VERSION ""

NS_ :

BS_:

BU_: VMCU VGGSECUSystem TECU OBDScanT2 HMIIOM EMS ECUspare2 ECUspare1 DACU CIOM BBM

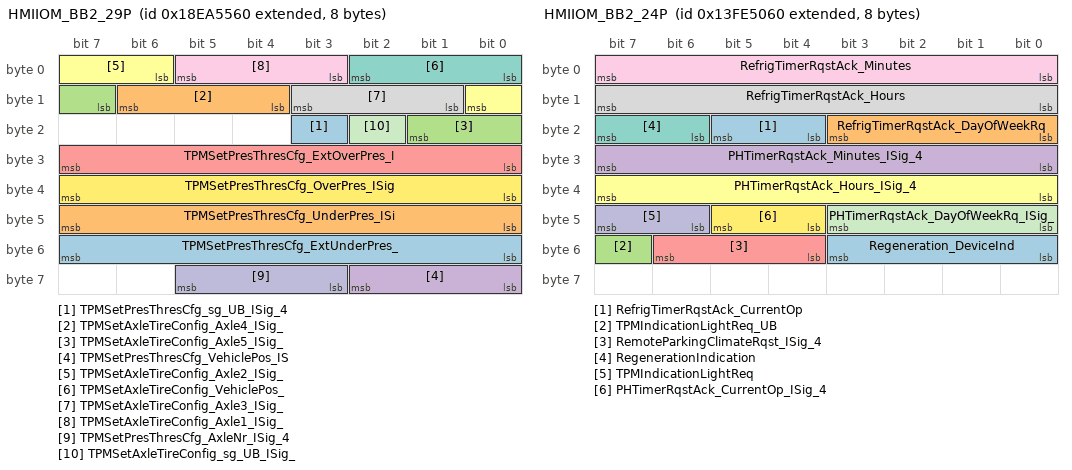
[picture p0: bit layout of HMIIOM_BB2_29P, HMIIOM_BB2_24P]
BO_ 2565494112 HMIIOM_BB2_29P: 8 HMIIOM
 SG_ TPMSetPresThresCfg_sg_UB_ISig_4 : 19|1@1+ (1,0) [0|0] ""  VMCU
 SG_ TPMSetAxleTireConfig_Axle4_ISig_ : 12|3@1+ (1,0) [0|0] ""  VMCU
 SG_ TPMSetAxleTireConfig_Axle5_ISig_ : 15|3@1+ (1,0) [0|0] ""  VMCU
 SG_ TPMSetPresThresCfg_VehiclePos_IS : 56|3@1+ (1,0) [0|0] ""  VMCU
 SG_ TPMSetPresThresCfg_ExtOverPres_I : 24|8@1+ (1,-125) [-125|130] "Percent"  VMCU
 SG_ TPMSetAxleTireConfig_Axle2_ISig_ : 6|3@1+ (1,0) [0|0] ""  VMCU
 SG_ TPMSetAxleTireConfig_VehiclePos_ : 0|3@1+ (1,0) [0|0] ""  VMCU
 SG_ TPMSetAxleTireConfig_Axle3_ISig_ : 9|3@1+ (1,0) [0|0] ""  VMCU
 SG_ TPMSetAxleTireConfig_Axle1_ISig_ : 3|3@1+ (1,0) [0|0] ""  VMCU
 SG_ TPMSetPresThresCfg_AxleNr_ISig_4 : 59|3@1+ (1,0) [0|0] ""  VMCU
 SG_ TPMSetAxleTireConfig_sg_UB_ISig_ : 18|1@1+ (1,0) [0|0] ""  VMCU
 SG_ TPMSetPresThresCfg_OverPres_ISig : 32|8@1+ (1,-125) [-125|130] "Percent"  VMCU
 SG_ TPMSetPresThresCfg_ExtUnderPres_ : 48|8@1+ (1,-125) [-125|130] "Percent"  VMCU
 SG_ TPMSetPresThresCfg_UnderPres_ISi : 40|8@1+ (1,-125) [-125|130] "Percent"  VMCU

BO_ 2582855520 HMIIOM_BB2_28S: 284 HMIIOM
 SG_ HillDataPkgTGW_ISig_4 : 0|2272@1+ (1,0) [0|0] ""  TECU

BO_ 2566356833 HMIIOM_BB2_27S_FCM: 8 CIOM
 SG_ HMIIOM_BB2_27S_FCS : 0|64@1+ (1,0) [0|0] ""  HMIIOM

BO_ 2566356832 HMIIOM_BB2_27S: 13 HMIIOM
 SG_ PHTimerTGWEvCmd_Timer3Minutes_IS : 64|8@1+ (1,0) [0|255] "min"  CIOM
 SG_ PHTimerTGWEvCmd_Timer1Temp_ISig_ : 8|5@1+ (1,0) [0|0] ""  CIOM
 SG_ PHTimerTGWEvCmd_Timer3StartDay_I : 40|4@1+ (1,0) [0|0] ""  CIOM
 SG_ PHTimerTGWEvCmd_Timer1Recur_ISig : 24|4@1+ (1,0) [0|0] ""  CIOM
 SG_ PHTimerTGWEvCmd_Timer3Recur_ISig : 28|4@1+ (1,0) [0|0] ""  CIOM
 SG_ PHTimerTGWEvCmd_Timer3Temp_ISig_ : 0|5@1+ (1,0) [0|0] ""  CIOM
 SG_ PHTimerTGWEvCmd_PhTimer3_cmd_ISi : 13|3@1+ (1,0) [0|0] ""  CIOM
 SG_ PHTimerTGWEvCmd_Timer1Hours_ISig : 56|8@1+ (1,0) [0|255] "h"  CIOM
 SG_ PHTimerTGWEvCmd_Timer1StartDay_I : 32|4@1+ (1,0) [0|0] ""  CIOM
 SG_ PHTimerTGWEvCmd_Timer2Minutes_IS : 72|8@1+ (1,0) [0|255] "min"  CIOM
 SG_ PHTimerTGWEvCmd_Timer2StartDay_I : 36|4@1+ (1,0) [0|0] ""  CIOM
 SG_ PHTimerTGWEvCmd_Timer2Temp_ISig_ : 16|5@1+ (1,0) [0|0] ""  CIOM
 SG_ PHTimerTGWEvCmd_Timer1Duration_I : 96|7@1+ (1,0) [0|127] "min"  CIOM
 SG_ PHTimerTGWEvCmd_Timer2Hours_ISig : 48|8@1+ (1,0) [0|255] "h"  CIOM
 SG_ PHTimerTGWEvCmd_Timer3Hours_ISig : 88|8@1+ (1,0) [0|255] "h"  CIOM
 SG_ PHTimerTGWEvCmd_PhTimer2_cmd_ISi : 21|3@1+ (1,0) [0|0] ""  CIOM
 SG_ PHTimerTGWEvCmd_Timer2Recur_ISig : 44|4@1+ (1,0) [0|0] ""  CIOM
 SG_ PHTimerTGWEvCmd_Timer1Minutes_IS : 80|8@1+ (1,0) [0|255] "min"  CIOM
 SG_ PHTimerTGWEvCmd_PhTimer1_cmd_ISi : 5|3@1+ (1,0) [0|0] ""  CIOM

BO_ 2515671136 HMIIOM_BB2_25P: 8 HMIIOM
 SG_ Trailer3LiftAxles_LiftAxle1Id_IS : 24|4@1+ (1,0) [0|15] "ID"  CIOM
 SG_ Trailer2LiftAxles_LiftAxle1Pos_I : 20|2@1+ (1,0) [0|0] ""  CIOM
 SG_ Trailer1LiftAxles_LiftAxle2Pos_I : 10|2@1+ (1,0) [0|0] ""  CIOM
 SG_ Trailer3LiftAxles_LiftAxle2Pos_I : 34|2@1+ (1,0) [0|0] ""  CIOM
 SG_ Trailer1LiftAxles_LiftAxle2Id_IS : 4|4@1+ (1,0) [0|15] "ID"  CIOM
 SG_ Trailer5LiftAxles_LiftAxle1Id_IS : 48|4@1+ (1,0) [0|15] "ID"  CIOM
 SG_ Trailer1LiftAxles_LiftAxle1Pos_I : 8|2@1+ (1,0) [0|0] ""  CIOM
 SG_ Trailer1LiftAxles_LiftAxle1Id_IS : 0|4@1+ (1,0) [0|15] "ID"  CIOM
 SG_ Trailer4LiftAxles_LiftAxle2Pos_I : 46|2@1+ (1,0) [0|0] ""  CIOM
 SG_ Trailer5LiftAxles_LiftAxle2Pos_I : 58|2@1+ (1,0) [0|0] ""  CIOM
 SG_ Trailer4LiftAxles_LiftAxle1Pos_I : 44|2@1+ (1,0) [0|0] ""  CIOM
 SG_ Trailer2LiftAxles_LiftAxle1Id_IS : 12|4@1+ (1,0) [0|15] "ID"  CIOM
 SG_ Trailer5LiftAxles_LiftAxle1Pos_I : 56|2@1+ (1,0) [0|0] ""  CIOM
 SG_ Trailer2LiftAxles_LiftAxle2Pos_I : 22|2@1+ (1,0) [0|0] ""  CIOM
 SG_ Trailer2LiftAxles_LiftAxle2Id_IS : 16|4@1+ (1,0) [0|15] "ID"  CIOM
 SG_ Trailer3LiftAxles_LiftAxle1Pos_I : 32|2@1+ (1,0) [0|0] ""  CIOM
 SG_ Trailer5LiftAxles_LiftAxle2Id_IS : 52|4@1+ (1,0) [0|15] "ID"  CIOM
 SG_ InhibRegeneration_DeviceInd : 62|2@1+ (1,0) [0|0] ""  CIOM
 SG_ Trailer4LiftAxles_LiftAxle1Id_IS : 36|4@1+ (1,0) [0|15] "ID"  CIOM
 SG_ Trailer3LiftAxles_LiftAxle2Id_IS : 28|4@1+ (1,0) [0|15] "ID"  CIOM
 SG_ Trailer4LiftAxles_LiftAxle2Id_IS : 40|4@1+ (1,0) [0|15] "ID"  CIOM

BO_ 2482917472 HMIIOM_BB2_24P: 8 HMIIOM
 SG_ RefrigTimerRqstAck_CurrentOp : 20|2@1+ (1,0) [0|0] ""  VMCU
 SG_ RefrigTimerRqstAck_DayOfWeekRq : 16|4@1+ (1,0) [0|0] ""  VMCU
 SG_ TPMIndicationLightReq_UB : 55|1@1+ (1,0) [0|0] ""  VMCU
 SG_ PHTimerRqstAck_Minutes_ISig_4 : 24|8@1+ (1,0) [0|255] "min"  CIOM
 SG_ RemoteParkingClimateRqst_ISig_4 : 52|3@1+ (1,0) [0|0] ""  CIOM
 SG_ PHTimerRqstAck_Hours_ISig_4 : 32|8@1+ (1,0) [0|255] "h"  CIOM
 SG_ RegenerationIndication : 22|2@1+ (1,0) [0|0] ""  CIOM
 SG_ RefrigTimerRqstAck_Hours : 8|8@1+ (1,0) [0|255] "h"  VMCU
 SG_ RefrigTimerRqstAck_Minutes : 0|8@1+ (1,0) [0|255] "min"  VMCU
 SG_ TPMIndicationLightReq : 46|2@1+ (1,0) [0|0] ""  VMCU
 SG_ PHTimerRqstAck_DayOfWeekRq_ISig_ : 40|4@1+ (1,0) [0|0] ""  CIOM
 SG_ PHTimerRqstAck_CurrentOp_ISig_4 : 44|2@1+ (1,0) [0|0] ""  CIOM
 SG_ Regeneration_DeviceInd : 48|4@1+ (1,0) [0|0] ""  CIOM

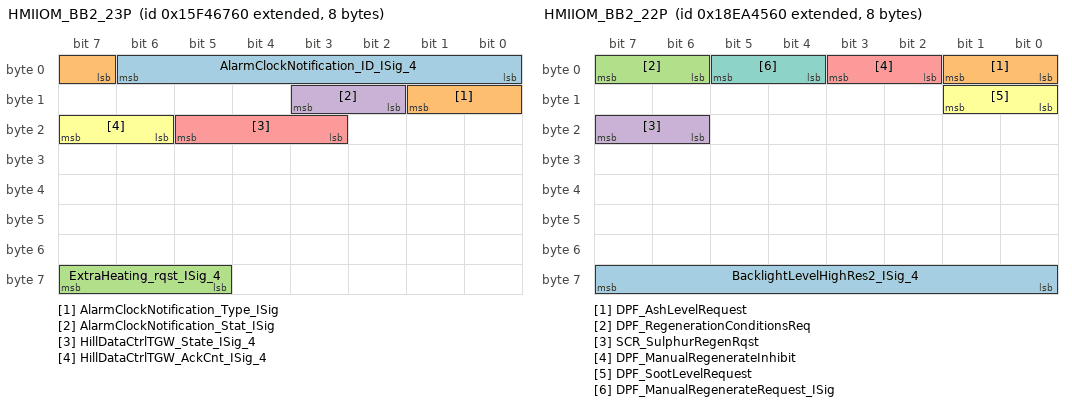
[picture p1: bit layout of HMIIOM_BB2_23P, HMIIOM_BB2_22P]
BO_ 2515822432 HMIIOM_BB2_23P: 8 HMIIOM
 SG_ AlarmClockNotification_ID_ISig_4 : 0|7@1+ (1,0) [0|0] ""  CIOM
 SG_ AlarmClockNotification_Type_ISig : 7|3@1+ (1,0) [0|0] ""  CIOM
 SG_ ExtraHeating_rqst_ISig_4 : 61|3@1+ (1,0) [0|0] ""  CIOM
 SG_ AlarmClockNotification_Stat_ISig : 10|2@1+ (1,0) [0|0] ""  CIOM
 SG_ HillDataCtrlTGW_State_ISig_4 : 19|3@1+ (1,0) [0|0] ""  TECU
 SG_ HillDataCtrlTGW_AckCnt_ISig_4 : 22|2@1+ (1,0) [0|3] ""  TECU

BO_ 2565490016 HMIIOM_BB2_22P: 8 HMIIOM
 SG_ BacklightLevelHighRes2_ISig_4 : 56|8@1+ (0.4,0) [0|102] "Percent"  CIOM,BBM,VMCU
 SG_ DPF_AshLevelRequest : 0|2@1+ (1,0) [0|0] ""  EMS
 SG_ DPF_RegenerationConditionsReq : 6|2@1+ (1,0) [0|0] ""  EMS
 SG_ SCR_SulphurRegenRqst : 22|2@1+ (1,0) [0|0] ""  EMS
 SG_ DPF_ManualRegenerateInhibit : 2|2@1+ (1,0) [0|0] ""  EMS
 SG_ DPF_SootLevelRequest : 8|2@1+ (1,0) [0|0] ""  EMS
 SG_ DPF_ManualRegenerateRequest_ISig : 4|2@1+ (1,0) [0|0] ""  EMS

BO_ 2499794017 HMIIOM_BB2_21S_FCM: 8 CIOM
 SG_ HMIIOM_BB2_21S_FCS : 0|64@1+ (1,0) [0|0] ""  HMIIOM

BO_ 2499794016 HMIIOM_BB2_21S: 36 HMIIOM
 SG_ DisplayText_stat_ISig_4 : 0|288@1+ (1,0) [0|0] ""  CIOM

BO_ 2566000481 HMIIOM_BB2_20S_FCM: 8 CIOM
 SG_ HMIIOM_BB2_20S_FCS : 0|64@1+ (1,0) [0|0] ""  HMIIOM

BO_ 2566000480 HMIIOM_BB2_20S: 11 HMIIOM
 SG_ ECU3VIN_stat : 0|88@1+ (1,0) [0|0] ""  CIOM

BO_ 2566268257 HMIIOM_BB2_19P_VMCU_FCM: 8 VMCU
 SG_ HMIIOM_BB2_19P_FCS_18f62561 : 0|64@1+ (1,0) [0|0] ""  HMIIOM

BO_ 2566268256 HMIIOM_BB2_19P_VMCU: 21 HMIIOM
 SG_ GPSData_Longitude_ISig_4_18f6256 : 0|32@1+ (1E-007,-210) [-210|219.4967295] "deg"  VMCU
 SG_ GPSData_sg_UB_ISig_4_18f62560 : 163|1@1+ (1,0) [0|1] ""  VMCU
 SG_ GPSData_Direction_ISig_4_18f6256 : 96|16@1+ (0.0078125,0) [0|511.9921875] "deg"  VMCU
 SG_ GPSData_Latitude_ISig_4_18f62560 : 32|32@1+ (1E-007,-210) [-210|219.4967295] "deg"  VMCU
 SG_ GPSData_Altitude_ISig_4_18f62560 : 144|16@1+ (0.125,-2500) [-2500|5691.875] "m"  VMCU
 SG_ GPSData_HDOP_ISig_4_18f62560 : 112|16@1+ (0.01,0) [0|655.35] ""  VMCU
 SG_ GPSData_Time_ISig_4_18f62560 : 64|32@1+ (1,0) [0|4294967295] "s"  VMCU
 SG_ GPSData_VehSpeed_ISig_4_18f62560 : 128|16@1+ (0.00390625,0) [0|255.99609375] "Km_per_h"  VMCU
 SG_ GPSData_AntennaStat_ISig_4_18f62 : 160|3@1+ (1,0) [0|0] ""  VMCU

BO_ 2566268001 HMIIOM_BB2_19P_TECU_FCM: 8 TECU
 SG_ HMIIOM_BB2_19P_FCS_18f62461 : 0|64@1+ (1,0) [0|0] ""  HMIIOM

BO_ 2566268000 HMIIOM_BB2_19P_TECU: 21 HMIIOM
 SG_ GPSData_HDOP_ISig_4_18f62460 : 112|16@1+ (0.01,0) [0|655.35] ""  TECU
 SG_ GPSData_VehSpeed_ISig_4_18f62460 : 128|16@1+ (0.00390625,0) [0|255.99609375] "Km_per_h"  TECU
 SG_ GPSData_Direction_ISig_4_18f6246 : 96|16@1+ (0.0078125,0) [0|511.9921875] "deg"  TECU
 SG_ GPSData_Longitude_ISig_4_18f6246 : 0|32@1+ (1E-007,-210) [-210|219.4967295] "deg"  TECU
 SG_ GPSData_sg_UB_ISig_4_18f62460 : 163|1@1+ (1,0) [0|1] ""  TECU
 SG_ GPSData_Time_ISig_4_18f62460 : 64|32@1+ (1,0) [0|4294967295] "s"  TECU
 SG_ GPSData_Latitude_ISig_4_18f62460 : 32|32@1+ (1E-007,-210) [-210|219.4967295] "deg"  TECU
 SG_ GPSData_AntennaStat_ISig_4__0000 : 160|3@1+ (1,0) [0|0] ""  TECU
 SG_ GPSData_Altitude_ISig_4_18f62460 : 144|16@1+ (0.125,-2500) [-2500|5691.875] "m"  TECU

BO_ 2566268513 HMIIOM_BB2_19P_DACU_FCM: 8 DACU
 SG_ HMIIOM_BB2_19P_FCS_18f62661 : 0|64@1+ (1,0) [0|0] ""  HMIIOM

BO_ 2566268512 HMIIOM_BB2_19P_DACU: 21 HMIIOM
 SG_ GPSData_HDOP_ISig_4_18f62660 : 112|16@1+ (0.01,0) [0|655.35] ""  DACU
 SG_ GPSData_VehSpeed_ISig_4_18f62660 : 128|16@1+ (0.00390625,0) [0|255.99609375] "Km_per_h"  DACU
 SG_ GPSData_sg_UB_ISig_4_18f62660 : 163|1@1+ (1,0) [0|1] ""  DACU
 SG_ GPSData_AntennaStat_ISig_4__0001 : 160|3@1+ (1,0) [0|0] ""  DACU
 SG_ GPSData_Latitude_ISig_4_18f62660 : 32|32@1+ (1E-007,-210) [-210|219.4967295] "deg"  DACU
 SG_ GPSData_Time_ISig_4_18f62660 : 64|32@1+ (1,0) [0|4294967295] "s"  DACU
 SG_ GPSData_Direction_ISig_4_18f6266 : 96|16@1+ (0.0078125,0) [0|511.9921875] "deg"  DACU
 SG_ GPSData_Longitude_ISig_4_18f6266 : 0|32@1+ (1E-007,-210) [-210|219.4967295] "deg"  DACU
 SG_ GPSData_Altitude_ISig_4_18f62660 : 144|16@1+ (0.125,-2500) [-2500|5691.875] "m"  DACU

BO_ 2566269025 HMIIOM_BB2_19P_CIOM_FCM: 8 CIOM
 SG_ HMIIOM_BB2_19P_FCS_18f62861 : 0|64@1+ (1,0) [0|0] ""  HMIIOM

BO_ 2566269024 HMIIOM_BB2_19P_CIOM: 21 HMIIOM
 SG_ GPSData_HDOP_ISig_4_18f62860 : 112|16@1+ (0.01,0) [0|655.35] ""  CIOM
 SG_ GPSData_Latitude_ISig_4_18f62860 : 32|32@1+ (1E-007,-210) [-210|219.4967295] "deg"  CIOM
 SG_ GPSData_Time_ISig_4_18f62860 : 64|32@1+ (1,0) [0|4294967295] "s"  CIOM
 SG_ GPSData_Direction_ISig_4_18f6286 : 96|16@1+ (0.0078125,0) [0|511.9921875] "deg"  CIOM
 SG_ GPSData_sg_UB_ISig_4_18f62860 : 163|1@1+ (1,0) [0|1] ""  CIOM
 SG_ GPSData_AntennaStat_ISig_4__0002 : 160|3@1+ (1,0) [0|0] ""  CIOM
 SG_ GPSData_Longitude_ISig_4_18f6286 : 0|32@1+ (1E-007,-210) [-210|219.4967295] "deg"  CIOM
 SG_ GPSData_VehSpeed_ISig_4_18f62860 : 128|16@1+ (0.00390625,0) [0|255.99609375] "Km_per_h"  CIOM
 SG_ GPSData_Altitude_ISig_4_18f62860 : 144|16@1+ (0.125,-2500) [-2500|5691.875] "m"  CIOM

BO_ 2566268769 HMIIOM_BB2_19P_BBM_FCM: 8 BBM
 SG_ HMIIOM_BB2_19P_FCS_18f62761 : 0|64@1+ (1,0) [0|0] ""  HMIIOM

BO_ 2566268768 HMIIOM_BB2_19P_BBM: 21 HMIIOM
 SG_ GPSData_Time_ISig_4_18f62760 : 64|32@1+ (1,0) [0|4294967295] "s"  BBM
 SG_ GPSData_HDOP_ISig_4_18f62760 : 112|16@1+ (0.01,0) [0|655.35] ""  BBM
 SG_ GPSData_Direction_ISig_4_18f6276 : 96|16@1+ (0.0078125,0) [0|511.9921875] "deg"  BBM
 SG_ GPSData_Longitude_ISig_4_18f6276 : 0|32@1+ (1E-007,-210) [-210|219.4967295] "deg"  BBM
 SG_ GPSData_sg_UB_ISig_4_18f62760 : 163|1@1+ (1,0) [0|1] ""  BBM
 SG_ GPSData_VehSpeed_ISig_4_18f62760 : 128|16@1+ (0.00390625,0) [0|255.99609375] "Km_per_h"  BBM
 SG_ GPSData_Altitude_ISig_4_18f62760 : 144|16@1+ (0.125,-2500) [-2500|5691.875] "m"  BBM
 SG_ GPSData_Latitude_ISig_4_18f62760 : 32|32@1+ (1E-007,-210) [-210|219.4967295] "deg"  BBM
 SG_ GPSData_AntennaStat_ISig_4__0003 : 160|3@1+ (1,0) [0|0] ""  BBM

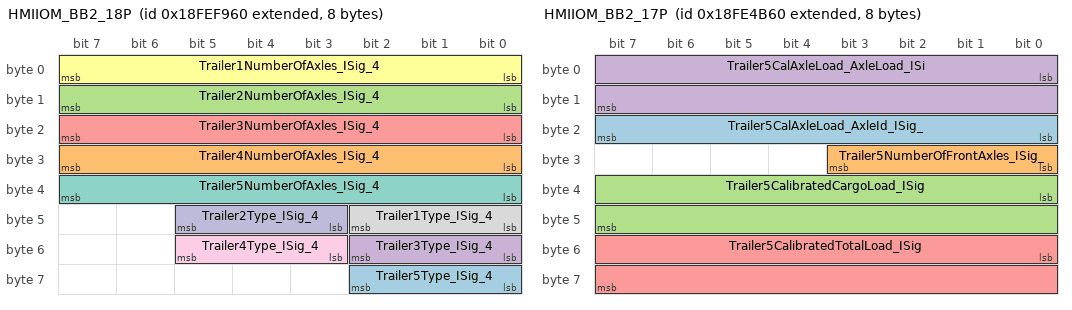
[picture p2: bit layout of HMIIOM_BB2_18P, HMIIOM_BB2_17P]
BO_ 2566846816 HMIIOM_BB2_18P: 8 HMIIOM
 SG_ Trailer5Type_ISig_4 : 56|3@1+ (1,0) [0|0] ""  CIOM
 SG_ Trailer4NumberOfAxles_ISig_4 : 24|8@1+ (1,0) [0|255] "NotApplicable"  CIOM
 SG_ Trailer2NumberOfAxles_ISig_4 : 8|8@1+ (1,0) [0|255] "NotApplicable"  CIOM
 SG_ Trailer3Type_ISig_4 : 48|3@1+ (1,0) [0|0] ""  CIOM
 SG_ Trailer3NumberOfAxles_ISig_4 : 16|8@1+ (1,0) [0|255] "NotApplicable"  CIOM
 SG_ Trailer1NumberOfAxles_ISig_4 : 0|8@1+ (1,0) [0|255] "NotApplicable"  CIOM
 SG_ Trailer5NumberOfAxles_ISig_4 : 32|8@1+ (1,0) [0|255] "NotApplicable"  CIOM
 SG_ Trailer1Type_ISig_4 : 40|3@1+ (1,0) [0|0] ""  CIOM
 SG_ Trailer4Type_ISig_4 : 51|3@1+ (1,0) [0|0] ""  CIOM
 SG_ Trailer2Type_ISig_4 : 43|3@1+ (1,0) [0|0] ""  CIOM

BO_ 2566802272 HMIIOM_BB2_17P: 8 HMIIOM
 SG_ Trailer5CalAxleLoad_AxleId_ISig_ : 16|8@1+ (1,0) [0|255] "NotApplicable"  VMCU,CIOM
 SG_ Trailer5NumberOfFrontAxles_ISig_ : 24|4@1+ (1,0) [0|15] "NotApplicable"  CIOM
 SG_ Trailer5CalibratedCargoLoad_ISig : 32|16@1+ (2,0) [0|131070] "kg"  CIOM,BBM,VMCU
 SG_ Trailer5CalAxleLoad_AxleLoad_ISi : 0|16@1+ (0.5,0) [0|32767.5] "kg"  VMCU,CIOM
 SG_ Trailer5CalibratedTotalLoad_ISig : 48|16@1+ (2,0) [0|131070] "kg"  VMCU,CIOM,BBM

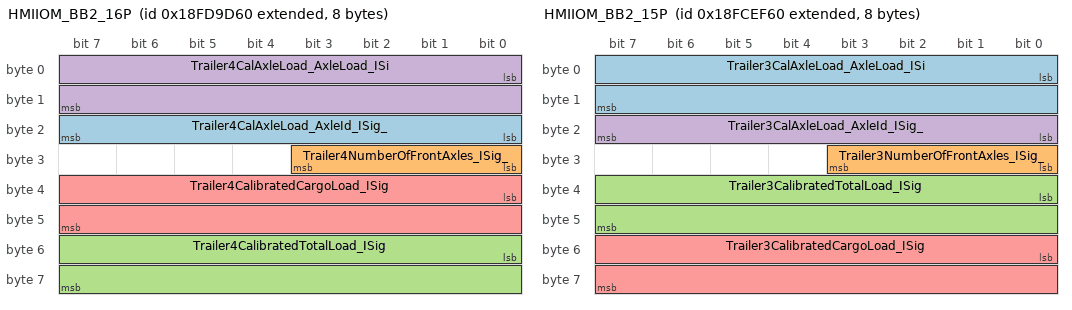
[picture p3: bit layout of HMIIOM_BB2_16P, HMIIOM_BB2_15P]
BO_ 2566757728 HMIIOM_BB2_16P: 8 HMIIOM
 SG_ Trailer4CalAxleLoad_AxleId_ISig_ : 16|8@1+ (1,0) [0|255] "NotApplicable"  VMCU,CIOM
 SG_ Trailer4NumberOfFrontAxles_ISig_ : 24|4@1+ (1,0) [0|15] "NotApplicable"  CIOM
 SG_ Trailer4CalibratedTotalLoad_ISig : 48|16@1+ (2,0) [0|131070] "kg"  CIOM,BBM,VMCU
 SG_ Trailer4CalAxleLoad_AxleLoad_ISi : 0|16@1+ (0.5,0) [0|32767.5] "kg"  VMCU,CIOM
 SG_ Trailer4CalibratedCargoLoad_ISig : 32|16@1+ (2,0) [0|131070] "kg"  CIOM,VMCU,BBM

BO_ 2566713184 HMIIOM_BB2_15P: 8 HMIIOM
 SG_ Trailer3CalAxleLoad_AxleLoad_ISi : 0|16@1+ (0.5,0) [0|32767.5] "kg"  VMCU,CIOM
 SG_ Trailer3NumberOfFrontAxles_ISig_ : 24|4@1+ (1,0) [0|15] "NotApplicable"  CIOM
 SG_ Trailer3CalibratedTotalLoad_ISig : 32|16@1+ (2,0) [0|131070] "kg"  VMCU,CIOM,BBM
 SG_ Trailer3CalAxleLoad_AxleId_ISig_ : 16|8@1+ (1,0) [0|255] "NotApplicable"  VMCU,CIOM
 SG_ Trailer3CalibratedCargoLoad_ISig : 48|16@1+ (2,0) [0|131070] "kg"  VMCU,BBM,CIOM

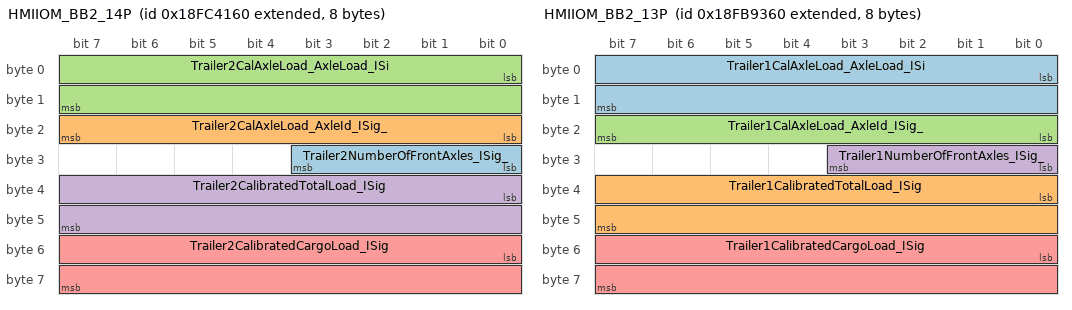
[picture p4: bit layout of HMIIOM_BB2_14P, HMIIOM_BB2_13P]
BO_ 2566668640 HMIIOM_BB2_14P: 8 HMIIOM
 SG_ Trailer2NumberOfFrontAxles_ISig_ : 24|4@1+ (1,0) [0|15] "NotApplicable"  CIOM
 SG_ Trailer2CalAxleLoad_AxleId_ISig_ : 16|8@1+ (1,0) [0|255] "NotApplicable"  CIOM,VMCU
 SG_ Trailer2CalAxleLoad_AxleLoad_ISi : 0|16@1+ (0.5,0) [0|32767.5] "kg"  VMCU,CIOM
 SG_ Trailer2CalibratedTotalLoad_ISig : 32|16@1+ (2,0) [0|131070] "kg"  CIOM,BBM,VMCU
 SG_ Trailer2CalibratedCargoLoad_ISig : 48|16@1+ (2,0) [0|131070] "kg"  CIOM,VMCU,BBM

BO_ 2566624096 HMIIOM_BB2_13P: 8 HMIIOM
 SG_ Trailer1CalAxleLoad_AxleLoad_ISi : 0|16@1+ (0.5,0) [0|32767.5] "kg"  CIOM,VMCU
 SG_ Trailer1CalibratedTotalLoad_ISig : 32|16@1+ (2,0) [0|131070] "kg"  VMCU,CIOM,BBM
 SG_ Trailer1CalAxleLoad_AxleId_ISig_ : 16|8@1+ (1,0) [0|255] "NotApplicable"  CIOM,VMCU
 SG_ Trailer1NumberOfFrontAxles_ISig_ : 24|4@1+ (1,0) [0|15] "NotApplicable"  CIOM
 SG_ Trailer1CalibratedCargoLoad_ISig : 48|16@1+ (2,0) [0|131070] "kg"  VMCU,CIOM,BBM

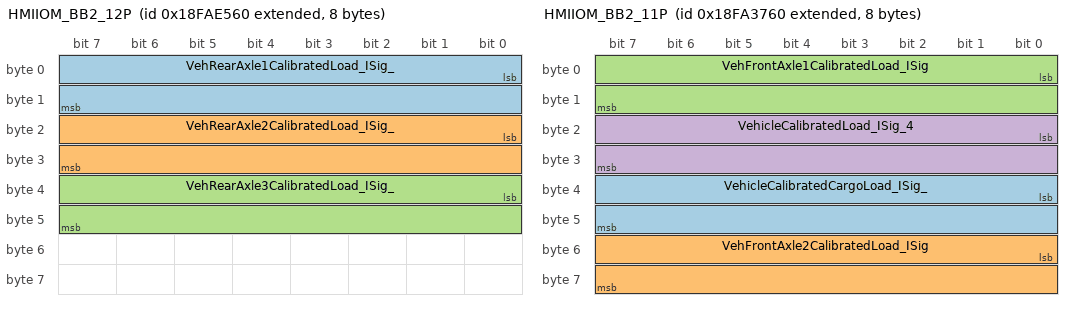
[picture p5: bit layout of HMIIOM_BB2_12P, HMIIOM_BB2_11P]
BO_ 2566579552 HMIIOM_BB2_12P: 8 HMIIOM
 SG_ VehRearAxle1CalibratedLoad_ISig_ : 0|16@1+ (0.5,0) [0|32767.5] "kg"  CIOM,BBM,VMCU
 SG_ VehRearAxle2CalibratedLoad_ISig_ : 16|16@1+ (0.5,0) [0|32767.5] "kg"  VMCU,BBM,CIOM
 SG_ VehRearAxle3CalibratedLoad_ISig_ : 32|16@1+ (0.5,0) [0|32767.5] "kg"  VMCU,CIOM,BBM

BO_ 2566535008 HMIIOM_BB2_11P: 8 HMIIOM
 SG_ VehicleCalibratedCargoLoad_ISig_ : 32|16@1+ (2,0) [0|131070] "kg"  CIOM,VMCU
 SG_ VehFrontAxle2CalibratedLoad_ISig : 48|16@1+ (0.5,0) [0|32767.5] "kg"  VMCU,CIOM,BBM
 SG_ VehFrontAxle1CalibratedLoad_ISig : 0|16@1+ (0.5,0) [0|32767.5] "kg"  BBM,VMCU,CIOM
 SG_ VehicleCalibratedLoad_ISig_4 : 16|16@1+ (2,0) [0|131070] "kg"  VMCU,BBM,CIOM,DACU

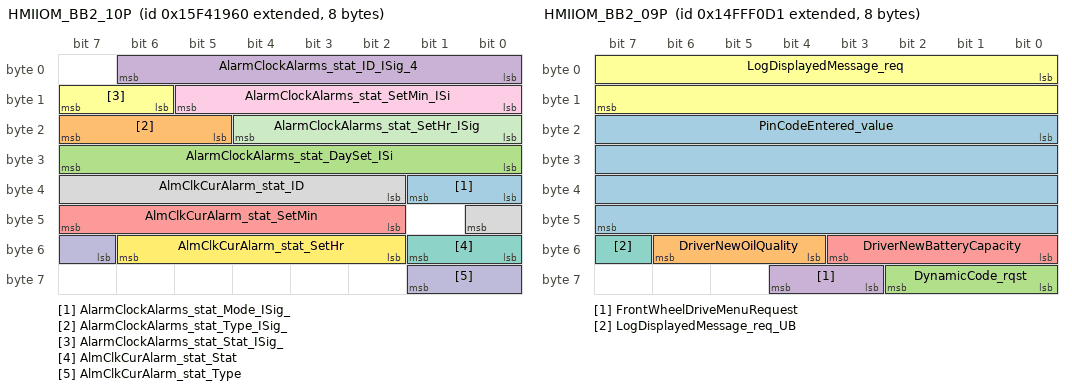
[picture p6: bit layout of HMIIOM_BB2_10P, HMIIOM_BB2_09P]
BO_ 2515802464 HMIIOM_BB2_10P: 8 HMIIOM
 SG_ AlarmClockAlarms_stat_Mode_ISig_ : 32|2@1+ (1,0) [0|0] ""  CIOM
 SG_ AlarmClockAlarms_stat_Type_ISig_ : 21|3@1+ (1,0) [0|0] ""  CIOM
 SG_ AlarmClockAlarms_stat_DaySet_ISi : 24|8@1+ (1,0) [0|255] ""  CIOM
 SG_ AlarmClockAlarms_stat_ID_ISig_4 : 0|7@1+ (1,0) [0|0] ""  CIOM
 SG_ AlmClkCurAlarm_stat_SetMin : 42|6@1+ (1,0) [0|63] "min"  CIOM
 SG_ AlarmClockAlarms_stat_Stat_ISig_ : 14|2@1+ (1,0) [0|0] ""  CIOM
 SG_ AlmClkCurAlarm_stat_Stat : 48|2@1+ (1,0) [0|0] ""  CIOM
 SG_ AlmClkCurAlarm_stat_ID : 34|7@1+ (1,0) [0|0] ""  CIOM
 SG_ AlarmClockAlarms_stat_SetMin_ISi : 8|6@1+ (1,0) [0|63] "min"  CIOM
 SG_ AlmClkCurAlarm_stat_Type : 55|3@1+ (1,0) [0|0] ""  CIOM
 SG_ AlarmClockAlarms_stat_SetHr_ISig : 16|5@1+ (1,0) [0|31] "h"  CIOM
 SG_ AlmClkCurAlarm_stat_SetHr : 50|5@1+ (1,0) [0|31] "h"  CIOM

BO_ 2499801297 HMIIOM_BB2_09P: 8 HMIIOM
 SG_ PinCodeEntered_value : 16|32@1+ (1,0) [0|4294967295] "NotApplicable"  CIOM
 SG_ DriverNewOilQuality : 52|3@1+ (1,0) [0|0] ""  VMCU
 SG_ DynamicCode_rqst : 56|3@1+ (1,0) [0|0] ""  CIOM
 SG_ FrontWheelDriveMenuRequest : 59|2@1+ (1,0) [0|0] ""  VMCU
 SG_ DriverNewBatteryCapacity : 48|4@1+ (1,0) [0|0] ""  VMCU
 SG_ LogDisplayedMessage_req : 0|16@1+ (1,0) [0|65535] "NotApplicable"  VMCU
 SG_ LogDisplayedMessage_req_UB : 55|1@1+ (1,0) [0|0] ""  VMCU

BO_ 2499794044 HMIIOM_BB2_08P: 8 HMIIOM
 SG_ FirstAxleLowerPrioRequested_ISig : 18|3@1+ (1,0) [0|0] ""  VMCU
 SG_ MaintInfo_rqst_ISig_4 : 36|2@1+ (1,0) [0|0] ""  VMCU
 SG_ Synch_Unsynch_Mode_stat : 29|3@1+ (1,0) [0|0] ""  CIOM
 SG_ FirstAxleLowerPrioRequested_UB_I : 58|1@1+ (1,0) [0|0] ""  VMCU
 SG_ MaintResetRqst_ID : 2|6@1+ (1,0) [0|0] ""  VMCU
 SG_ TrailerBrakeInputStatus_UB : 14|1@1+ (1,0) [0|0] ""  VMCU
 SG_ TrailerBrakeInputStatus : 21|3@1+ (1,0) [0|0] ""  VMCU
 SG_ MaintResetRqst_StatusRqst : 0|2@1+ (1,0) [0|0] ""  VMCU
 SG_ SelectedSpeedUnit_stat_ISig_4 : 34|2@1+ (1,0) [0|0] ""  VMCU
 SG_ SelectedLanguage_stat_ISig_4 : 40|6@1+ (1,0) [0|0] ""  BBM,CIOM
 SG_ LampCheck_rqst_ISig_4 : 59|2@1+ (1,0) [0|0] ""  VMCU
 SG_ ParkingHeaterCleaning_cmd_ISig_4 : 10|2@1+ (1,0) [0|0] ""  CIOM
 SG_ SelectedWeightUnit_stat_ISig_4 : 46|2@1+ (1,0) [0|0] ""  CIOM
 SG_ SpeedLockingInhibition_stat : 53|3@1+ (1,0) [0|0] ""  CIOM
 SG_ MaintInfoRqst : 32|2@1+ (1,0) [0|0] ""  VMCU
 SG_ ParkHeaterTimerReleased_stat_ISi : 16|2@1+ (1,0) [0|0] ""  CIOM
 SG_ DriverMemory_rqst_ISig_4 : 24|5@1+ (1,0) [0|0] ""  CIOM,VMCU
 SG_ SelectedTimeFormat_stat_ISig_4 : 8|2@1+ (1,0) [0|0] ""  CIOM
 SG_ RefrigTimerReleased_stat : 56|2@1+ (1,0) [0|0] ""  VMCU
 SG_ LCSSoundSettingRequest : 12|2@1+ (1,0) [0|0] ""  DACU

CM_ SG_ 2566356832 PHTimerTGWEvCmd_Timer3Minutes_IS "254 Error ; 255 Not available";
CM_ SG_ 2566356832 PHTimerTGWEvCmd_Timer1Hours_ISig "254 Error ; 255 Not available";
CM_ SG_ 2566356832 PHTimerTGWEvCmd_Timer2Minutes_IS "254 Error ; 255 Not available";
CM_ SG_ 2566356832 PHTimerTGWEvCmd_Timer1Duration_I "126 Error ; 127 Not available";
CM_ SG_ 2566356832 PHTimerTGWEvCmd_Timer2Hours_ISig "254 Error ; 255 Not available";
CM_ SG_ 2566356832 PHTimerTGWEvCmd_Timer3Hours_ISig "254 Error ; 255 Not available";
CM_ SG_ 2566356832 PHTimerTGWEvCmd_Timer1Minutes_IS "254 Error ; 255 Not available";
CM_ SG_ 2566268256 GPSData_Longitude_ISig_4_18f6256 "4261412864-4278190079 Error ; 4278190080-4294967295 Not available";
CM_ SG_ 2566268256 GPSData_Latitude_ISig_4_18f62560 "4261412864-4278190079 Error ; 4278190080-4294967295 Not available";
CM_ SG_ 2566268256 GPSData_Time_ISig_4_18f62560 "4261412864 - 4278190079 Error ; 4278190080 - 4294967295 Not available";
CM_ SG_ 2566268256 GPSData_VehSpeed_ISig_4_18f62560 "65024 - 65279 Error ; 65280 - 65535 Not available";
CM_ SG_ 2566268000 GPSData_VehSpeed_ISig_4_18f62460 "65024 - 65279 Error ; 65280 - 65535 Not available";
CM_ SG_ 2566268000 GPSData_Longitude_ISig_4_18f6246 "4261412864-4278190079 Error ; 4278190080-4294967295 Not available";
CM_ SG_ 2566268000 GPSData_Time_ISig_4_18f62460 "4261412864 - 4278190079 Error ; 4278190080 - 4294967295 Not available";
CM_ SG_ 2566268000 GPSData_Latitude_ISig_4_18f62460 "4261412864-4278190079 Error ; 4278190080-4294967295 Not available";
CM_ SG_ 2566268512 GPSData_VehSpeed_ISig_4_18f62660 "65024 - 65279 Error ; 65280 - 65535 Not available";
CM_ SG_ 2566268512 GPSData_Latitude_ISig_4_18f62660 "4261412864-4278190079 Error ; 4278190080-4294967295 Not available";
CM_ SG_ 2566268512 GPSData_Time_ISig_4_18f62660 "4261412864 - 4278190079 Error ; 4278190080 - 4294967295 Not available";
CM_ SG_ 2566268512 GPSData_Longitude_ISig_4_18f6266 "4261412864-4278190079 Error ; 4278190080-4294967295 Not available";
CM_ SG_ 2566269024 GPSData_Latitude_ISig_4_18f62860 "4261412864-4278190079 Error ; 4278190080-4294967295 Not available";
CM_ SG_ 2566269024 GPSData_Time_ISig_4_18f62860 "4261412864 - 4278190079 Error ; 4278190080 - 4294967295 Not available";
CM_ SG_ 2566269024 GPSData_Longitude_ISig_4_18f6286 "4261412864-4278190079 Error ; 4278190080-4294967295 Not available";
CM_ SG_ 2566269024 GPSData_VehSpeed_ISig_4_18f62860 "65024 - 65279 Error ; 65280 - 65535 Not available";
CM_ SG_ 2566268768 GPSData_Time_ISig_4_18f62760 "4261412864 - 4278190079 Error ; 4278190080 - 4294967295 Not available";
CM_ SG_ 2566268768 GPSData_Longitude_ISig_4_18f6276 "4261412864-4278190079 Error ; 4278190080-4294967295 Not available";
CM_ SG_ 2566268768 GPSData_VehSpeed_ISig_4_18f62760 "65024 - 65279 Error ; 65280 - 65535 Not available";
CM_ SG_ 2566268768 GPSData_Latitude_ISig_4_18f62760 "4261412864-4278190079 Error ; 4278190080-4294967295 Not available";
CM_ SG_ 2566846816 Trailer4NumberOfAxles_ISig_4 "254 Error ; 255 Not Available";
CM_ SG_ 2566846816 Trailer2NumberOfAxles_ISig_4 "254 Error ; 255 Not Available";
CM_ SG_ 2566846816 Trailer3NumberOfAxles_ISig_4 "254 Error ; 255 Not Available";
CM_ SG_ 2566846816 Trailer1NumberOfAxles_ISig_4 "254 Error ; 255 Not Available";
CM_ SG_ 2566846816 Trailer5NumberOfAxles_ISig_4 "254 Error ; 255 Not Available";
CM_ SG_ 2566802272 Trailer5CalibratedCargoLoad_ISig "65024 - 65279 Error ; 65280 - 65535 Not Available";
CM_ SG_ 2566802272 Trailer5CalAxleLoad_AxleLoad_ISi "65024 - 65279 Error ; 65280 - 65535 Not available";
CM_ SG_ 2566802272 Trailer5CalibratedTotalLoad_ISig "65024 - 65279 Error ; 65280 - 65535 Not Available";
CM_ SG_ 2566757728 Trailer4CalibratedTotalLoad_ISig "65024 - 65279 Error ; 65280 - 65535 Not Available";
CM_ SG_ 2566757728 Trailer4CalAxleLoad_AxleLoad_ISi "65024 - 65279 Error ; 65280 - 65535 Not available";
CM_ SG_ 2566757728 Trailer4CalibratedCargoLoad_ISig "65024 - 65279 Error ; 65280 - 65535 Not Available";
CM_ SG_ 2566713184 Trailer3CalAxleLoad_AxleLoad_ISi "65024 - 65279 Error ; 65280 - 65535 Not available";
CM_ SG_ 2566713184 Trailer3CalibratedTotalLoad_ISig "65024 - 65279 Error ; 65280 - 65535 Not Available";
CM_ SG_ 2566713184 Trailer3CalibratedCargoLoad_ISig "65024 - 65279 Error ; 65280 - 65535 Not Available";
CM_ SG_ 2566668640 Trailer2CalAxleLoad_AxleLoad_ISi "65024 - 65279 Error ; 65280 - 65535 Not available";
CM_ SG_ 2566668640 Trailer2CalibratedTotalLoad_ISig "65024 - 65279 Error ; 65280 - 65535 Not Available";
CM_ SG_ 2566668640 Trailer2CalibratedCargoLoad_ISig "65024 - 65279 Error ; 65280 - 65535 Not Available";
CM_ SG_ 2566624096 Trailer1CalAxleLoad_AxleLoad_ISi "65024 - 65279 Error ; 65280 - 65535 Not available";
CM_ SG_ 2566624096 Trailer1CalibratedTotalLoad_ISig "65024 - 65279 Error ; 65280 - 65535 Not Available";
CM_ SG_ 2566624096 Trailer1CalibratedCargoLoad_ISig "65024 - 65279 Error ; 65280 - 65535 Not Available";
CM_ SG_ 2566579552 VehRearAxle1CalibratedLoad_ISig_ "65024 - 65279 Error ; 65280 - 65535 Not available";
CM_ SG_ 2566579552 VehRearAxle2CalibratedLoad_ISig_ "65024 - 65279 Error ; 65280 - 65535 Not available";
CM_ SG_ 2566579552 VehRearAxle3CalibratedLoad_ISig_ "65024 - 65279 Error ; 65280 - 65535 Not available";
CM_ SG_ 2566535008 VehicleCalibratedCargoLoad_ISig_ "65024 - 65279 Error ; 65280 - 65535 Not Available";
CM_ SG_ 2566535008 VehFrontAxle2CalibratedLoad_ISig "65024 - 65279 Error ; 65280 - 65535 Not available";
CM_ SG_ 2566535008 VehFrontAxle1CalibratedLoad_ISig "65024 - 65279 Error ; 65280 - 65535 Not available";
CM_ SG_ 2566535008 VehicleCalibratedLoad_ISig_4 "65024 - 65279 Error ; 65280 - 65535 Not Available";
CM_ SG_ 2515802464 AlmClkCurAlarm_stat_SetMin "62 Error ; 63 Not Available";
CM_ SG_ 2515802464 AlarmClockAlarms_stat_SetMin_ISi "62 Error ; 63 Not Available";
CM_ SG_ 2515802464 AlarmClockAlarms_stat_SetHr_ISig "30 Error ; 31 Not Available";
CM_ SG_ 2515802464 AlmClkCurAlarm_stat_SetHr "30 Error ; 31 Not Available";
BA_DEF_ BO_  "GenMsgStartDelayTime" INT 0 0;
BA_DEF_ BO_  "GenMsgDelayTime" INT 0 0;
BA_DEF_ BO_  "GenMsgCycleTime" INT 0 0;
BA_DEF_ BO_  "GenMsgSendType" ENUM  "Cyclic","NotUsed","NotUsed","NotUsed","NotUsed","NotUsed","NotUsed","IfActive","NoMsgSendType","NotUsed";
BA_DEF_ SG_  "GenSigStartValue" INT 0 0;
BA_DEF_ SG_  "GenSigCycleTimeActive" INT 0 0;
BA_DEF_ SG_  "GenSigCycleTime" INT 0 0;
BA_DEF_ SG_  "GenSigSendType" ENUM  "Cyclic","OnWrite","OnWriteWithRepetition","OnChange","OnChangeWithRepetition","IfActive","IfActiveWithRepetition","NoSigSendType","NotUsed","NotUsed","NotUsed","NotUsed","NotUsed";
BA_DEF_ BO_  "VFrameFormat" ENUM  "StandardCAN","ExtendedCAN","reserved","J1939PG";
BA_DEF_ SG_  "SigType" ENUM  "Default","Range","RangeSigned","ASCII","Discrete","Control","ReferencePGN","DTC","StringDelimiter","StringLength","StringLengthControl";
BA_DEF_ SG_  "SeToolVersion_SIGNAL" STRING ;
BA_DEF_ SG_  "SeToolUniqueID_SIGNAL" STRING ;
BA_DEF_ SG_  "SeToolOwnerSigGroup_SIGNAL" STRING ;
BA_DEF_ SG_  "SeToolOwnerSigGroupID_SIGNAL" STRING ;
BA_DEF_ SG_  "SeToolName_SIGNAL" STRING ;
BA_DEF_ SG_  "SeToolItemID_SIGNAL" STRING ;
BA_DEF_ SG_  "SeToolAncestorID_SIGNAL" STRING ;
BA_DEF_ SG_  "Platform_VMCU1_Sig" ENUM  "No","Yes";
BA_DEF_ BO_  "NmAsrMessage" ENUM  "No","Yes";
BA_DEF_ SG_  "NeedsUpdateBit" ENUM  "No","Yes";
BA_DEF_ SG_  "MmAnSignal" ENUM  "No","Yes";
BA_DEF_ SG_  "GenSigMaxLatency" INT 0 65535;
BA_DEF_ SG_  "GenSigILSupport" ENUM  "Yes","No";
BA_DEF_ BO_  "GenMsgRequestable" INT 0 1;
BA_DEF_ BO_  "GenMsgILSupport" ENUM  "No","Yes";
BA_DEF_ BO_  "DiagUUDTResponse" ENUM  "No","Yes";
BA_DEF_ BO_  "DiagState" ENUM  "No","Yes";
BA_DEF_ BO_  "DiagResponse" ENUM  "No","Yes";
BA_DEF_ BO_  "DiagRequest" ENUM  "No","Yes";
BA_DEF_ BO_  "DiagConnection" HEX 0 65535;
BA_DEF_ BO_  "CanTpSTmin" INT 0 255;
BA_DEF_ BO_  "CanTpFcFrameId" HEX 0 2147483647;
BA_DEF_ BO_  "CanTpBs" INT 0 255;
BA_DEF_ SG_  "SystemSignalLongSymbol" STRING ;
BA_DEF_REL_ BU_SG_REL_  "GenSigTimeoutTime" INT 0 65535;
BA_DEF_REL_ BU_SG_REL_  "GenSigFirstTimeoutTime" INT 0 65535;
BA_DEF_DEF_  "GenMsgStartDelayTime" 0;
BA_DEF_DEF_  "GenMsgDelayTime" 0;
BA_DEF_DEF_  "GenMsgCycleTime" 0;
BA_DEF_DEF_  "GenMsgSendType" "Cyclic";
BA_DEF_DEF_  "GenSigStartValue" 0;
BA_DEF_DEF_  "GenSigCycleTimeActive" 0;
BA_DEF_DEF_  "GenSigCycleTime" 0;
BA_DEF_DEF_  "GenSigSendType" "Cyclic";
BA_DEF_DEF_  "VFrameFormat" "ExtendedCAN";
BA_DEF_DEF_  "SigType" "Default";
BA_DEF_DEF_  "SeToolVersion_SIGNAL" "";
BA_DEF_DEF_  "SeToolUniqueID_SIGNAL" "";
BA_DEF_DEF_  "SeToolOwnerSigGroup_SIGNAL" "";
BA_DEF_DEF_  "SeToolOwnerSigGroupID_SIGNAL" "";
BA_DEF_DEF_  "SeToolName_SIGNAL" "";
BA_DEF_DEF_  "SeToolItemID_SIGNAL" "";
BA_DEF_DEF_  "SeToolAncestorID_SIGNAL" "";
BA_DEF_DEF_  "Platform_VMCU1_Sig" "No";
BA_DEF_DEF_  "NmAsrMessage" "No";
BA_DEF_DEF_  "NeedsUpdateBit" "No";
BA_DEF_DEF_  "MmAnSignal" "No";
BA_DEF_DEF_  "GenSigMaxLatency" 0;
BA_DEF_DEF_  "GenSigILSupport" "Yes";
BA_DEF_DEF_  "GenMsgRequestable" 1;
BA_DEF_DEF_  "GenMsgILSupport" "Yes";
BA_DEF_DEF_  "DiagUUDTResponse" "No";
BA_DEF_DEF_  "DiagState" "No";
BA_DEF_DEF_  "DiagResponse" "No";
BA_DEF_DEF_  "DiagRequest" "No";
BA_DEF_DEF_  "DiagConnection" 0;
BA_DEF_DEF_  "CanTpSTmin" 0;
BA_DEF_DEF_  "CanTpFcFrameId" 2147483647;
BA_DEF_DEF_  "CanTpBs" 255;
BA_DEF_DEF_REL_ "GenSigTimeoutTime" 0;
BA_DEF_DEF_REL_ "GenSigFirstTimeoutTime" 0;
BA_DEF_DEF_  "SystemSignalLongSymbol" "";
BA_ "GenMsgCycleTime" BO_ 2565494112 500;
BA_ "GenMsgStartDelayTime" BO_ 2565494112 100;
BA_ "CanTpFcFrameId" BO_ 2582855520 435371873;
BA_ "CanTpSTmin" BO_ 2582855520 5;
BA_ "GenMsgSendType" BO_ 2582855520 8;
BA_ "GenMsgDelayTime" BO_ 2582855520 2400;
BA_ "GenMsgStartDelayTime" BO_ 2582855520 50;
BA_ "GenMsgILSupport" BO_ 2566356833 0;
BA_ "GenMsgSendType" BO_ 2566356833 8;
BA_ "CanTpFcFrameId" BO_ 2566356832 418873185;
BA_ "GenMsgSendType" BO_ 2566356832 8;
BA_ "GenMsgDelayTime" BO_ 2566356832 90;
BA_ "GenMsgStartDelayTime" BO_ 2566356832 50;
BA_ "GenMsgCycleTime" BO_ 2515671136 100;
BA_ "GenMsgCycleTime" BO_ 2482917472 50;
BA_ "GenMsgCycleTime" BO_ 2515822432 150;
BA_ "GenMsgStartDelayTime" BO_ 2515822432 35;
BA_ "GenMsgCycleTime" BO_ 2565490016 500;
BA_ "GenMsgDelayTime" BO_ 2565490016 100;
BA_ "GenMsgStartDelayTime" BO_ 2565490016 10;
BA_ "GenMsgILSupport" BO_ 2499794017 0;
BA_ "GenMsgSendType" BO_ 2499794017 8;
BA_ "CanTpFcFrameId" BO_ 2499794016 352310369;
BA_ "GenMsgSendType" BO_ 2499794016 8;
BA_ "GenMsgDelayTime" BO_ 2499794016 150;
BA_ "GenMsgStartDelayTime" BO_ 2499794016 50;
BA_ "GenMsgILSupport" BO_ 2566000481 0;
BA_ "GenMsgSendType" BO_ 2566000481 8;
BA_ "CanTpFcFrameId" BO_ 2566000480 418516833;
BA_ "GenMsgSendType" BO_ 2566000480 8;
BA_ "GenMsgDelayTime" BO_ 2566000480 110;
BA_ "GenMsgStartDelayTime" BO_ 2566000480 50;
BA_ "GenMsgILSupport" BO_ 2566268257 0;
BA_ "GenMsgSendType" BO_ 2566268257 8;
BA_ "CanTpFcFrameId" BO_ 2566268256 418784609;
BA_ "GenMsgCycleTime" BO_ 2566268256 500;
BA_ "GenMsgILSupport" BO_ 2566268001 0;
BA_ "GenMsgSendType" BO_ 2566268001 8;
BA_ "CanTpFcFrameId" BO_ 2566268000 418784353;
BA_ "GenMsgCycleTime" BO_ 2566268000 500;
BA_ "GenMsgStartDelayTime" BO_ 2566268000 50;
BA_ "GenMsgILSupport" BO_ 2566268513 0;
BA_ "GenMsgSendType" BO_ 2566268513 8;
BA_ "CanTpFcFrameId" BO_ 2566268512 418784865;
BA_ "GenMsgCycleTime" BO_ 2566268512 500;
BA_ "GenMsgStartDelayTime" BO_ 2566268512 105;
BA_ "GenMsgILSupport" BO_ 2566269025 0;
BA_ "GenMsgSendType" BO_ 2566269025 8;
BA_ "CanTpFcFrameId" BO_ 2566269024 418785377;
BA_ "GenMsgCycleTime" BO_ 2566269024 500;
BA_ "GenMsgStartDelayTime" BO_ 2566269024 210;
BA_ "GenMsgILSupport" BO_ 2566268769 0;
BA_ "GenMsgSendType" BO_ 2566268769 8;
BA_ "CanTpFcFrameId" BO_ 2566268768 418785121;
BA_ "GenMsgCycleTime" BO_ 2566268768 500;
BA_ "GenMsgStartDelayTime" BO_ 2566268768 150;
BA_ "GenMsgCycleTime" BO_ 2566846816 1000;
BA_ "GenMsgStartDelayTime" BO_ 2566846816 90;
BA_ "GenMsgCycleTime" BO_ 2566802272 1000;
BA_ "GenMsgStartDelayTime" BO_ 2566802272 185;
BA_ "GenMsgCycleTime" BO_ 2566757728 1000;
BA_ "GenMsgStartDelayTime" BO_ 2566757728 270;
BA_ "GenMsgCycleTime" BO_ 2566713184 1000;
BA_ "GenMsgStartDelayTime" BO_ 2566713184 365;
BA_ "GenMsgCycleTime" BO_ 2566668640 1000;
BA_ "GenMsgStartDelayTime" BO_ 2566668640 460;
BA_ "GenMsgCycleTime" BO_ 2566624096 1000;
BA_ "GenMsgStartDelayTime" BO_ 2566624096 555;
BA_ "GenMsgCycleTime" BO_ 2566579552 1000;
BA_ "GenMsgStartDelayTime" BO_ 2566579552 650;
BA_ "GenMsgCycleTime" BO_ 2566535008 1000;
BA_ "GenMsgStartDelayTime" BO_ 2566535008 745;
BA_ "GenMsgCycleTime" BO_ 2515802464 150;
BA_ "GenMsgStartDelayTime" BO_ 2515802464 55;
BA_ "GenMsgCycleTime" BO_ 2499801297 75;
BA_ "GenMsgStartDelayTime" BO_ 2499801297 5;
BA_ "GenMsgCycleTime" BO_ 2499794044 75;
BA_ "GenMsgStartDelayTime" BO_ 2499794044 30;
BA_ "GenSigSendType" SG_ 2565494112 TPMSetPresThresCfg_sg_UB_ISig_4 7;
BA_ "GenSigCycleTime" SG_ 2565494112 TPMSetPresThresCfg_sg_UB_ISig_4 100;
BA_ "GenSigCycleTimeActive" SG_ 2565494112 TPMSetPresThresCfg_sg_UB_ISig_4 100;
BA_ "Platform_VMCU1_Sig" SG_ 2565494112 TPMSetPresThresCfg_sg_UB_ISig_4 1;
BA_ "GenSigCycleTime" SG_ 2565494112 TPMSetAxleTireConfig_Axle4_ISig_ 100;
BA_ "GenSigCycleTimeActive" SG_ 2565494112 TPMSetAxleTireConfig_Axle4_ISig_ 100;
BA_ "GenSigStartValue" SG_ 2565494112 TPMSetAxleTireConfig_Axle4_ISig_ 7;
BA_ "NeedsUpdateBit" SG_ 2565494112 TPMSetAxleTireConfig_Axle4_ISig_ 1;
BA_ "Platform_VMCU1_Sig" SG_ 2565494112 TPMSetAxleTireConfig_Axle4_ISig_ 1;
BA_ "SystemSignalLongSymbol" SG_ 2565494112 TPMSetAxleTireConfig_Axle4_ISig_ "TPMSetAxleTireConfig_Axle4_ISig_4";
BA_ "GenSigCycleTime" SG_ 2565494112 TPMSetAxleTireConfig_Axle5_ISig_ 100;
BA_ "GenSigCycleTimeActive" SG_ 2565494112 TPMSetAxleTireConfig_Axle5_ISig_ 100;
BA_ "GenSigStartValue" SG_ 2565494112 TPMSetAxleTireConfig_Axle5_ISig_ 7;
BA_ "NeedsUpdateBit" SG_ 2565494112 TPMSetAxleTireConfig_Axle5_ISig_ 1;
BA_ "Platform_VMCU1_Sig" SG_ 2565494112 TPMSetAxleTireConfig_Axle5_ISig_ 1;
BA_ "SystemSignalLongSymbol" SG_ 2565494112 TPMSetAxleTireConfig_Axle5_ISig_ "TPMSetAxleTireConfig_Axle5_ISig_4";
BA_ "GenSigCycleTime" SG_ 2565494112 TPMSetPresThresCfg_VehiclePos_IS 100;
BA_ "GenSigCycleTimeActive" SG_ 2565494112 TPMSetPresThresCfg_VehiclePos_IS 100;
BA_ "GenSigStartValue" SG_ 2565494112 TPMSetPresThresCfg_VehiclePos_IS 7;
BA_ "NeedsUpdateBit" SG_ 2565494112 TPMSetPresThresCfg_VehiclePos_IS 1;
BA_ "Platform_VMCU1_Sig" SG_ 2565494112 TPMSetPresThresCfg_VehiclePos_IS 1;
BA_ "SystemSignalLongSymbol" SG_ 2565494112 TPMSetPresThresCfg_VehiclePos_IS "TPMSetPresThresCfg_VehiclePos_ISig_4";
BA_ "GenSigCycleTime" SG_ 2565494112 TPMSetPresThresCfg_ExtOverPres_I 100;
BA_ "GenSigCycleTimeActive" SG_ 2565494112 TPMSetPresThresCfg_ExtOverPres_I 100;
BA_ "GenSigStartValue" SG_ 2565494112 TPMSetPresThresCfg_ExtOverPres_I 255;
BA_ "NeedsUpdateBit" SG_ 2565494112 TPMSetPresThresCfg_ExtOverPres_I 1;
BA_ "Platform_VMCU1_Sig" SG_ 2565494112 TPMSetPresThresCfg_ExtOverPres_I 1;
BA_ "SystemSignalLongSymbol" SG_ 2565494112 TPMSetPresThresCfg_ExtOverPres_I "TPMSetPresThresCfg_ExtOverPres_ISig_4";
BA_ "GenSigCycleTime" SG_ 2565494112 TPMSetAxleTireConfig_Axle2_ISig_ 100;
BA_ "GenSigCycleTimeActive" SG_ 2565494112 TPMSetAxleTireConfig_Axle2_ISig_ 100;
BA_ "GenSigStartValue" SG_ 2565494112 TPMSetAxleTireConfig_Axle2_ISig_ 7;
BA_ "NeedsUpdateBit" SG_ 2565494112 TPMSetAxleTireConfig_Axle2_ISig_ 1;
BA_ "Platform_VMCU1_Sig" SG_ 2565494112 TPMSetAxleTireConfig_Axle2_ISig_ 1;
BA_ "SystemSignalLongSymbol" SG_ 2565494112 TPMSetAxleTireConfig_Axle2_ISig_ "TPMSetAxleTireConfig_Axle2_ISig_4";
BA_ "GenSigCycleTime" SG_ 2565494112 TPMSetAxleTireConfig_VehiclePos_ 100;
BA_ "GenSigCycleTimeActive" SG_ 2565494112 TPMSetAxleTireConfig_VehiclePos_ 100;
BA_ "GenSigStartValue" SG_ 2565494112 TPMSetAxleTireConfig_VehiclePos_ 7;
BA_ "NeedsUpdateBit" SG_ 2565494112 TPMSetAxleTireConfig_VehiclePos_ 1;
BA_ "Platform_VMCU1_Sig" SG_ 2565494112 TPMSetAxleTireConfig_VehiclePos_ 1;
BA_ "SystemSignalLongSymbol" SG_ 2565494112 TPMSetAxleTireConfig_VehiclePos_ "TPMSetAxleTireConfig_VehiclePos_ISig_4";
BA_ "GenSigCycleTime" SG_ 2565494112 TPMSetAxleTireConfig_Axle3_ISig_ 100;
BA_ "GenSigCycleTimeActive" SG_ 2565494112 TPMSetAxleTireConfig_Axle3_ISig_ 100;
BA_ "GenSigStartValue" SG_ 2565494112 TPMSetAxleTireConfig_Axle3_ISig_ 7;
BA_ "NeedsUpdateBit" SG_ 2565494112 TPMSetAxleTireConfig_Axle3_ISig_ 1;
BA_ "Platform_VMCU1_Sig" SG_ 2565494112 TPMSetAxleTireConfig_Axle3_ISig_ 1;
BA_ "SystemSignalLongSymbol" SG_ 2565494112 TPMSetAxleTireConfig_Axle3_ISig_ "TPMSetAxleTireConfig_Axle3_ISig_4";
BA_ "GenSigCycleTime" SG_ 2565494112 TPMSetAxleTireConfig_Axle1_ISig_ 100;
BA_ "GenSigCycleTimeActive" SG_ 2565494112 TPMSetAxleTireConfig_Axle1_ISig_ 100;
BA_ "GenSigStartValue" SG_ 2565494112 TPMSetAxleTireConfig_Axle1_ISig_ 7;
BA_ "NeedsUpdateBit" SG_ 2565494112 TPMSetAxleTireConfig_Axle1_ISig_ 1;
BA_ "Platform_VMCU1_Sig" SG_ 2565494112 TPMSetAxleTireConfig_Axle1_ISig_ 1;
BA_ "SystemSignalLongSymbol" SG_ 2565494112 TPMSetAxleTireConfig_Axle1_ISig_ "TPMSetAxleTireConfig_Axle1_ISig_4";
BA_ "GenSigCycleTime" SG_ 2565494112 TPMSetPresThresCfg_AxleNr_ISig_4 100;
BA_ "GenSigCycleTimeActive" SG_ 2565494112 TPMSetPresThresCfg_AxleNr_ISig_4 100;
BA_ "GenSigStartValue" SG_ 2565494112 TPMSetPresThresCfg_AxleNr_ISig_4 7;
BA_ "NeedsUpdateBit" SG_ 2565494112 TPMSetPresThresCfg_AxleNr_ISig_4 1;
BA_ "Platform_VMCU1_Sig" SG_ 2565494112 TPMSetPresThresCfg_AxleNr_ISig_4 1;
BA_ "GenSigSendType" SG_ 2565494112 TPMSetAxleTireConfig_sg_UB_ISig_ 7;
BA_ "GenSigCycleTime" SG_ 2565494112 TPMSetAxleTireConfig_sg_UB_ISig_ 100;
BA_ "GenSigCycleTimeActive" SG_ 2565494112 TPMSetAxleTireConfig_sg_UB_ISig_ 100;
BA_ "Platform_VMCU1_Sig" SG_ 2565494112 TPMSetAxleTireConfig_sg_UB_ISig_ 1;
BA_ "SystemSignalLongSymbol" SG_ 2565494112 TPMSetAxleTireConfig_sg_UB_ISig_ "TPMSetAxleTireConfig_sg_UB_ISig_4";
BA_ "GenSigCycleTime" SG_ 2565494112 TPMSetPresThresCfg_OverPres_ISig 100;
BA_ "GenSigCycleTimeActive" SG_ 2565494112 TPMSetPresThresCfg_OverPres_ISig 100;
BA_ "GenSigStartValue" SG_ 2565494112 TPMSetPresThresCfg_OverPres_ISig 255;
BA_ "NeedsUpdateBit" SG_ 2565494112 TPMSetPresThresCfg_OverPres_ISig 1;
BA_ "Platform_VMCU1_Sig" SG_ 2565494112 TPMSetPresThresCfg_OverPres_ISig 1;
BA_ "SystemSignalLongSymbol" SG_ 2565494112 TPMSetPresThresCfg_OverPres_ISig "TPMSetPresThresCfg_OverPres_ISig_4";
BA_ "GenSigCycleTime" SG_ 2565494112 TPMSetPresThresCfg_ExtUnderPres_ 100;
BA_ "GenSigCycleTimeActive" SG_ 2565494112 TPMSetPresThresCfg_ExtUnderPres_ 100;
BA_ "GenSigStartValue" SG_ 2565494112 TPMSetPresThresCfg_ExtUnderPres_ 255;
BA_ "NeedsUpdateBit" SG_ 2565494112 TPMSetPresThresCfg_ExtUnderPres_ 1;
BA_ "Platform_VMCU1_Sig" SG_ 2565494112 TPMSetPresThresCfg_ExtUnderPres_ 1;
BA_ "SystemSignalLongSymbol" SG_ 2565494112 TPMSetPresThresCfg_ExtUnderPres_ "TPMSetPresThresCfg_ExtUnderPres_ISig_4";
BA_ "GenSigCycleTime" SG_ 2565494112 TPMSetPresThresCfg_UnderPres_ISi 100;
BA_ "GenSigCycleTimeActive" SG_ 2565494112 TPMSetPresThresCfg_UnderPres_ISi 100;
BA_ "GenSigStartValue" SG_ 2565494112 TPMSetPresThresCfg_UnderPres_ISi 255;
BA_ "NeedsUpdateBit" SG_ 2565494112 TPMSetPresThresCfg_UnderPres_ISi 1;
BA_ "Platform_VMCU1_Sig" SG_ 2565494112 TPMSetPresThresCfg_UnderPres_ISi 1;
BA_ "SystemSignalLongSymbol" SG_ 2565494112 TPMSetPresThresCfg_UnderPres_ISi "TPMSetPresThresCfg_UnderPres_ISig_4";
BA_ "GenSigSendType" SG_ 2582855520 HillDataPkgTGW_ISig_4 1;
BA_ "GenSigMaxLatency" SG_ 2582855520 HillDataPkgTGW_ISig_4 2500;
BA_ "Platform_VMCU1_Sig" SG_ 2582855520 HillDataPkgTGW_ISig_4 1;
BA_ "GenSigSendType" SG_ 2566356833 HMIIOM_BB2_27S_FCS 7;
BA_ "Platform_VMCU1_Sig" SG_ 2566356833 HMIIOM_BB2_27S_FCS 1;
BA_ "GenSigSendType" SG_ 2566356832 PHTimerTGWEvCmd_Timer3Minutes_IS 1;
BA_ "GenSigStartValue" SG_ 2566356832 PHTimerTGWEvCmd_Timer3Minutes_IS 255;
BA_ "GenSigMaxLatency" SG_ 2566356832 PHTimerTGWEvCmd_Timer3Minutes_IS 150;
BA_ "Platform_VMCU1_Sig" SG_ 2566356832 PHTimerTGWEvCmd_Timer3Minutes_IS 1;
BA_ "SystemSignalLongSymbol" SG_ 2566356832 PHTimerTGWEvCmd_Timer3Minutes_IS "PHTimerTGWEvCmd_Timer3Minutes_ISig_4";
BA_ "GenSigSendType" SG_ 2566356832 PHTimerTGWEvCmd_Timer1Temp_ISig_ 1;
BA_ "GenSigStartValue" SG_ 2566356832 PHTimerTGWEvCmd_Timer1Temp_ISig_ 31;
BA_ "GenSigMaxLatency" SG_ 2566356832 PHTimerTGWEvCmd_Timer1Temp_ISig_ 150;
BA_ "Platform_VMCU1_Sig" SG_ 2566356832 PHTimerTGWEvCmd_Timer1Temp_ISig_ 1;
BA_ "SystemSignalLongSymbol" SG_ 2566356832 PHTimerTGWEvCmd_Timer1Temp_ISig_ "PHTimerTGWEvCmd_Timer1Temp_ISig_4";
BA_ "GenSigSendType" SG_ 2566356832 PHTimerTGWEvCmd_Timer3StartDay_I 1;
BA_ "GenSigStartValue" SG_ 2566356832 PHTimerTGWEvCmd_Timer3StartDay_I 15;
BA_ "GenSigMaxLatency" SG_ 2566356832 PHTimerTGWEvCmd_Timer3StartDay_I 150;
BA_ "Platform_VMCU1_Sig" SG_ 2566356832 PHTimerTGWEvCmd_Timer3StartDay_I 1;
BA_ "SystemSignalLongSymbol" SG_ 2566356832 PHTimerTGWEvCmd_Timer3StartDay_I "PHTimerTGWEvCmd_Timer3StartDay_ISig_4";
BA_ "GenSigSendType" SG_ 2566356832 PHTimerTGWEvCmd_Timer1Recur_ISig 1;
BA_ "GenSigStartValue" SG_ 2566356832 PHTimerTGWEvCmd_Timer1Recur_ISig 15;
BA_ "GenSigMaxLatency" SG_ 2566356832 PHTimerTGWEvCmd_Timer1Recur_ISig 150;
BA_ "Platform_VMCU1_Sig" SG_ 2566356832 PHTimerTGWEvCmd_Timer1Recur_ISig 1;
BA_ "SystemSignalLongSymbol" SG_ 2566356832 PHTimerTGWEvCmd_Timer1Recur_ISig "PHTimerTGWEvCmd_Timer1Recur_ISig_4";
BA_ "GenSigSendType" SG_ 2566356832 PHTimerTGWEvCmd_Timer3Recur_ISig 1;
BA_ "GenSigStartValue" SG_ 2566356832 PHTimerTGWEvCmd_Timer3Recur_ISig 15;
BA_ "GenSigMaxLatency" SG_ 2566356832 PHTimerTGWEvCmd_Timer3Recur_ISig 150;
BA_ "Platform_VMCU1_Sig" SG_ 2566356832 PHTimerTGWEvCmd_Timer3Recur_ISig 1;
BA_ "SystemSignalLongSymbol" SG_ 2566356832 PHTimerTGWEvCmd_Timer3Recur_ISig "PHTimerTGWEvCmd_Timer3Recur_ISig_4";
BA_ "GenSigSendType" SG_ 2566356832 PHTimerTGWEvCmd_Timer3Temp_ISig_ 1;
BA_ "GenSigStartValue" SG_ 2566356832 PHTimerTGWEvCmd_Timer3Temp_ISig_ 31;
BA_ "GenSigMaxLatency" SG_ 2566356832 PHTimerTGWEvCmd_Timer3Temp_ISig_ 150;
BA_ "Platform_VMCU1_Sig" SG_ 2566356832 PHTimerTGWEvCmd_Timer3Temp_ISig_ 1;
BA_ "SystemSignalLongSymbol" SG_ 2566356832 PHTimerTGWEvCmd_Timer3Temp_ISig_ "PHTimerTGWEvCmd_Timer3Temp_ISig_4";
BA_ "GenSigSendType" SG_ 2566356832 PHTimerTGWEvCmd_PhTimer3_cmd_ISi 1;
BA_ "GenSigStartValue" SG_ 2566356832 PHTimerTGWEvCmd_PhTimer3_cmd_ISi 7;
BA_ "GenSigMaxLatency" SG_ 2566356832 PHTimerTGWEvCmd_PhTimer3_cmd_ISi 150;
BA_ "Platform_VMCU1_Sig" SG_ 2566356832 PHTimerTGWEvCmd_PhTimer3_cmd_ISi 1;
BA_ "SystemSignalLongSymbol" SG_ 2566356832 PHTimerTGWEvCmd_PhTimer3_cmd_ISi "PHTimerTGWEvCmd_PhTimer3_cmd_ISig_4";
BA_ "GenSigSendType" SG_ 2566356832 PHTimerTGWEvCmd_Timer1Hours_ISig 1;
BA_ "GenSigStartValue" SG_ 2566356832 PHTimerTGWEvCmd_Timer1Hours_ISig 255;
BA_ "GenSigMaxLatency" SG_ 2566356832 PHTimerTGWEvCmd_Timer1Hours_ISig 150;
BA_ "Platform_VMCU1_Sig" SG_ 2566356832 PHTimerTGWEvCmd_Timer1Hours_ISig 1;
BA_ "SystemSignalLongSymbol" SG_ 2566356832 PHTimerTGWEvCmd_Timer1Hours_ISig "PHTimerTGWEvCmd_Timer1Hours_ISig_4";
BA_ "GenSigSendType" SG_ 2566356832 PHTimerTGWEvCmd_Timer1StartDay_I 1;
BA_ "GenSigStartValue" SG_ 2566356832 PHTimerTGWEvCmd_Timer1StartDay_I 15;
BA_ "GenSigMaxLatency" SG_ 2566356832 PHTimerTGWEvCmd_Timer1StartDay_I 150;
BA_ "Platform_VMCU1_Sig" SG_ 2566356832 PHTimerTGWEvCmd_Timer1StartDay_I 1;
BA_ "SystemSignalLongSymbol" SG_ 2566356832 PHTimerTGWEvCmd_Timer1StartDay_I "PHTimerTGWEvCmd_Timer1StartDay_ISig_4";
BA_ "GenSigSendType" SG_ 2566356832 PHTimerTGWEvCmd_Timer2Minutes_IS 1;
BA_ "GenSigStartValue" SG_ 2566356832 PHTimerTGWEvCmd_Timer2Minutes_IS 255;
BA_ "GenSigMaxLatency" SG_ 2566356832 PHTimerTGWEvCmd_Timer2Minutes_IS 150;
BA_ "Platform_VMCU1_Sig" SG_ 2566356832 PHTimerTGWEvCmd_Timer2Minutes_IS 1;
BA_ "SystemSignalLongSymbol" SG_ 2566356832 PHTimerTGWEvCmd_Timer2Minutes_IS "PHTimerTGWEvCmd_Timer2Minutes_ISig_4";
BA_ "GenSigSendType" SG_ 2566356832 PHTimerTGWEvCmd_Timer2StartDay_I 1;
BA_ "GenSigStartValue" SG_ 2566356832 PHTimerTGWEvCmd_Timer2StartDay_I 15;
BA_ "GenSigMaxLatency" SG_ 2566356832 PHTimerTGWEvCmd_Timer2StartDay_I 150;
BA_ "Platform_VMCU1_Sig" SG_ 2566356832 PHTimerTGWEvCmd_Timer2StartDay_I 1;
BA_ "SystemSignalLongSymbol" SG_ 2566356832 PHTimerTGWEvCmd_Timer2StartDay_I "PHTimerTGWEvCmd_Timer2StartDay_ISig_4";
BA_ "GenSigSendType" SG_ 2566356832 PHTimerTGWEvCmd_Timer2Temp_ISig_ 1;
BA_ "GenSigStartValue" SG_ 2566356832 PHTimerTGWEvCmd_Timer2Temp_ISig_ 31;
BA_ "GenSigMaxLatency" SG_ 2566356832 PHTimerTGWEvCmd_Timer2Temp_ISig_ 150;
BA_ "Platform_VMCU1_Sig" SG_ 2566356832 PHTimerTGWEvCmd_Timer2Temp_ISig_ 1;
BA_ "SystemSignalLongSymbol" SG_ 2566356832 PHTimerTGWEvCmd_Timer2Temp_ISig_ "PHTimerTGWEvCmd_Timer2Temp_ISig_4";
BA_ "GenSigSendType" SG_ 2566356832 PHTimerTGWEvCmd_Timer1Duration_I 1;
BA_ "GenSigStartValue" SG_ 2566356832 PHTimerTGWEvCmd_Timer1Duration_I 127;
BA_ "GenSigMaxLatency" SG_ 2566356832 PHTimerTGWEvCmd_Timer1Duration_I 150;
BA_ "Platform_VMCU1_Sig" SG_ 2566356832 PHTimerTGWEvCmd_Timer1Duration_I 1;
BA_ "SystemSignalLongSymbol" SG_ 2566356832 PHTimerTGWEvCmd_Timer1Duration_I "PHTimerTGWEvCmd_Timer1Duration_ISig_4";
BA_ "GenSigSendType" SG_ 2566356832 PHTimerTGWEvCmd_Timer2Hours_ISig 1;
BA_ "GenSigStartValue" SG_ 2566356832 PHTimerTGWEvCmd_Timer2Hours_ISig 255;
BA_ "GenSigMaxLatency" SG_ 2566356832 PHTimerTGWEvCmd_Timer2Hours_ISig 150;
BA_ "Platform_VMCU1_Sig" SG_ 2566356832 PHTimerTGWEvCmd_Timer2Hours_ISig 1;
BA_ "SystemSignalLongSymbol" SG_ 2566356832 PHTimerTGWEvCmd_Timer2Hours_ISig "PHTimerTGWEvCmd_Timer2Hours_ISig_4";
BA_ "GenSigSendType" SG_ 2566356832 PHTimerTGWEvCmd_Timer3Hours_ISig 1;
BA_ "GenSigStartValue" SG_ 2566356832 PHTimerTGWEvCmd_Timer3Hours_ISig 255;
BA_ "GenSigMaxLatency" SG_ 2566356832 PHTimerTGWEvCmd_Timer3Hours_ISig 150;
BA_ "Platform_VMCU1_Sig" SG_ 2566356832 PHTimerTGWEvCmd_Timer3Hours_ISig 1;
BA_ "SystemSignalLongSymbol" SG_ 2566356832 PHTimerTGWEvCmd_Timer3Hours_ISig "PHTimerTGWEvCmd_Timer3Hours_ISig_4";
BA_ "GenSigSendType" SG_ 2566356832 PHTimerTGWEvCmd_PhTimer2_cmd_ISi 1;
BA_ "GenSigStartValue" SG_ 2566356832 PHTimerTGWEvCmd_PhTimer2_cmd_ISi 7;
BA_ "GenSigMaxLatency" SG_ 2566356832 PHTimerTGWEvCmd_PhTimer2_cmd_ISi 150;
BA_ "Platform_VMCU1_Sig" SG_ 2566356832 PHTimerTGWEvCmd_PhTimer2_cmd_ISi 1;
BA_ "SystemSignalLongSymbol" SG_ 2566356832 PHTimerTGWEvCmd_PhTimer2_cmd_ISi "PHTimerTGWEvCmd_PhTimer2_cmd_ISig_4";
BA_ "GenSigSendType" SG_ 2566356832 PHTimerTGWEvCmd_Timer2Recur_ISig 1;
BA_ "GenSigStartValue" SG_ 2566356832 PHTimerTGWEvCmd_Timer2Recur_ISig 15;
BA_ "GenSigMaxLatency" SG_ 2566356832 PHTimerTGWEvCmd_Timer2Recur_ISig 150;
BA_ "Platform_VMCU1_Sig" SG_ 2566356832 PHTimerTGWEvCmd_Timer2Recur_ISig 1;
BA_ "SystemSignalLongSymbol" SG_ 2566356832 PHTimerTGWEvCmd_Timer2Recur_ISig "PHTimerTGWEvCmd_Timer2Recur_ISig_4";
BA_ "GenSigSendType" SG_ 2566356832 PHTimerTGWEvCmd_Timer1Minutes_IS 1;
BA_ "GenSigStartValue" SG_ 2566356832 PHTimerTGWEvCmd_Timer1Minutes_IS 255;
BA_ "GenSigMaxLatency" SG_ 2566356832 PHTimerTGWEvCmd_Timer1Minutes_IS 150;
BA_ "Platform_VMCU1_Sig" SG_ 2566356832 PHTimerTGWEvCmd_Timer1Minutes_IS 1;
BA_ "SystemSignalLongSymbol" SG_ 2566356832 PHTimerTGWEvCmd_Timer1Minutes_IS "PHTimerTGWEvCmd_Timer1Minutes_ISig_4";
BA_ "GenSigSendType" SG_ 2566356832 PHTimerTGWEvCmd_PhTimer1_cmd_ISi 1;
BA_ "GenSigStartValue" SG_ 2566356832 PHTimerTGWEvCmd_PhTimer1_cmd_ISi 7;
BA_ "GenSigMaxLatency" SG_ 2566356832 PHTimerTGWEvCmd_PhTimer1_cmd_ISi 150;
BA_ "Platform_VMCU1_Sig" SG_ 2566356832 PHTimerTGWEvCmd_PhTimer1_cmd_ISi 1;
BA_ "SystemSignalLongSymbol" SG_ 2566356832 PHTimerTGWEvCmd_PhTimer1_cmd_ISi "PHTimerTGWEvCmd_PhTimer1_cmd_ISig_4";
BA_ "GenSigCycleTime" SG_ 2515671136 Trailer3LiftAxles_LiftAxle1Id_IS 100;
BA_ "GenSigCycleTimeActive" SG_ 2515671136 Trailer3LiftAxles_LiftAxle1Id_IS 100;
BA_ "GenSigStartValue" SG_ 2515671136 Trailer3LiftAxles_LiftAxle1Id_IS 15;
BA_ "Platform_VMCU1_Sig" SG_ 2515671136 Trailer3LiftAxles_LiftAxle1Id_IS 1;
BA_ "SystemSignalLongSymbol" SG_ 2515671136 Trailer3LiftAxles_LiftAxle1Id_IS "Trailer3LiftAxles_LiftAxle1Id_ISig_4";
BA_ "GenSigCycleTime" SG_ 2515671136 Trailer2LiftAxles_LiftAxle1Pos_I 100;
BA_ "GenSigCycleTimeActive" SG_ 2515671136 Trailer2LiftAxles_LiftAxle1Pos_I 100;
BA_ "GenSigStartValue" SG_ 2515671136 Trailer2LiftAxles_LiftAxle1Pos_I 3;
BA_ "Platform_VMCU1_Sig" SG_ 2515671136 Trailer2LiftAxles_LiftAxle1Pos_I 1;
BA_ "SystemSignalLongSymbol" SG_ 2515671136 Trailer2LiftAxles_LiftAxle1Pos_I "Trailer2LiftAxles_LiftAxle1Pos_ISig_4";
BA_ "GenSigCycleTime" SG_ 2515671136 Trailer1LiftAxles_LiftAxle2Pos_I 100;
BA_ "GenSigCycleTimeActive" SG_ 2515671136 Trailer1LiftAxles_LiftAxle2Pos_I 100;
BA_ "GenSigStartValue" SG_ 2515671136 Trailer1LiftAxles_LiftAxle2Pos_I 3;
BA_ "Platform_VMCU1_Sig" SG_ 2515671136 Trailer1LiftAxles_LiftAxle2Pos_I 1;
BA_ "SystemSignalLongSymbol" SG_ 2515671136 Trailer1LiftAxles_LiftAxle2Pos_I "Trailer1LiftAxles_LiftAxle2Pos_ISig_4";
BA_ "GenSigCycleTime" SG_ 2515671136 Trailer3LiftAxles_LiftAxle2Pos_I 100;
BA_ "GenSigCycleTimeActive" SG_ 2515671136 Trailer3LiftAxles_LiftAxle2Pos_I 100;
BA_ "GenSigStartValue" SG_ 2515671136 Trailer3LiftAxles_LiftAxle2Pos_I 3;
BA_ "Platform_VMCU1_Sig" SG_ 2515671136 Trailer3LiftAxles_LiftAxle2Pos_I 1;
BA_ "SystemSignalLongSymbol" SG_ 2515671136 Trailer3LiftAxles_LiftAxle2Pos_I "Trailer3LiftAxles_LiftAxle2Pos_ISig_4";
BA_ "GenSigCycleTime" SG_ 2515671136 Trailer1LiftAxles_LiftAxle2Id_IS 100;
BA_ "GenSigCycleTimeActive" SG_ 2515671136 Trailer1LiftAxles_LiftAxle2Id_IS 100;
BA_ "GenSigStartValue" SG_ 2515671136 Trailer1LiftAxles_LiftAxle2Id_IS 15;
BA_ "Platform_VMCU1_Sig" SG_ 2515671136 Trailer1LiftAxles_LiftAxle2Id_IS 1;
BA_ "SystemSignalLongSymbol" SG_ 2515671136 Trailer1LiftAxles_LiftAxle2Id_IS "Trailer1LiftAxles_LiftAxle2Id_ISig_4";
BA_ "GenSigCycleTime" SG_ 2515671136 Trailer5LiftAxles_LiftAxle1Id_IS 100;
BA_ "GenSigCycleTimeActive" SG_ 2515671136 Trailer5LiftAxles_LiftAxle1Id_IS 100;
BA_ "GenSigStartValue" SG_ 2515671136 Trailer5LiftAxles_LiftAxle1Id_IS 15;
BA_ "Platform_VMCU1_Sig" SG_ 2515671136 Trailer5LiftAxles_LiftAxle1Id_IS 1;
BA_ "SystemSignalLongSymbol" SG_ 2515671136 Trailer5LiftAxles_LiftAxle1Id_IS "Trailer5LiftAxles_LiftAxle1Id_ISig_4";
BA_ "GenSigCycleTime" SG_ 2515671136 Trailer1LiftAxles_LiftAxle1Pos_I 100;
BA_ "GenSigCycleTimeActive" SG_ 2515671136 Trailer1LiftAxles_LiftAxle1Pos_I 100;
BA_ "GenSigStartValue" SG_ 2515671136 Trailer1LiftAxles_LiftAxle1Pos_I 3;
BA_ "Platform_VMCU1_Sig" SG_ 2515671136 Trailer1LiftAxles_LiftAxle1Pos_I 1;
BA_ "SystemSignalLongSymbol" SG_ 2515671136 Trailer1LiftAxles_LiftAxle1Pos_I "Trailer1LiftAxles_LiftAxle1Pos_ISig_4";
BA_ "GenSigCycleTime" SG_ 2515671136 Trailer1LiftAxles_LiftAxle1Id_IS 100;
BA_ "GenSigCycleTimeActive" SG_ 2515671136 Trailer1LiftAxles_LiftAxle1Id_IS 100;
BA_ "GenSigStartValue" SG_ 2515671136 Trailer1LiftAxles_LiftAxle1Id_IS 15;
BA_ "Platform_VMCU1_Sig" SG_ 2515671136 Trailer1LiftAxles_LiftAxle1Id_IS 1;
BA_ "SystemSignalLongSymbol" SG_ 2515671136 Trailer1LiftAxles_LiftAxle1Id_IS "Trailer1LiftAxles_LiftAxle1Id_ISig_4";
BA_ "GenSigCycleTime" SG_ 2515671136 Trailer4LiftAxles_LiftAxle2Pos_I 100;
BA_ "GenSigCycleTimeActive" SG_ 2515671136 Trailer4LiftAxles_LiftAxle2Pos_I 100;
BA_ "GenSigStartValue" SG_ 2515671136 Trailer4LiftAxles_LiftAxle2Pos_I 3;
BA_ "Platform_VMCU1_Sig" SG_ 2515671136 Trailer4LiftAxles_LiftAxle2Pos_I 1;
BA_ "SystemSignalLongSymbol" SG_ 2515671136 Trailer4LiftAxles_LiftAxle2Pos_I "Trailer4LiftAxles_LiftAxle2Pos_ISig_4";
BA_ "GenSigCycleTime" SG_ 2515671136 Trailer5LiftAxles_LiftAxle2Pos_I 100;
BA_ "GenSigCycleTimeActive" SG_ 2515671136 Trailer5LiftAxles_LiftAxle2Pos_I 100;
BA_ "GenSigStartValue" SG_ 2515671136 Trailer5LiftAxles_LiftAxle2Pos_I 3;
BA_ "Platform_VMCU1_Sig" SG_ 2515671136 Trailer5LiftAxles_LiftAxle2Pos_I 1;
BA_ "SystemSignalLongSymbol" SG_ 2515671136 Trailer5LiftAxles_LiftAxle2Pos_I "Trailer5LiftAxles_LiftAxle2Pos_ISig_4";
BA_ "GenSigCycleTime" SG_ 2515671136 Trailer4LiftAxles_LiftAxle1Pos_I 100;
BA_ "GenSigCycleTimeActive" SG_ 2515671136 Trailer4LiftAxles_LiftAxle1Pos_I 100;
BA_ "GenSigStartValue" SG_ 2515671136 Trailer4LiftAxles_LiftAxle1Pos_I 3;
BA_ "Platform_VMCU1_Sig" SG_ 2515671136 Trailer4LiftAxles_LiftAxle1Pos_I 1;
BA_ "SystemSignalLongSymbol" SG_ 2515671136 Trailer4LiftAxles_LiftAxle1Pos_I "Trailer4LiftAxles_LiftAxle1Pos_ISig_4";
BA_ "GenSigCycleTime" SG_ 2515671136 Trailer2LiftAxles_LiftAxle1Id_IS 100;
BA_ "GenSigCycleTimeActive" SG_ 2515671136 Trailer2LiftAxles_LiftAxle1Id_IS 100;
BA_ "GenSigStartValue" SG_ 2515671136 Trailer2LiftAxles_LiftAxle1Id_IS 15;
BA_ "Platform_VMCU1_Sig" SG_ 2515671136 Trailer2LiftAxles_LiftAxle1Id_IS 1;
BA_ "SystemSignalLongSymbol" SG_ 2515671136 Trailer2LiftAxles_LiftAxle1Id_IS "Trailer2LiftAxles_LiftAxle1Id_ISig_4";
BA_ "GenSigCycleTime" SG_ 2515671136 Trailer5LiftAxles_LiftAxle1Pos_I 100;
BA_ "GenSigCycleTimeActive" SG_ 2515671136 Trailer5LiftAxles_LiftAxle1Pos_I 100;
BA_ "GenSigStartValue" SG_ 2515671136 Trailer5LiftAxles_LiftAxle1Pos_I 3;
BA_ "Platform_VMCU1_Sig" SG_ 2515671136 Trailer5LiftAxles_LiftAxle1Pos_I 1;
BA_ "SystemSignalLongSymbol" SG_ 2515671136 Trailer5LiftAxles_LiftAxle1Pos_I "Trailer5LiftAxles_LiftAxle1Pos_ISig_4";
BA_ "GenSigCycleTime" SG_ 2515671136 Trailer2LiftAxles_LiftAxle2Pos_I 100;
BA_ "GenSigCycleTimeActive" SG_ 2515671136 Trailer2LiftAxles_LiftAxle2Pos_I 100;
BA_ "GenSigStartValue" SG_ 2515671136 Trailer2LiftAxles_LiftAxle2Pos_I 3;
BA_ "Platform_VMCU1_Sig" SG_ 2515671136 Trailer2LiftAxles_LiftAxle2Pos_I 1;
BA_ "SystemSignalLongSymbol" SG_ 2515671136 Trailer2LiftAxles_LiftAxle2Pos_I "Trailer2LiftAxles_LiftAxle2Pos_ISig_4";
BA_ "GenSigCycleTime" SG_ 2515671136 Trailer2LiftAxles_LiftAxle2Id_IS 100;
BA_ "GenSigCycleTimeActive" SG_ 2515671136 Trailer2LiftAxles_LiftAxle2Id_IS 100;
BA_ "GenSigStartValue" SG_ 2515671136 Trailer2LiftAxles_LiftAxle2Id_IS 15;
BA_ "Platform_VMCU1_Sig" SG_ 2515671136 Trailer2LiftAxles_LiftAxle2Id_IS 1;
BA_ "SystemSignalLongSymbol" SG_ 2515671136 Trailer2LiftAxles_LiftAxle2Id_IS "Trailer2LiftAxles_LiftAxle2Id_ISig_4";
BA_ "GenSigCycleTime" SG_ 2515671136 Trailer3LiftAxles_LiftAxle1Pos_I 100;
BA_ "GenSigCycleTimeActive" SG_ 2515671136 Trailer3LiftAxles_LiftAxle1Pos_I 100;
BA_ "GenSigStartValue" SG_ 2515671136 Trailer3LiftAxles_LiftAxle1Pos_I 3;
BA_ "Platform_VMCU1_Sig" SG_ 2515671136 Trailer3LiftAxles_LiftAxle1Pos_I 1;
BA_ "SystemSignalLongSymbol" SG_ 2515671136 Trailer3LiftAxles_LiftAxle1Pos_I "Trailer3LiftAxles_LiftAxle1Pos_ISig_4";
BA_ "GenSigCycleTime" SG_ 2515671136 Trailer5LiftAxles_LiftAxle2Id_IS 100;
BA_ "GenSigCycleTimeActive" SG_ 2515671136 Trailer5LiftAxles_LiftAxle2Id_IS 100;
BA_ "GenSigStartValue" SG_ 2515671136 Trailer5LiftAxles_LiftAxle2Id_IS 15;
BA_ "Platform_VMCU1_Sig" SG_ 2515671136 Trailer5LiftAxles_LiftAxle2Id_IS 1;
BA_ "SystemSignalLongSymbol" SG_ 2515671136 Trailer5LiftAxles_LiftAxle2Id_IS "Trailer5LiftAxles_LiftAxle2Id_ISig_4";
BA_ "GenSigCycleTime" SG_ 2515671136 InhibRegeneration_DeviceInd 100;
BA_ "GenSigCycleTimeActive" SG_ 2515671136 InhibRegeneration_DeviceInd 100;
BA_ "GenSigStartValue" SG_ 2515671136 InhibRegeneration_DeviceInd 3;
BA_ "Platform_VMCU1_Sig" SG_ 2515671136 InhibRegeneration_DeviceInd 1;
BA_ "GenSigCycleTime" SG_ 2515671136 Trailer4LiftAxles_LiftAxle1Id_IS 100;
BA_ "GenSigCycleTimeActive" SG_ 2515671136 Trailer4LiftAxles_LiftAxle1Id_IS 100;
BA_ "GenSigStartValue" SG_ 2515671136 Trailer4LiftAxles_LiftAxle1Id_IS 15;
BA_ "Platform_VMCU1_Sig" SG_ 2515671136 Trailer4LiftAxles_LiftAxle1Id_IS 1;
BA_ "SystemSignalLongSymbol" SG_ 2515671136 Trailer4LiftAxles_LiftAxle1Id_IS "Trailer4LiftAxles_LiftAxle1Id_ISig_4";
BA_ "GenSigCycleTime" SG_ 2515671136 Trailer3LiftAxles_LiftAxle2Id_IS 100;
BA_ "GenSigCycleTimeActive" SG_ 2515671136 Trailer3LiftAxles_LiftAxle2Id_IS 100;
BA_ "GenSigStartValue" SG_ 2515671136 Trailer3LiftAxles_LiftAxle2Id_IS 15;
BA_ "Platform_VMCU1_Sig" SG_ 2515671136 Trailer3LiftAxles_LiftAxle2Id_IS 1;
BA_ "SystemSignalLongSymbol" SG_ 2515671136 Trailer3LiftAxles_LiftAxle2Id_IS "Trailer3LiftAxles_LiftAxle2Id_ISig_4";
BA_ "GenSigCycleTime" SG_ 2515671136 Trailer4LiftAxles_LiftAxle2Id_IS 100;
BA_ "GenSigCycleTimeActive" SG_ 2515671136 Trailer4LiftAxles_LiftAxle2Id_IS 100;
BA_ "GenSigStartValue" SG_ 2515671136 Trailer4LiftAxles_LiftAxle2Id_IS 15;
BA_ "Platform_VMCU1_Sig" SG_ 2515671136 Trailer4LiftAxles_LiftAxle2Id_IS 1;
BA_ "SystemSignalLongSymbol" SG_ 2515671136 Trailer4LiftAxles_LiftAxle2Id_IS "Trailer4LiftAxles_LiftAxle2Id_ISig_4";
BA_ "GenSigCycleTime" SG_ 2482917472 RefrigTimerRqstAck_CurrentOp 100;
BA_ "GenSigCycleTimeActive" SG_ 2482917472 RefrigTimerRqstAck_CurrentOp 100;
BA_ "GenSigStartValue" SG_ 2482917472 RefrigTimerRqstAck_CurrentOp 3;
BA_ "Platform_VMCU1_Sig" SG_ 2482917472 RefrigTimerRqstAck_CurrentOp 1;
BA_ "GenSigCycleTime" SG_ 2482917472 RefrigTimerRqstAck_DayOfWeekRq 100;
BA_ "GenSigCycleTimeActive" SG_ 2482917472 RefrigTimerRqstAck_DayOfWeekRq 100;
BA_ "GenSigStartValue" SG_ 2482917472 RefrigTimerRqstAck_DayOfWeekRq 15;
BA_ "Platform_VMCU1_Sig" SG_ 2482917472 RefrigTimerRqstAck_DayOfWeekRq 1;
BA_ "GenSigSendType" SG_ 2482917472 TPMIndicationLightReq_UB 7;
BA_ "GenSigCycleTime" SG_ 2482917472 TPMIndicationLightReq_UB 100;
BA_ "GenSigCycleTimeActive" SG_ 2482917472 TPMIndicationLightReq_UB 100;
BA_ "Platform_VMCU1_Sig" SG_ 2482917472 TPMIndicationLightReq_UB 1;
BA_ "GenSigCycleTime" SG_ 2482917472 PHTimerRqstAck_Minutes_ISig_4 100;
BA_ "GenSigCycleTimeActive" SG_ 2482917472 PHTimerRqstAck_Minutes_ISig_4 100;
BA_ "GenSigStartValue" SG_ 2482917472 PHTimerRqstAck_Minutes_ISig_4 255;
BA_ "Platform_VMCU1_Sig" SG_ 2482917472 PHTimerRqstAck_Minutes_ISig_4 1;
BA_ "GenSigCycleTime" SG_ 2482917472 RemoteParkingClimateRqst_ISig_4 100;
BA_ "GenSigCycleTimeActive" SG_ 2482917472 RemoteParkingClimateRqst_ISig_4 100;
BA_ "GenSigStartValue" SG_ 2482917472 RemoteParkingClimateRqst_ISig_4 7;
BA_ "Platform_VMCU1_Sig" SG_ 2482917472 RemoteParkingClimateRqst_ISig_4 1;
BA_ "GenSigCycleTime" SG_ 2482917472 PHTimerRqstAck_Hours_ISig_4 100;
BA_ "GenSigCycleTimeActive" SG_ 2482917472 PHTimerRqstAck_Hours_ISig_4 100;
BA_ "GenSigStartValue" SG_ 2482917472 PHTimerRqstAck_Hours_ISig_4 255;
BA_ "Platform_VMCU1_Sig" SG_ 2482917472 PHTimerRqstAck_Hours_ISig_4 1;
BA_ "GenSigCycleTime" SG_ 2482917472 RegenerationIndication 100;
BA_ "GenSigCycleTimeActive" SG_ 2482917472 RegenerationIndication 100;
BA_ "Platform_VMCU1_Sig" SG_ 2482917472 RegenerationIndication 1;
BA_ "GenSigCycleTime" SG_ 2482917472 RefrigTimerRqstAck_Hours 100;
BA_ "GenSigCycleTimeActive" SG_ 2482917472 RefrigTimerRqstAck_Hours 100;
BA_ "GenSigStartValue" SG_ 2482917472 RefrigTimerRqstAck_Hours 255;
BA_ "Platform_VMCU1_Sig" SG_ 2482917472 RefrigTimerRqstAck_Hours 1;
BA_ "GenSigCycleTime" SG_ 2482917472 RefrigTimerRqstAck_Minutes 100;
BA_ "GenSigCycleTimeActive" SG_ 2482917472 RefrigTimerRqstAck_Minutes 100;
BA_ "GenSigStartValue" SG_ 2482917472 RefrigTimerRqstAck_Minutes 255;
BA_ "Platform_VMCU1_Sig" SG_ 2482917472 RefrigTimerRqstAck_Minutes 1;
BA_ "GenSigCycleTime" SG_ 2482917472 TPMIndicationLightReq 100;
BA_ "GenSigCycleTimeActive" SG_ 2482917472 TPMIndicationLightReq 100;
BA_ "GenSigStartValue" SG_ 2482917472 TPMIndicationLightReq 3;
BA_ "NeedsUpdateBit" SG_ 2482917472 TPMIndicationLightReq 1;
BA_ "Platform_VMCU1_Sig" SG_ 2482917472 TPMIndicationLightReq 1;
BA_ "GenSigCycleTime" SG_ 2482917472 PHTimerRqstAck_DayOfWeekRq_ISig_ 100;
BA_ "GenSigCycleTimeActive" SG_ 2482917472 PHTimerRqstAck_DayOfWeekRq_ISig_ 100;
BA_ "GenSigStartValue" SG_ 2482917472 PHTimerRqstAck_DayOfWeekRq_ISig_ 15;
BA_ "Platform_VMCU1_Sig" SG_ 2482917472 PHTimerRqstAck_DayOfWeekRq_ISig_ 1;
BA_ "SystemSignalLongSymbol" SG_ 2482917472 PHTimerRqstAck_DayOfWeekRq_ISig_ "PHTimerRqstAck_DayOfWeekRq_ISig_4";
BA_ "GenSigCycleTime" SG_ 2482917472 PHTimerRqstAck_CurrentOp_ISig_4 100;
BA_ "GenSigCycleTimeActive" SG_ 2482917472 PHTimerRqstAck_CurrentOp_ISig_4 100;
BA_ "GenSigStartValue" SG_ 2482917472 PHTimerRqstAck_CurrentOp_ISig_4 3;
BA_ "Platform_VMCU1_Sig" SG_ 2482917472 PHTimerRqstAck_CurrentOp_ISig_4 1;
BA_ "GenSigCycleTime" SG_ 2482917472 Regeneration_DeviceInd 100;
BA_ "GenSigCycleTimeActive" SG_ 2482917472 Regeneration_DeviceInd 100;
BA_ "GenSigStartValue" SG_ 2482917472 Regeneration_DeviceInd 15;
BA_ "Platform_VMCU1_Sig" SG_ 2482917472 Regeneration_DeviceInd 1;
BA_ "GenSigCycleTime" SG_ 2515822432 AlarmClockNotification_ID_ISig_4 100;
BA_ "GenSigCycleTimeActive" SG_ 2515822432 AlarmClockNotification_ID_ISig_4 100;
BA_ "GenSigStartValue" SG_ 2515822432 AlarmClockNotification_ID_ISig_4 127;
BA_ "Platform_VMCU1_Sig" SG_ 2515822432 AlarmClockNotification_ID_ISig_4 1;
BA_ "GenSigCycleTime" SG_ 2515822432 AlarmClockNotification_Type_ISig 100;
BA_ "GenSigCycleTimeActive" SG_ 2515822432 AlarmClockNotification_Type_ISig 100;
BA_ "GenSigStartValue" SG_ 2515822432 AlarmClockNotification_Type_ISig 7;
BA_ "GenSigMaxLatency" SG_ 2515822432 AlarmClockNotification_Type_ISig 169;
BA_ "Platform_VMCU1_Sig" SG_ 2515822432 AlarmClockNotification_Type_ISig 1;
BA_ "SystemSignalLongSymbol" SG_ 2515822432 AlarmClockNotification_Type_ISig "AlarmClockNotification_Type_ISig_4";
BA_ "GenSigCycleTime" SG_ 2515822432 ExtraHeating_rqst_ISig_4 100;
BA_ "GenSigCycleTimeActive" SG_ 2515822432 ExtraHeating_rqst_ISig_4 100;
BA_ "GenSigStartValue" SG_ 2515822432 ExtraHeating_rqst_ISig_4 7;
BA_ "Platform_VMCU1_Sig" SG_ 2515822432 ExtraHeating_rqst_ISig_4 1;
BA_ "GenSigCycleTime" SG_ 2515822432 AlarmClockNotification_Stat_ISig 100;
BA_ "GenSigCycleTimeActive" SG_ 2515822432 AlarmClockNotification_Stat_ISig 100;
BA_ "GenSigMaxLatency" SG_ 2515822432 AlarmClockNotification_Stat_ISig 169;
BA_ "Platform_VMCU1_Sig" SG_ 2515822432 AlarmClockNotification_Stat_ISig 1;
BA_ "SystemSignalLongSymbol" SG_ 2515822432 AlarmClockNotification_Stat_ISig "AlarmClockNotification_Stat_ISig_4";
BA_ "GenSigCycleTime" SG_ 2515822432 HillDataCtrlTGW_State_ISig_4 100;
BA_ "GenSigCycleTimeActive" SG_ 2515822432 HillDataCtrlTGW_State_ISig_4 100;
BA_ "GenSigStartValue" SG_ 2515822432 HillDataCtrlTGW_State_ISig_4 7;
BA_ "Platform_VMCU1_Sig" SG_ 2515822432 HillDataCtrlTGW_State_ISig_4 1;
BA_ "GenSigCycleTime" SG_ 2515822432 HillDataCtrlTGW_AckCnt_ISig_4 100;
BA_ "GenSigCycleTimeActive" SG_ 2515822432 HillDataCtrlTGW_AckCnt_ISig_4 100;
BA_ "Platform_VMCU1_Sig" SG_ 2515822432 HillDataCtrlTGW_AckCnt_ISig_4 1;
BA_ "GenSigCycleTime" SG_ 2565490016 BacklightLevelHighRes2_ISig_4 100;
BA_ "GenSigCycleTimeActive" SG_ 2565490016 BacklightLevelHighRes2_ISig_4 100;
BA_ "GenSigStartValue" SG_ 2565490016 BacklightLevelHighRes2_ISig_4 255;
BA_ "Platform_VMCU1_Sig" SG_ 2565490016 BacklightLevelHighRes2_ISig_4 1;
BA_ "GenSigCycleTime" SG_ 2565490016 DPF_AshLevelRequest 100;
BA_ "GenSigCycleTimeActive" SG_ 2565490016 DPF_AshLevelRequest 100;
BA_ "GenSigStartValue" SG_ 2565490016 DPF_AshLevelRequest 3;
BA_ "Platform_VMCU1_Sig" SG_ 2565490016 DPF_AshLevelRequest 1;
BA_ "GenSigCycleTime" SG_ 2565490016 DPF_RegenerationConditionsReq 100;
BA_ "GenSigCycleTimeActive" SG_ 2565490016 DPF_RegenerationConditionsReq 100;
BA_ "GenSigStartValue" SG_ 2565490016 DPF_RegenerationConditionsReq 3;
BA_ "Platform_VMCU1_Sig" SG_ 2565490016 DPF_RegenerationConditionsReq 1;
BA_ "GenSigSendType" SG_ 2565490016 SCR_SulphurRegenRqst 3;
BA_ "GenSigCycleTime" SG_ 2565490016 SCR_SulphurRegenRqst 100;
BA_ "GenSigCycleTimeActive" SG_ 2565490016 SCR_SulphurRegenRqst 100;
BA_ "GenSigStartValue" SG_ 2565490016 SCR_SulphurRegenRqst 3;
BA_ "Platform_VMCU1_Sig" SG_ 2565490016 SCR_SulphurRegenRqst 1;
BA_ "GenSigSendType" SG_ 2565490016 DPF_ManualRegenerateInhibit 3;
BA_ "GenSigCycleTime" SG_ 2565490016 DPF_ManualRegenerateInhibit 100;
BA_ "GenSigCycleTimeActive" SG_ 2565490016 DPF_ManualRegenerateInhibit 100;
BA_ "GenSigStartValue" SG_ 2565490016 DPF_ManualRegenerateInhibit 3;
BA_ "Platform_VMCU1_Sig" SG_ 2565490016 DPF_ManualRegenerateInhibit 1;
BA_ "GenSigCycleTime" SG_ 2565490016 DPF_SootLevelRequest 100;
BA_ "GenSigCycleTimeActive" SG_ 2565490016 DPF_SootLevelRequest 100;
BA_ "GenSigStartValue" SG_ 2565490016 DPF_SootLevelRequest 3;
BA_ "Platform_VMCU1_Sig" SG_ 2565490016 DPF_SootLevelRequest 1;
BA_ "GenSigSendType" SG_ 2565490016 DPF_ManualRegenerateRequest_ISig 3;
BA_ "GenSigCycleTime" SG_ 2565490016 DPF_ManualRegenerateRequest_ISig 100;
BA_ "GenSigCycleTimeActive" SG_ 2565490016 DPF_ManualRegenerateRequest_ISig 100;
BA_ "GenSigStartValue" SG_ 2565490016 DPF_ManualRegenerateRequest_ISig 3;
BA_ "Platform_VMCU1_Sig" SG_ 2565490016 DPF_ManualRegenerateRequest_ISig 1;
BA_ "SystemSignalLongSymbol" SG_ 2565490016 DPF_ManualRegenerateRequest_ISig "DPF_ManualRegenerateRequest_ISig_4";
BA_ "GenSigSendType" SG_ 2499794017 HMIIOM_BB2_21S_FCS 7;
BA_ "Platform_VMCU1_Sig" SG_ 2499794017 HMIIOM_BB2_21S_FCS 1;
BA_ "GenSigSendType" SG_ 2499794016 DisplayText_stat_ISig_4 1;
BA_ "GenSigMaxLatency" SG_ 2499794016 DisplayText_stat_ISig_4 77;
BA_ "Platform_VMCU1_Sig" SG_ 2499794016 DisplayText_stat_ISig_4 1;
BA_ "GenSigSendType" SG_ 2566000481 HMIIOM_BB2_20S_FCS 7;
BA_ "Platform_VMCU1_Sig" SG_ 2566000481 HMIIOM_BB2_20S_FCS 1;
BA_ "GenSigSendType" SG_ 2566000480 ECU3VIN_stat 1;
BA_ "GenSigMaxLatency" SG_ 2566000480 ECU3VIN_stat 137;
BA_ "Platform_VMCU1_Sig" SG_ 2566000480 ECU3VIN_stat 1;
BA_ "GenSigSendType" SG_ 2566268257 HMIIOM_BB2_19P_FCS_18f62561 7;
BA_ "Platform_VMCU1_Sig" SG_ 2566268257 HMIIOM_BB2_19P_FCS_18f62561 1;
BA_ "GenSigCycleTime" SG_ 2566268256 GPSData_Longitude_ISig_4_18f6256 100;
BA_ "GenSigCycleTimeActive" SG_ 2566268256 GPSData_Longitude_ISig_4_18f6256 100;
BA_ "GenSigStartValue" SG_ 2566268256 GPSData_Longitude_ISig_4_18f6256 4294967295;
BA_ "GenSigMaxLatency" SG_ 2566268256 GPSData_Longitude_ISig_4_18f6256 523;
BA_ "NeedsUpdateBit" SG_ 2566268256 GPSData_Longitude_ISig_4_18f6256 1;
BA_ "Platform_VMCU1_Sig" SG_ 2566268256 GPSData_Longitude_ISig_4_18f6256 1;
BA_ "SystemSignalLongSymbol" SG_ 2566268256 GPSData_Longitude_ISig_4_18f6256 "GPSData_Longitude_ISig_4_18f62560";
BA_ "GenSigSendType" SG_ 2566268256 GPSData_sg_UB_ISig_4_18f62560 7;
BA_ "Platform_VMCU1_Sig" SG_ 2566268256 GPSData_sg_UB_ISig_4_18f62560 1;
BA_ "GenSigCycleTime" SG_ 2566268256 GPSData_Direction_ISig_4_18f6256 100;
BA_ "GenSigCycleTimeActive" SG_ 2566268256 GPSData_Direction_ISig_4_18f6256 100;
BA_ "GenSigMaxLatency" SG_ 2566268256 GPSData_Direction_ISig_4_18f6256 523;
BA_ "NeedsUpdateBit" SG_ 2566268256 GPSData_Direction_ISig_4_18f6256 1;
BA_ "Platform_VMCU1_Sig" SG_ 2566268256 GPSData_Direction_ISig_4_18f6256 1;
BA_ "SystemSignalLongSymbol" SG_ 2566268256 GPSData_Direction_ISig_4_18f6256 "GPSData_Direction_ISig_4_18f62560";
BA_ "GenSigCycleTime" SG_ 2566268256 GPSData_Latitude_ISig_4_18f62560 100;
BA_ "GenSigCycleTimeActive" SG_ 2566268256 GPSData_Latitude_ISig_4_18f62560 100;
BA_ "GenSigStartValue" SG_ 2566268256 GPSData_Latitude_ISig_4_18f62560 4294967295;
BA_ "GenSigMaxLatency" SG_ 2566268256 GPSData_Latitude_ISig_4_18f62560 523;
BA_ "NeedsUpdateBit" SG_ 2566268256 GPSData_Latitude_ISig_4_18f62560 1;
BA_ "Platform_VMCU1_Sig" SG_ 2566268256 GPSData_Latitude_ISig_4_18f62560 1;
BA_ "GenSigCycleTime" SG_ 2566268256 GPSData_Altitude_ISig_4_18f62560 100;
BA_ "GenSigCycleTimeActive" SG_ 2566268256 GPSData_Altitude_ISig_4_18f62560 100;
BA_ "GenSigStartValue" SG_ 2566268256 GPSData_Altitude_ISig_4_18f62560 65535;
BA_ "GenSigMaxLatency" SG_ 2566268256 GPSData_Altitude_ISig_4_18f62560 523;
BA_ "NeedsUpdateBit" SG_ 2566268256 GPSData_Altitude_ISig_4_18f62560 1;
BA_ "Platform_VMCU1_Sig" SG_ 2566268256 GPSData_Altitude_ISig_4_18f62560 1;
BA_ "GenSigCycleTime" SG_ 2566268256 GPSData_HDOP_ISig_4_18f62560 100;
BA_ "GenSigCycleTimeActive" SG_ 2566268256 GPSData_HDOP_ISig_4_18f62560 100;
BA_ "GenSigMaxLatency" SG_ 2566268256 GPSData_HDOP_ISig_4_18f62560 523;
BA_ "NeedsUpdateBit" SG_ 2566268256 GPSData_HDOP_ISig_4_18f62560 1;
BA_ "Platform_VMCU1_Sig" SG_ 2566268256 GPSData_HDOP_ISig_4_18f62560 1;
BA_ "GenSigCycleTime" SG_ 2566268256 GPSData_Time_ISig_4_18f62560 100;
BA_ "GenSigCycleTimeActive" SG_ 2566268256 GPSData_Time_ISig_4_18f62560 100;
BA_ "GenSigStartValue" SG_ 2566268256 GPSData_Time_ISig_4_18f62560 4294967295;
BA_ "GenSigMaxLatency" SG_ 2566268256 GPSData_Time_ISig_4_18f62560 523;
BA_ "NeedsUpdateBit" SG_ 2566268256 GPSData_Time_ISig_4_18f62560 1;
BA_ "Platform_VMCU1_Sig" SG_ 2566268256 GPSData_Time_ISig_4_18f62560 1;
BA_ "GenSigCycleTime" SG_ 2566268256 GPSData_VehSpeed_ISig_4_18f62560 100;
BA_ "GenSigCycleTimeActive" SG_ 2566268256 GPSData_VehSpeed_ISig_4_18f62560 100;
BA_ "GenSigStartValue" SG_ 2566268256 GPSData_VehSpeed_ISig_4_18f62560 65535;
BA_ "GenSigMaxLatency" SG_ 2566268256 GPSData_VehSpeed_ISig_4_18f62560 523;
BA_ "NeedsUpdateBit" SG_ 2566268256 GPSData_VehSpeed_ISig_4_18f62560 1;
BA_ "Platform_VMCU1_Sig" SG_ 2566268256 GPSData_VehSpeed_ISig_4_18f62560 1;
BA_ "GenSigCycleTime" SG_ 2566268256 GPSData_AntennaStat_ISig_4_18f62 100;
BA_ "GenSigCycleTimeActive" SG_ 2566268256 GPSData_AntennaStat_ISig_4_18f62 100;
BA_ "GenSigStartValue" SG_ 2566268256 GPSData_AntennaStat_ISig_4_18f62 7;
BA_ "GenSigMaxLatency" SG_ 2566268256 GPSData_AntennaStat_ISig_4_18f62 523;
BA_ "NeedsUpdateBit" SG_ 2566268256 GPSData_AntennaStat_ISig_4_18f62 1;
BA_ "Platform_VMCU1_Sig" SG_ 2566268256 GPSData_AntennaStat_ISig_4_18f62 1;
BA_ "SystemSignalLongSymbol" SG_ 2566268256 GPSData_AntennaStat_ISig_4_18f62 "GPSData_AntennaStat_ISig_4_18f62560";
BA_ "GenSigSendType" SG_ 2566268001 HMIIOM_BB2_19P_FCS_18f62461 7;
BA_ "Platform_VMCU1_Sig" SG_ 2566268001 HMIIOM_BB2_19P_FCS_18f62461 1;
BA_ "GenSigCycleTime" SG_ 2566268000 GPSData_HDOP_ISig_4_18f62460 100;
BA_ "GenSigCycleTimeActive" SG_ 2566268000 GPSData_HDOP_ISig_4_18f62460 100;
BA_ "GenSigMaxLatency" SG_ 2566268000 GPSData_HDOP_ISig_4_18f62460 523;
BA_ "NeedsUpdateBit" SG_ 2566268000 GPSData_HDOP_ISig_4_18f62460 1;
BA_ "Platform_VMCU1_Sig" SG_ 2566268000 GPSData_HDOP_ISig_4_18f62460 1;
BA_ "GenSigCycleTime" SG_ 2566268000 GPSData_VehSpeed_ISig_4_18f62460 100;
BA_ "GenSigCycleTimeActive" SG_ 2566268000 GPSData_VehSpeed_ISig_4_18f62460 100;
BA_ "GenSigStartValue" SG_ 2566268000 GPSData_VehSpeed_ISig_4_18f62460 65535;
BA_ "GenSigMaxLatency" SG_ 2566268000 GPSData_VehSpeed_ISig_4_18f62460 523;
BA_ "NeedsUpdateBit" SG_ 2566268000 GPSData_VehSpeed_ISig_4_18f62460 1;
BA_ "Platform_VMCU1_Sig" SG_ 2566268000 GPSData_VehSpeed_ISig_4_18f62460 1;
BA_ "GenSigCycleTime" SG_ 2566268000 GPSData_Direction_ISig_4_18f6246 100;
BA_ "GenSigCycleTimeActive" SG_ 2566268000 GPSData_Direction_ISig_4_18f6246 100;
BA_ "GenSigMaxLatency" SG_ 2566268000 GPSData_Direction_ISig_4_18f6246 523;
BA_ "NeedsUpdateBit" SG_ 2566268000 GPSData_Direction_ISig_4_18f6246 1;
BA_ "Platform_VMCU1_Sig" SG_ 2566268000 GPSData_Direction_ISig_4_18f6246 1;
BA_ "SystemSignalLongSymbol" SG_ 2566268000 GPSData_Direction_ISig_4_18f6246 "GPSData_Direction_ISig_4_18f62460";
BA_ "GenSigCycleTime" SG_ 2566268000 GPSData_Longitude_ISig_4_18f6246 100;
BA_ "GenSigCycleTimeActive" SG_ 2566268000 GPSData_Longitude_ISig_4_18f6246 100;
BA_ "GenSigStartValue" SG_ 2566268000 GPSData_Longitude_ISig_4_18f6246 4294967295;
BA_ "GenSigMaxLatency" SG_ 2566268000 GPSData_Longitude_ISig_4_18f6246 523;
BA_ "NeedsUpdateBit" SG_ 2566268000 GPSData_Longitude_ISig_4_18f6246 1;
BA_ "Platform_VMCU1_Sig" SG_ 2566268000 GPSData_Longitude_ISig_4_18f6246 1;
BA_ "SystemSignalLongSymbol" SG_ 2566268000 GPSData_Longitude_ISig_4_18f6246 "GPSData_Longitude_ISig_4_18f62460";
BA_ "GenSigSendType" SG_ 2566268000 GPSData_sg_UB_ISig_4_18f62460 7;
BA_ "Platform_VMCU1_Sig" SG_ 2566268000 GPSData_sg_UB_ISig_4_18f62460 1;
BA_ "GenSigCycleTime" SG_ 2566268000 GPSData_Time_ISig_4_18f62460 100;
BA_ "GenSigCycleTimeActive" SG_ 2566268000 GPSData_Time_ISig_4_18f62460 100;
BA_ "GenSigStartValue" SG_ 2566268000 GPSData_Time_ISig_4_18f62460 4294967295;
BA_ "GenSigMaxLatency" SG_ 2566268000 GPSData_Time_ISig_4_18f62460 523;
BA_ "NeedsUpdateBit" SG_ 2566268000 GPSData_Time_ISig_4_18f62460 1;
BA_ "Platform_VMCU1_Sig" SG_ 2566268000 GPSData_Time_ISig_4_18f62460 1;
BA_ "GenSigCycleTime" SG_ 2566268000 GPSData_Latitude_ISig_4_18f62460 100;
BA_ "GenSigCycleTimeActive" SG_ 2566268000 GPSData_Latitude_ISig_4_18f62460 100;
BA_ "GenSigStartValue" SG_ 2566268000 GPSData_Latitude_ISig_4_18f62460 4294967295;
BA_ "GenSigMaxLatency" SG_ 2566268000 GPSData_Latitude_ISig_4_18f62460 523;
BA_ "NeedsUpdateBit" SG_ 2566268000 GPSData_Latitude_ISig_4_18f62460 1;
BA_ "Platform_VMCU1_Sig" SG_ 2566268000 GPSData_Latitude_ISig_4_18f62460 1;
BA_ "GenSigCycleTime" SG_ 2566268000 GPSData_AntennaStat_ISig_4__0000 100;
BA_ "GenSigCycleTimeActive" SG_ 2566268000 GPSData_AntennaStat_ISig_4__0000 100;
BA_ "GenSigStartValue" SG_ 2566268000 GPSData_AntennaStat_ISig_4__0000 7;
BA_ "GenSigMaxLatency" SG_ 2566268000 GPSData_AntennaStat_ISig_4__0000 523;
BA_ "NeedsUpdateBit" SG_ 2566268000 GPSData_AntennaStat_ISig_4__0000 1;
BA_ "Platform_VMCU1_Sig" SG_ 2566268000 GPSData_AntennaStat_ISig_4__0000 1;
BA_ "SystemSignalLongSymbol" SG_ 2566268000 GPSData_AntennaStat_ISig_4__0000 "GPSData_AntennaStat_ISig_4_18f62460";
BA_ "GenSigCycleTime" SG_ 2566268000 GPSData_Altitude_ISig_4_18f62460 100;
BA_ "GenSigCycleTimeActive" SG_ 2566268000 GPSData_Altitude_ISig_4_18f62460 100;
BA_ "GenSigStartValue" SG_ 2566268000 GPSData_Altitude_ISig_4_18f62460 65535;
BA_ "GenSigMaxLatency" SG_ 2566268000 GPSData_Altitude_ISig_4_18f62460 523;
BA_ "NeedsUpdateBit" SG_ 2566268000 GPSData_Altitude_ISig_4_18f62460 1;
BA_ "Platform_VMCU1_Sig" SG_ 2566268000 GPSData_Altitude_ISig_4_18f62460 1;
BA_ "GenSigSendType" SG_ 2566268513 HMIIOM_BB2_19P_FCS_18f62661 7;
BA_ "Platform_VMCU1_Sig" SG_ 2566268513 HMIIOM_BB2_19P_FCS_18f62661 1;
BA_ "GenSigCycleTime" SG_ 2566268512 GPSData_HDOP_ISig_4_18f62660 100;
BA_ "GenSigCycleTimeActive" SG_ 2566268512 GPSData_HDOP_ISig_4_18f62660 100;
BA_ "GenSigMaxLatency" SG_ 2566268512 GPSData_HDOP_ISig_4_18f62660 523;
BA_ "NeedsUpdateBit" SG_ 2566268512 GPSData_HDOP_ISig_4_18f62660 1;
BA_ "Platform_VMCU1_Sig" SG_ 2566268512 GPSData_HDOP_ISig_4_18f62660 1;
BA_ "GenSigCycleTime" SG_ 2566268512 GPSData_VehSpeed_ISig_4_18f62660 100;
BA_ "GenSigCycleTimeActive" SG_ 2566268512 GPSData_VehSpeed_ISig_4_18f62660 100;
BA_ "GenSigStartValue" SG_ 2566268512 GPSData_VehSpeed_ISig_4_18f62660 65535;
BA_ "GenSigMaxLatency" SG_ 2566268512 GPSData_VehSpeed_ISig_4_18f62660 523;
BA_ "NeedsUpdateBit" SG_ 2566268512 GPSData_VehSpeed_ISig_4_18f62660 1;
BA_ "Platform_VMCU1_Sig" SG_ 2566268512 GPSData_VehSpeed_ISig_4_18f62660 1;
BA_ "GenSigSendType" SG_ 2566268512 GPSData_sg_UB_ISig_4_18f62660 7;
BA_ "Platform_VMCU1_Sig" SG_ 2566268512 GPSData_sg_UB_ISig_4_18f62660 1;
BA_ "GenSigCycleTime" SG_ 2566268512 GPSData_AntennaStat_ISig_4__0001 100;
BA_ "GenSigCycleTimeActive" SG_ 2566268512 GPSData_AntennaStat_ISig_4__0001 100;
BA_ "GenSigStartValue" SG_ 2566268512 GPSData_AntennaStat_ISig_4__0001 7;
BA_ "GenSigMaxLatency" SG_ 2566268512 GPSData_AntennaStat_ISig_4__0001 523;
BA_ "NeedsUpdateBit" SG_ 2566268512 GPSData_AntennaStat_ISig_4__0001 1;
BA_ "Platform_VMCU1_Sig" SG_ 2566268512 GPSData_AntennaStat_ISig_4__0001 1;
BA_ "SystemSignalLongSymbol" SG_ 2566268512 GPSData_AntennaStat_ISig_4__0001 "GPSData_AntennaStat_ISig_4_18f62660";
BA_ "GenSigCycleTime" SG_ 2566268512 GPSData_Latitude_ISig_4_18f62660 100;
BA_ "GenSigCycleTimeActive" SG_ 2566268512 GPSData_Latitude_ISig_4_18f62660 100;
BA_ "GenSigStartValue" SG_ 2566268512 GPSData_Latitude_ISig_4_18f62660 4294967295;
BA_ "GenSigMaxLatency" SG_ 2566268512 GPSData_Latitude_ISig_4_18f62660 523;
BA_ "NeedsUpdateBit" SG_ 2566268512 GPSData_Latitude_ISig_4_18f62660 1;
BA_ "Platform_VMCU1_Sig" SG_ 2566268512 GPSData_Latitude_ISig_4_18f62660 1;
BA_ "GenSigCycleTime" SG_ 2566268512 GPSData_Time_ISig_4_18f62660 100;
BA_ "GenSigCycleTimeActive" SG_ 2566268512 GPSData_Time_ISig_4_18f62660 100;
BA_ "GenSigStartValue" SG_ 2566268512 GPSData_Time_ISig_4_18f62660 4294967295;
BA_ "GenSigMaxLatency" SG_ 2566268512 GPSData_Time_ISig_4_18f62660 523;
BA_ "NeedsUpdateBit" SG_ 2566268512 GPSData_Time_ISig_4_18f62660 1;
BA_ "Platform_VMCU1_Sig" SG_ 2566268512 GPSData_Time_ISig_4_18f62660 1;
BA_ "GenSigCycleTime" SG_ 2566268512 GPSData_Direction_ISig_4_18f6266 100;
BA_ "GenSigCycleTimeActive" SG_ 2566268512 GPSData_Direction_ISig_4_18f6266 100;
BA_ "GenSigMaxLatency" SG_ 2566268512 GPSData_Direction_ISig_4_18f6266 523;
BA_ "NeedsUpdateBit" SG_ 2566268512 GPSData_Direction_ISig_4_18f6266 1;
BA_ "Platform_VMCU1_Sig" SG_ 2566268512 GPSData_Direction_ISig_4_18f6266 1;
BA_ "SystemSignalLongSymbol" SG_ 2566268512 GPSData_Direction_ISig_4_18f6266 "GPSData_Direction_ISig_4_18f62660";
BA_ "GenSigCycleTime" SG_ 2566268512 GPSData_Longitude_ISig_4_18f6266 100;
BA_ "GenSigCycleTimeActive" SG_ 2566268512 GPSData_Longitude_ISig_4_18f6266 100;
BA_ "GenSigStartValue" SG_ 2566268512 GPSData_Longitude_ISig_4_18f6266 4294967295;
BA_ "GenSigMaxLatency" SG_ 2566268512 GPSData_Longitude_ISig_4_18f6266 523;
BA_ "NeedsUpdateBit" SG_ 2566268512 GPSData_Longitude_ISig_4_18f6266 1;
BA_ "Platform_VMCU1_Sig" SG_ 2566268512 GPSData_Longitude_ISig_4_18f6266 1;
BA_ "SystemSignalLongSymbol" SG_ 2566268512 GPSData_Longitude_ISig_4_18f6266 "GPSData_Longitude_ISig_4_18f62660";
BA_ "GenSigCycleTime" SG_ 2566268512 GPSData_Altitude_ISig_4_18f62660 100;
BA_ "GenSigCycleTimeActive" SG_ 2566268512 GPSData_Altitude_ISig_4_18f62660 100;
BA_ "GenSigStartValue" SG_ 2566268512 GPSData_Altitude_ISig_4_18f62660 65535;
BA_ "GenSigMaxLatency" SG_ 2566268512 GPSData_Altitude_ISig_4_18f62660 523;
BA_ "NeedsUpdateBit" SG_ 2566268512 GPSData_Altitude_ISig_4_18f62660 1;
BA_ "Platform_VMCU1_Sig" SG_ 2566268512 GPSData_Altitude_ISig_4_18f62660 1;
BA_ "GenSigSendType" SG_ 2566269025 HMIIOM_BB2_19P_FCS_18f62861 7;
BA_ "Platform_VMCU1_Sig" SG_ 2566269025 HMIIOM_BB2_19P_FCS_18f62861 1;
BA_ "GenSigCycleTime" SG_ 2566269024 GPSData_HDOP_ISig_4_18f62860 100;
BA_ "GenSigCycleTimeActive" SG_ 2566269024 GPSData_HDOP_ISig_4_18f62860 100;
BA_ "GenSigMaxLatency" SG_ 2566269024 GPSData_HDOP_ISig_4_18f62860 523;
BA_ "NeedsUpdateBit" SG_ 2566269024 GPSData_HDOP_ISig_4_18f62860 1;
BA_ "Platform_VMCU1_Sig" SG_ 2566269024 GPSData_HDOP_ISig_4_18f62860 1;
BA_ "GenSigCycleTime" SG_ 2566269024 GPSData_Latitude_ISig_4_18f62860 100;
BA_ "GenSigCycleTimeActive" SG_ 2566269024 GPSData_Latitude_ISig_4_18f62860 100;
BA_ "GenSigStartValue" SG_ 2566269024 GPSData_Latitude_ISig_4_18f62860 4294967295;
BA_ "GenSigMaxLatency" SG_ 2566269024 GPSData_Latitude_ISig_4_18f62860 523;
BA_ "NeedsUpdateBit" SG_ 2566269024 GPSData_Latitude_ISig_4_18f62860 1;
BA_ "Platform_VMCU1_Sig" SG_ 2566269024 GPSData_Latitude_ISig_4_18f62860 1;
BA_ "GenSigCycleTime" SG_ 2566269024 GPSData_Time_ISig_4_18f62860 100;
BA_ "GenSigCycleTimeActive" SG_ 2566269024 GPSData_Time_ISig_4_18f62860 100;
BA_ "GenSigStartValue" SG_ 2566269024 GPSData_Time_ISig_4_18f62860 4294967295;
BA_ "GenSigMaxLatency" SG_ 2566269024 GPSData_Time_ISig_4_18f62860 523;
BA_ "NeedsUpdateBit" SG_ 2566269024 GPSData_Time_ISig_4_18f62860 1;
BA_ "Platform_VMCU1_Sig" SG_ 2566269024 GPSData_Time_ISig_4_18f62860 1;
BA_ "GenSigCycleTime" SG_ 2566269024 GPSData_Direction_ISig_4_18f6286 100;
BA_ "GenSigCycleTimeActive" SG_ 2566269024 GPSData_Direction_ISig_4_18f6286 100;
BA_ "GenSigMaxLatency" SG_ 2566269024 GPSData_Direction_ISig_4_18f6286 523;
BA_ "NeedsUpdateBit" SG_ 2566269024 GPSData_Direction_ISig_4_18f6286 1;
BA_ "Platform_VMCU1_Sig" SG_ 2566269024 GPSData_Direction_ISig_4_18f6286 1;
BA_ "SystemSignalLongSymbol" SG_ 2566269024 GPSData_Direction_ISig_4_18f6286 "GPSData_Direction_ISig_4_18f62860";
BA_ "GenSigSendType" SG_ 2566269024 GPSData_sg_UB_ISig_4_18f62860 7;
BA_ "Platform_VMCU1_Sig" SG_ 2566269024 GPSData_sg_UB_ISig_4_18f62860 1;
BA_ "GenSigCycleTime" SG_ 2566269024 GPSData_AntennaStat_ISig_4__0002 100;
BA_ "GenSigCycleTimeActive" SG_ 2566269024 GPSData_AntennaStat_ISig_4__0002 100;
BA_ "GenSigStartValue" SG_ 2566269024 GPSData_AntennaStat_ISig_4__0002 7;
BA_ "GenSigMaxLatency" SG_ 2566269024 GPSData_AntennaStat_ISig_4__0002 523;
BA_ "NeedsUpdateBit" SG_ 2566269024 GPSData_AntennaStat_ISig_4__0002 1;
BA_ "Platform_VMCU1_Sig" SG_ 2566269024 GPSData_AntennaStat_ISig_4__0002 1;
BA_ "SystemSignalLongSymbol" SG_ 2566269024 GPSData_AntennaStat_ISig_4__0002 "GPSData_AntennaStat_ISig_4_18f62860";
BA_ "GenSigCycleTime" SG_ 2566269024 GPSData_Longitude_ISig_4_18f6286 100;
BA_ "GenSigCycleTimeActive" SG_ 2566269024 GPSData_Longitude_ISig_4_18f6286 100;
BA_ "GenSigStartValue" SG_ 2566269024 GPSData_Longitude_ISig_4_18f6286 4294967295;
BA_ "GenSigMaxLatency" SG_ 2566269024 GPSData_Longitude_ISig_4_18f6286 523;
BA_ "NeedsUpdateBit" SG_ 2566269024 GPSData_Longitude_ISig_4_18f6286 1;
BA_ "Platform_VMCU1_Sig" SG_ 2566269024 GPSData_Longitude_ISig_4_18f6286 1;
BA_ "SystemSignalLongSymbol" SG_ 2566269024 GPSData_Longitude_ISig_4_18f6286 "GPSData_Longitude_ISig_4_18f62860";
BA_ "GenSigCycleTime" SG_ 2566269024 GPSData_VehSpeed_ISig_4_18f62860 100;
BA_ "GenSigCycleTimeActive" SG_ 2566269024 GPSData_VehSpeed_ISig_4_18f62860 100;
BA_ "GenSigStartValue" SG_ 2566269024 GPSData_VehSpeed_ISig_4_18f62860 65535;
BA_ "GenSigMaxLatency" SG_ 2566269024 GPSData_VehSpeed_ISig_4_18f62860 523;
BA_ "NeedsUpdateBit" SG_ 2566269024 GPSData_VehSpeed_ISig_4_18f62860 1;
BA_ "Platform_VMCU1_Sig" SG_ 2566269024 GPSData_VehSpeed_ISig_4_18f62860 1;
BA_ "GenSigCycleTime" SG_ 2566269024 GPSData_Altitude_ISig_4_18f62860 100;
BA_ "GenSigCycleTimeActive" SG_ 2566269024 GPSData_Altitude_ISig_4_18f62860 100;
BA_ "GenSigStartValue" SG_ 2566269024 GPSData_Altitude_ISig_4_18f62860 65535;
BA_ "GenSigMaxLatency" SG_ 2566269024 GPSData_Altitude_ISig_4_18f62860 523;
BA_ "NeedsUpdateBit" SG_ 2566269024 GPSData_Altitude_ISig_4_18f62860 1;
BA_ "Platform_VMCU1_Sig" SG_ 2566269024 GPSData_Altitude_ISig_4_18f62860 1;
BA_ "GenSigSendType" SG_ 2566268769 HMIIOM_BB2_19P_FCS_18f62761 7;
BA_ "Platform_VMCU1_Sig" SG_ 2566268769 HMIIOM_BB2_19P_FCS_18f62761 1;
BA_ "GenSigCycleTime" SG_ 2566268768 GPSData_Time_ISig_4_18f62760 100;
BA_ "GenSigCycleTimeActive" SG_ 2566268768 GPSData_Time_ISig_4_18f62760 100;
BA_ "GenSigStartValue" SG_ 2566268768 GPSData_Time_ISig_4_18f62760 4294967295;
BA_ "GenSigMaxLatency" SG_ 2566268768 GPSData_Time_ISig_4_18f62760 523;
BA_ "NeedsUpdateBit" SG_ 2566268768 GPSData_Time_ISig_4_18f62760 1;
BA_ "Platform_VMCU1_Sig" SG_ 2566268768 GPSData_Time_ISig_4_18f62760 1;
BA_ "GenSigCycleTime" SG_ 2566268768 GPSData_HDOP_ISig_4_18f62760 100;
BA_ "GenSigCycleTimeActive" SG_ 2566268768 GPSData_HDOP_ISig_4_18f62760 100;
BA_ "GenSigMaxLatency" SG_ 2566268768 GPSData_HDOP_ISig_4_18f62760 523;
BA_ "NeedsUpdateBit" SG_ 2566268768 GPSData_HDOP_ISig_4_18f62760 1;
BA_ "Platform_VMCU1_Sig" SG_ 2566268768 GPSData_HDOP_ISig_4_18f62760 1;
BA_ "GenSigCycleTime" SG_ 2566268768 GPSData_Direction_ISig_4_18f6276 100;
BA_ "GenSigCycleTimeActive" SG_ 2566268768 GPSData_Direction_ISig_4_18f6276 100;
BA_ "GenSigMaxLatency" SG_ 2566268768 GPSData_Direction_ISig_4_18f6276 523;
BA_ "NeedsUpdateBit" SG_ 2566268768 GPSData_Direction_ISig_4_18f6276 1;
BA_ "Platform_VMCU1_Sig" SG_ 2566268768 GPSData_Direction_ISig_4_18f6276 1;
BA_ "SystemSignalLongSymbol" SG_ 2566268768 GPSData_Direction_ISig_4_18f6276 "GPSData_Direction_ISig_4_18f62760";
BA_ "GenSigCycleTime" SG_ 2566268768 GPSData_Longitude_ISig_4_18f6276 100;
BA_ "GenSigCycleTimeActive" SG_ 2566268768 GPSData_Longitude_ISig_4_18f6276 100;
BA_ "GenSigStartValue" SG_ 2566268768 GPSData_Longitude_ISig_4_18f6276 4294967295;
BA_ "GenSigMaxLatency" SG_ 2566268768 GPSData_Longitude_ISig_4_18f6276 523;
BA_ "NeedsUpdateBit" SG_ 2566268768 GPSData_Longitude_ISig_4_18f6276 1;
BA_ "Platform_VMCU1_Sig" SG_ 2566268768 GPSData_Longitude_ISig_4_18f6276 1;
BA_ "SystemSignalLongSymbol" SG_ 2566268768 GPSData_Longitude_ISig_4_18f6276 "GPSData_Longitude_ISig_4_18f62760";
BA_ "GenSigSendType" SG_ 2566268768 GPSData_sg_UB_ISig_4_18f62760 7;
BA_ "Platform_VMCU1_Sig" SG_ 2566268768 GPSData_sg_UB_ISig_4_18f62760 1;
BA_ "GenSigCycleTime" SG_ 2566268768 GPSData_VehSpeed_ISig_4_18f62760 100;
BA_ "GenSigCycleTimeActive" SG_ 2566268768 GPSData_VehSpeed_ISig_4_18f62760 100;
BA_ "GenSigStartValue" SG_ 2566268768 GPSData_VehSpeed_ISig_4_18f62760 65535;
BA_ "GenSigMaxLatency" SG_ 2566268768 GPSData_VehSpeed_ISig_4_18f62760 523;
BA_ "NeedsUpdateBit" SG_ 2566268768 GPSData_VehSpeed_ISig_4_18f62760 1;
BA_ "Platform_VMCU1_Sig" SG_ 2566268768 GPSData_VehSpeed_ISig_4_18f62760 1;
BA_ "GenSigCycleTime" SG_ 2566268768 GPSData_Altitude_ISig_4_18f62760 100;
BA_ "GenSigCycleTimeActive" SG_ 2566268768 GPSData_Altitude_ISig_4_18f62760 100;
BA_ "GenSigStartValue" SG_ 2566268768 GPSData_Altitude_ISig_4_18f62760 65535;
BA_ "GenSigMaxLatency" SG_ 2566268768 GPSData_Altitude_ISig_4_18f62760 523;
BA_ "NeedsUpdateBit" SG_ 2566268768 GPSData_Altitude_ISig_4_18f62760 1;
BA_ "Platform_VMCU1_Sig" SG_ 2566268768 GPSData_Altitude_ISig_4_18f62760 1;
BA_ "GenSigCycleTime" SG_ 2566268768 GPSData_Latitude_ISig_4_18f62760 100;
BA_ "GenSigCycleTimeActive" SG_ 2566268768 GPSData_Latitude_ISig_4_18f62760 100;
BA_ "GenSigStartValue" SG_ 2566268768 GPSData_Latitude_ISig_4_18f62760 4294967295;
BA_ "GenSigMaxLatency" SG_ 2566268768 GPSData_Latitude_ISig_4_18f62760 523;
BA_ "NeedsUpdateBit" SG_ 2566268768 GPSData_Latitude_ISig_4_18f62760 1;
BA_ "Platform_VMCU1_Sig" SG_ 2566268768 GPSData_Latitude_ISig_4_18f62760 1;
BA_ "GenSigCycleTime" SG_ 2566268768 GPSData_AntennaStat_ISig_4__0003 100;
BA_ "GenSigCycleTimeActive" SG_ 2566268768 GPSData_AntennaStat_ISig_4__0003 100;
BA_ "GenSigStartValue" SG_ 2566268768 GPSData_AntennaStat_ISig_4__0003 7;
BA_ "GenSigMaxLatency" SG_ 2566268768 GPSData_AntennaStat_ISig_4__0003 523;
BA_ "NeedsUpdateBit" SG_ 2566268768 GPSData_AntennaStat_ISig_4__0003 1;
BA_ "Platform_VMCU1_Sig" SG_ 2566268768 GPSData_AntennaStat_ISig_4__0003 1;
BA_ "SystemSignalLongSymbol" SG_ 2566268768 GPSData_AntennaStat_ISig_4__0003 "GPSData_AntennaStat_ISig_4_18f62760";
BA_ "GenSigCycleTime" SG_ 2566846816 Trailer5Type_ISig_4 100;
BA_ "GenSigCycleTimeActive" SG_ 2566846816 Trailer5Type_ISig_4 100;
BA_ "GenSigStartValue" SG_ 2566846816 Trailer5Type_ISig_4 7;
BA_ "GenSigMaxLatency" SG_ 2566846816 Trailer5Type_ISig_4 1036;
BA_ "Platform_VMCU1_Sig" SG_ 2566846816 Trailer5Type_ISig_4 1;
BA_ "GenSigCycleTime" SG_ 2566846816 Trailer4NumberOfAxles_ISig_4 100;
BA_ "GenSigCycleTimeActive" SG_ 2566846816 Trailer4NumberOfAxles_ISig_4 100;
BA_ "GenSigStartValue" SG_ 2566846816 Trailer4NumberOfAxles_ISig_4 255;
BA_ "GenSigMaxLatency" SG_ 2566846816 Trailer4NumberOfAxles_ISig_4 1036;
BA_ "Platform_VMCU1_Sig" SG_ 2566846816 Trailer4NumberOfAxles_ISig_4 1;
BA_ "GenSigCycleTime" SG_ 2566846816 Trailer2NumberOfAxles_ISig_4 100;
BA_ "GenSigCycleTimeActive" SG_ 2566846816 Trailer2NumberOfAxles_ISig_4 100;
BA_ "GenSigStartValue" SG_ 2566846816 Trailer2NumberOfAxles_ISig_4 255;
BA_ "GenSigMaxLatency" SG_ 2566846816 Trailer2NumberOfAxles_ISig_4 1036;
BA_ "Platform_VMCU1_Sig" SG_ 2566846816 Trailer2NumberOfAxles_ISig_4 1;
BA_ "GenSigCycleTime" SG_ 2566846816 Trailer3Type_ISig_4 100;
BA_ "GenSigCycleTimeActive" SG_ 2566846816 Trailer3Type_ISig_4 100;
BA_ "GenSigStartValue" SG_ 2566846816 Trailer3Type_ISig_4 7;
BA_ "GenSigMaxLatency" SG_ 2566846816 Trailer3Type_ISig_4 1036;
BA_ "Platform_VMCU1_Sig" SG_ 2566846816 Trailer3Type_ISig_4 1;
BA_ "GenSigCycleTime" SG_ 2566846816 Trailer3NumberOfAxles_ISig_4 100;
BA_ "GenSigCycleTimeActive" SG_ 2566846816 Trailer3NumberOfAxles_ISig_4 100;
BA_ "GenSigStartValue" SG_ 2566846816 Trailer3NumberOfAxles_ISig_4 255;
BA_ "GenSigMaxLatency" SG_ 2566846816 Trailer3NumberOfAxles_ISig_4 1036;
BA_ "Platform_VMCU1_Sig" SG_ 2566846816 Trailer3NumberOfAxles_ISig_4 1;
BA_ "GenSigCycleTime" SG_ 2566846816 Trailer1NumberOfAxles_ISig_4 100;
BA_ "GenSigCycleTimeActive" SG_ 2566846816 Trailer1NumberOfAxles_ISig_4 100;
BA_ "GenSigStartValue" SG_ 2566846816 Trailer1NumberOfAxles_ISig_4 255;
BA_ "GenSigMaxLatency" SG_ 2566846816 Trailer1NumberOfAxles_ISig_4 1036;
BA_ "Platform_VMCU1_Sig" SG_ 2566846816 Trailer1NumberOfAxles_ISig_4 1;
BA_ "GenSigCycleTime" SG_ 2566846816 Trailer5NumberOfAxles_ISig_4 100;
BA_ "GenSigCycleTimeActive" SG_ 2566846816 Trailer5NumberOfAxles_ISig_4 100;
BA_ "GenSigStartValue" SG_ 2566846816 Trailer5NumberOfAxles_ISig_4 255;
BA_ "GenSigMaxLatency" SG_ 2566846816 Trailer5NumberOfAxles_ISig_4 1036;
BA_ "Platform_VMCU1_Sig" SG_ 2566846816 Trailer5NumberOfAxles_ISig_4 1;
BA_ "GenSigCycleTime" SG_ 2566846816 Trailer1Type_ISig_4 100;
BA_ "GenSigCycleTimeActive" SG_ 2566846816 Trailer1Type_ISig_4 100;
BA_ "GenSigStartValue" SG_ 2566846816 Trailer1Type_ISig_4 7;
BA_ "GenSigMaxLatency" SG_ 2566846816 Trailer1Type_ISig_4 1036;
BA_ "Platform_VMCU1_Sig" SG_ 2566846816 Trailer1Type_ISig_4 1;
BA_ "GenSigCycleTime" SG_ 2566846816 Trailer4Type_ISig_4 100;
BA_ "GenSigCycleTimeActive" SG_ 2566846816 Trailer4Type_ISig_4 100;
BA_ "GenSigStartValue" SG_ 2566846816 Trailer4Type_ISig_4 7;
BA_ "GenSigMaxLatency" SG_ 2566846816 Trailer4Type_ISig_4 1036;
BA_ "Platform_VMCU1_Sig" SG_ 2566846816 Trailer4Type_ISig_4 1;
BA_ "GenSigCycleTime" SG_ 2566846816 Trailer2Type_ISig_4 100;
BA_ "GenSigCycleTimeActive" SG_ 2566846816 Trailer2Type_ISig_4 100;
BA_ "GenSigStartValue" SG_ 2566846816 Trailer2Type_ISig_4 7;
BA_ "GenSigMaxLatency" SG_ 2566846816 Trailer2Type_ISig_4 1036;
BA_ "Platform_VMCU1_Sig" SG_ 2566846816 Trailer2Type_ISig_4 1;
BA_ "GenSigCycleTime" SG_ 2566802272 Trailer5CalAxleLoad_AxleId_ISig_ 100;
BA_ "GenSigCycleTimeActive" SG_ 2566802272 Trailer5CalAxleLoad_AxleId_ISig_ 100;
BA_ "GenSigMaxLatency" SG_ 2566802272 Trailer5CalAxleLoad_AxleId_ISig_ 1035;
BA_ "Platform_VMCU1_Sig" SG_ 2566802272 Trailer5CalAxleLoad_AxleId_ISig_ 1;
BA_ "SystemSignalLongSymbol" SG_ 2566802272 Trailer5CalAxleLoad_AxleId_ISig_ "Trailer5CalAxleLoad_AxleId_ISig_4";
BA_ "GenSigCycleTime" SG_ 2566802272 Trailer5NumberOfFrontAxles_ISig_ 100;
BA_ "GenSigCycleTimeActive" SG_ 2566802272 Trailer5NumberOfFrontAxles_ISig_ 100;
BA_ "GenSigStartValue" SG_ 2566802272 Trailer5NumberOfFrontAxles_ISig_ 15;
BA_ "Platform_VMCU1_Sig" SG_ 2566802272 Trailer5NumberOfFrontAxles_ISig_ 1;
BA_ "SystemSignalLongSymbol" SG_ 2566802272 Trailer5NumberOfFrontAxles_ISig_ "Trailer5NumberOfFrontAxles_ISig_4";
BA_ "GenSigCycleTime" SG_ 2566802272 Trailer5CalibratedCargoLoad_ISig 100;
BA_ "GenSigCycleTimeActive" SG_ 2566802272 Trailer5CalibratedCargoLoad_ISig 100;
BA_ "GenSigStartValue" SG_ 2566802272 Trailer5CalibratedCargoLoad_ISig 65535;
BA_ "GenSigMaxLatency" SG_ 2566802272 Trailer5CalibratedCargoLoad_ISig 1035;
BA_ "Platform_VMCU1_Sig" SG_ 2566802272 Trailer5CalibratedCargoLoad_ISig 1;
BA_ "SystemSignalLongSymbol" SG_ 2566802272 Trailer5CalibratedCargoLoad_ISig "Trailer5CalibratedCargoLoad_ISig_4";
BA_ "GenSigCycleTime" SG_ 2566802272 Trailer5CalAxleLoad_AxleLoad_ISi 100;
BA_ "GenSigCycleTimeActive" SG_ 2566802272 Trailer5CalAxleLoad_AxleLoad_ISi 100;
BA_ "GenSigStartValue" SG_ 2566802272 Trailer5CalAxleLoad_AxleLoad_ISi 65535;
BA_ "GenSigMaxLatency" SG_ 2566802272 Trailer5CalAxleLoad_AxleLoad_ISi 1035;
BA_ "Platform_VMCU1_Sig" SG_ 2566802272 Trailer5CalAxleLoad_AxleLoad_ISi 1;
BA_ "SystemSignalLongSymbol" SG_ 2566802272 Trailer5CalAxleLoad_AxleLoad_ISi "Trailer5CalAxleLoad_AxleLoad_ISig_4";
BA_ "GenSigCycleTime" SG_ 2566802272 Trailer5CalibratedTotalLoad_ISig 100;
BA_ "GenSigCycleTimeActive" SG_ 2566802272 Trailer5CalibratedTotalLoad_ISig 100;
BA_ "GenSigStartValue" SG_ 2566802272 Trailer5CalibratedTotalLoad_ISig 65535;
BA_ "GenSigMaxLatency" SG_ 2566802272 Trailer5CalibratedTotalLoad_ISig 1035;
BA_ "Platform_VMCU1_Sig" SG_ 2566802272 Trailer5CalibratedTotalLoad_ISig 1;
BA_ "SystemSignalLongSymbol" SG_ 2566802272 Trailer5CalibratedTotalLoad_ISig "Trailer5CalibratedTotalLoad_ISig_4";
BA_ "GenSigCycleTime" SG_ 2566757728 Trailer4CalAxleLoad_AxleId_ISig_ 100;
BA_ "GenSigCycleTimeActive" SG_ 2566757728 Trailer4CalAxleLoad_AxleId_ISig_ 100;
BA_ "GenSigMaxLatency" SG_ 2566757728 Trailer4CalAxleLoad_AxleId_ISig_ 1034;
BA_ "Platform_VMCU1_Sig" SG_ 2566757728 Trailer4CalAxleLoad_AxleId_ISig_ 1;
BA_ "SystemSignalLongSymbol" SG_ 2566757728 Trailer4CalAxleLoad_AxleId_ISig_ "Trailer4CalAxleLoad_AxleId_ISig_4";
BA_ "GenSigCycleTime" SG_ 2566757728 Trailer4NumberOfFrontAxles_ISig_ 100;
BA_ "GenSigCycleTimeActive" SG_ 2566757728 Trailer4NumberOfFrontAxles_ISig_ 100;
BA_ "GenSigStartValue" SG_ 2566757728 Trailer4NumberOfFrontAxles_ISig_ 15;
BA_ "Platform_VMCU1_Sig" SG_ 2566757728 Trailer4NumberOfFrontAxles_ISig_ 1;
BA_ "SystemSignalLongSymbol" SG_ 2566757728 Trailer4NumberOfFrontAxles_ISig_ "Trailer4NumberOfFrontAxles_ISig_4";
BA_ "GenSigCycleTime" SG_ 2566757728 Trailer4CalibratedTotalLoad_ISig 100;
BA_ "GenSigCycleTimeActive" SG_ 2566757728 Trailer4CalibratedTotalLoad_ISig 100;
BA_ "GenSigStartValue" SG_ 2566757728 Trailer4CalibratedTotalLoad_ISig 65535;
BA_ "GenSigMaxLatency" SG_ 2566757728 Trailer4CalibratedTotalLoad_ISig 1034;
BA_ "Platform_VMCU1_Sig" SG_ 2566757728 Trailer4CalibratedTotalLoad_ISig 1;
BA_ "SystemSignalLongSymbol" SG_ 2566757728 Trailer4CalibratedTotalLoad_ISig "Trailer4CalibratedTotalLoad_ISig_4";
BA_ "GenSigCycleTime" SG_ 2566757728 Trailer4CalAxleLoad_AxleLoad_ISi 100;
BA_ "GenSigCycleTimeActive" SG_ 2566757728 Trailer4CalAxleLoad_AxleLoad_ISi 100;
BA_ "GenSigStartValue" SG_ 2566757728 Trailer4CalAxleLoad_AxleLoad_ISi 65535;
BA_ "GenSigMaxLatency" SG_ 2566757728 Trailer4CalAxleLoad_AxleLoad_ISi 1034;
BA_ "Platform_VMCU1_Sig" SG_ 2566757728 Trailer4CalAxleLoad_AxleLoad_ISi 1;
BA_ "SystemSignalLongSymbol" SG_ 2566757728 Trailer4CalAxleLoad_AxleLoad_ISi "Trailer4CalAxleLoad_AxleLoad_ISig_4";
BA_ "GenSigCycleTime" SG_ 2566757728 Trailer4CalibratedCargoLoad_ISig 100;
BA_ "GenSigCycleTimeActive" SG_ 2566757728 Trailer4CalibratedCargoLoad_ISig 100;
BA_ "GenSigStartValue" SG_ 2566757728 Trailer4CalibratedCargoLoad_ISig 65535;
BA_ "GenSigMaxLatency" SG_ 2566757728 Trailer4CalibratedCargoLoad_ISig 1034;
BA_ "Platform_VMCU1_Sig" SG_ 2566757728 Trailer4CalibratedCargoLoad_ISig 1;
BA_ "SystemSignalLongSymbol" SG_ 2566757728 Trailer4CalibratedCargoLoad_ISig "Trailer4CalibratedCargoLoad_ISig_4";
BA_ "GenSigCycleTime" SG_ 2566713184 Trailer3CalAxleLoad_AxleLoad_ISi 100;
BA_ "GenSigCycleTimeActive" SG_ 2566713184 Trailer3CalAxleLoad_AxleLoad_ISi 100;
BA_ "GenSigStartValue" SG_ 2566713184 Trailer3CalAxleLoad_AxleLoad_ISi 65535;
BA_ "GenSigMaxLatency" SG_ 2566713184 Trailer3CalAxleLoad_AxleLoad_ISi 1033;
BA_ "Platform_VMCU1_Sig" SG_ 2566713184 Trailer3CalAxleLoad_AxleLoad_ISi 1;
BA_ "SystemSignalLongSymbol" SG_ 2566713184 Trailer3CalAxleLoad_AxleLoad_ISi "Trailer3CalAxleLoad_AxleLoad_ISig_4";
BA_ "GenSigCycleTime" SG_ 2566713184 Trailer3NumberOfFrontAxles_ISig_ 100;
BA_ "GenSigCycleTimeActive" SG_ 2566713184 Trailer3NumberOfFrontAxles_ISig_ 100;
BA_ "GenSigStartValue" SG_ 2566713184 Trailer3NumberOfFrontAxles_ISig_ 15;
BA_ "Platform_VMCU1_Sig" SG_ 2566713184 Trailer3NumberOfFrontAxles_ISig_ 1;
BA_ "SystemSignalLongSymbol" SG_ 2566713184 Trailer3NumberOfFrontAxles_ISig_ "Trailer3NumberOfFrontAxles_ISig_4";
BA_ "GenSigCycleTime" SG_ 2566713184 Trailer3CalibratedTotalLoad_ISig 100;
BA_ "GenSigCycleTimeActive" SG_ 2566713184 Trailer3CalibratedTotalLoad_ISig 100;
BA_ "GenSigStartValue" SG_ 2566713184 Trailer3CalibratedTotalLoad_ISig 65535;
BA_ "GenSigMaxLatency" SG_ 2566713184 Trailer3CalibratedTotalLoad_ISig 1033;
BA_ "Platform_VMCU1_Sig" SG_ 2566713184 Trailer3CalibratedTotalLoad_ISig 1;
BA_ "SystemSignalLongSymbol" SG_ 2566713184 Trailer3CalibratedTotalLoad_ISig "Trailer3CalibratedTotalLoad_ISig_4";
BA_ "GenSigCycleTime" SG_ 2566713184 Trailer3CalAxleLoad_AxleId_ISig_ 100;
BA_ "GenSigCycleTimeActive" SG_ 2566713184 Trailer3CalAxleLoad_AxleId_ISig_ 100;
BA_ "GenSigMaxLatency" SG_ 2566713184 Trailer3CalAxleLoad_AxleId_ISig_ 1033;
BA_ "Platform_VMCU1_Sig" SG_ 2566713184 Trailer3CalAxleLoad_AxleId_ISig_ 1;
BA_ "SystemSignalLongSymbol" SG_ 2566713184 Trailer3CalAxleLoad_AxleId_ISig_ "Trailer3CalAxleLoad_AxleId_ISig_4";
BA_ "GenSigCycleTime" SG_ 2566713184 Trailer3CalibratedCargoLoad_ISig 100;
BA_ "GenSigCycleTimeActive" SG_ 2566713184 Trailer3CalibratedCargoLoad_ISig 100;
BA_ "GenSigStartValue" SG_ 2566713184 Trailer3CalibratedCargoLoad_ISig 65535;
BA_ "GenSigMaxLatency" SG_ 2566713184 Trailer3CalibratedCargoLoad_ISig 1033;
BA_ "Platform_VMCU1_Sig" SG_ 2566713184 Trailer3CalibratedCargoLoad_ISig 1;
BA_ "SystemSignalLongSymbol" SG_ 2566713184 Trailer3CalibratedCargoLoad_ISig "Trailer3CalibratedCargoLoad_ISig_4";
BA_ "GenSigCycleTime" SG_ 2566668640 Trailer2NumberOfFrontAxles_ISig_ 100;
BA_ "GenSigCycleTimeActive" SG_ 2566668640 Trailer2NumberOfFrontAxles_ISig_ 100;
BA_ "GenSigStartValue" SG_ 2566668640 Trailer2NumberOfFrontAxles_ISig_ 15;
BA_ "Platform_VMCU1_Sig" SG_ 2566668640 Trailer2NumberOfFrontAxles_ISig_ 1;
BA_ "SystemSignalLongSymbol" SG_ 2566668640 Trailer2NumberOfFrontAxles_ISig_ "Trailer2NumberOfFrontAxles_ISig_4";
BA_ "GenSigCycleTime" SG_ 2566668640 Trailer2CalAxleLoad_AxleId_ISig_ 100;
BA_ "GenSigCycleTimeActive" SG_ 2566668640 Trailer2CalAxleLoad_AxleId_ISig_ 100;
BA_ "GenSigMaxLatency" SG_ 2566668640 Trailer2CalAxleLoad_AxleId_ISig_ 1032;
BA_ "Platform_VMCU1_Sig" SG_ 2566668640 Trailer2CalAxleLoad_AxleId_ISig_ 1;
BA_ "SystemSignalLongSymbol" SG_ 2566668640 Trailer2CalAxleLoad_AxleId_ISig_ "Trailer2CalAxleLoad_AxleId_ISig_4";
BA_ "GenSigCycleTime" SG_ 2566668640 Trailer2CalAxleLoad_AxleLoad_ISi 100;
BA_ "GenSigCycleTimeActive" SG_ 2566668640 Trailer2CalAxleLoad_AxleLoad_ISi 100;
BA_ "GenSigStartValue" SG_ 2566668640 Trailer2CalAxleLoad_AxleLoad_ISi 65535;
BA_ "GenSigMaxLatency" SG_ 2566668640 Trailer2CalAxleLoad_AxleLoad_ISi 1032;
BA_ "Platform_VMCU1_Sig" SG_ 2566668640 Trailer2CalAxleLoad_AxleLoad_ISi 1;
BA_ "SystemSignalLongSymbol" SG_ 2566668640 Trailer2CalAxleLoad_AxleLoad_ISi "Trailer2CalAxleLoad_AxleLoad_ISig_4";
BA_ "GenSigCycleTime" SG_ 2566668640 Trailer2CalibratedTotalLoad_ISig 100;
BA_ "GenSigCycleTimeActive" SG_ 2566668640 Trailer2CalibratedTotalLoad_ISig 100;
BA_ "GenSigStartValue" SG_ 2566668640 Trailer2CalibratedTotalLoad_ISig 65535;
BA_ "GenSigMaxLatency" SG_ 2566668640 Trailer2CalibratedTotalLoad_ISig 1032;
BA_ "Platform_VMCU1_Sig" SG_ 2566668640 Trailer2CalibratedTotalLoad_ISig 1;
BA_ "SystemSignalLongSymbol" SG_ 2566668640 Trailer2CalibratedTotalLoad_ISig "Trailer2CalibratedTotalLoad_ISig_4";
BA_ "GenSigCycleTime" SG_ 2566668640 Trailer2CalibratedCargoLoad_ISig 100;
BA_ "GenSigCycleTimeActive" SG_ 2566668640 Trailer2CalibratedCargoLoad_ISig 100;
BA_ "GenSigStartValue" SG_ 2566668640 Trailer2CalibratedCargoLoad_ISig 65535;
BA_ "GenSigMaxLatency" SG_ 2566668640 Trailer2CalibratedCargoLoad_ISig 1032;
BA_ "Platform_VMCU1_Sig" SG_ 2566668640 Trailer2CalibratedCargoLoad_ISig 1;
BA_ "SystemSignalLongSymbol" SG_ 2566668640 Trailer2CalibratedCargoLoad_ISig "Trailer2CalibratedCargoLoad_ISig_4";
BA_ "GenSigCycleTime" SG_ 2566624096 Trailer1CalAxleLoad_AxleLoad_ISi 100;
BA_ "GenSigCycleTimeActive" SG_ 2566624096 Trailer1CalAxleLoad_AxleLoad_ISi 100;
BA_ "GenSigStartValue" SG_ 2566624096 Trailer1CalAxleLoad_AxleLoad_ISi 65535;
BA_ "GenSigMaxLatency" SG_ 2566624096 Trailer1CalAxleLoad_AxleLoad_ISi 1031;
BA_ "Platform_VMCU1_Sig" SG_ 2566624096 Trailer1CalAxleLoad_AxleLoad_ISi 1;
BA_ "SystemSignalLongSymbol" SG_ 2566624096 Trailer1CalAxleLoad_AxleLoad_ISi "Trailer1CalAxleLoad_AxleLoad_ISig_4";
BA_ "GenSigCycleTime" SG_ 2566624096 Trailer1CalibratedTotalLoad_ISig 100;
BA_ "GenSigCycleTimeActive" SG_ 2566624096 Trailer1CalibratedTotalLoad_ISig 100;
BA_ "GenSigStartValue" SG_ 2566624096 Trailer1CalibratedTotalLoad_ISig 65535;
BA_ "GenSigMaxLatency" SG_ 2566624096 Trailer1CalibratedTotalLoad_ISig 1031;
BA_ "Platform_VMCU1_Sig" SG_ 2566624096 Trailer1CalibratedTotalLoad_ISig 1;
BA_ "SystemSignalLongSymbol" SG_ 2566624096 Trailer1CalibratedTotalLoad_ISig "Trailer1CalibratedTotalLoad_ISig_4";
BA_ "GenSigCycleTime" SG_ 2566624096 Trailer1CalAxleLoad_AxleId_ISig_ 100;
BA_ "GenSigCycleTimeActive" SG_ 2566624096 Trailer1CalAxleLoad_AxleId_ISig_ 100;
BA_ "GenSigMaxLatency" SG_ 2566624096 Trailer1CalAxleLoad_AxleId_ISig_ 1031;
BA_ "Platform_VMCU1_Sig" SG_ 2566624096 Trailer1CalAxleLoad_AxleId_ISig_ 1;
BA_ "SystemSignalLongSymbol" SG_ 2566624096 Trailer1CalAxleLoad_AxleId_ISig_ "Trailer1CalAxleLoad_AxleId_ISig_4";
BA_ "GenSigCycleTime" SG_ 2566624096 Trailer1NumberOfFrontAxles_ISig_ 100;
BA_ "GenSigCycleTimeActive" SG_ 2566624096 Trailer1NumberOfFrontAxles_ISig_ 100;
BA_ "GenSigStartValue" SG_ 2566624096 Trailer1NumberOfFrontAxles_ISig_ 15;
BA_ "Platform_VMCU1_Sig" SG_ 2566624096 Trailer1NumberOfFrontAxles_ISig_ 1;
BA_ "SystemSignalLongSymbol" SG_ 2566624096 Trailer1NumberOfFrontAxles_ISig_ "Trailer1NumberOfFrontAxles_ISig_4";
BA_ "GenSigCycleTime" SG_ 2566624096 Trailer1CalibratedCargoLoad_ISig 100;
BA_ "GenSigCycleTimeActive" SG_ 2566624096 Trailer1CalibratedCargoLoad_ISig 100;
BA_ "GenSigStartValue" SG_ 2566624096 Trailer1CalibratedCargoLoad_ISig 65535;
BA_ "GenSigMaxLatency" SG_ 2566624096 Trailer1CalibratedCargoLoad_ISig 1031;
BA_ "Platform_VMCU1_Sig" SG_ 2566624096 Trailer1CalibratedCargoLoad_ISig 1;
BA_ "SystemSignalLongSymbol" SG_ 2566624096 Trailer1CalibratedCargoLoad_ISig "Trailer1CalibratedCargoLoad_ISig_4";
BA_ "GenSigCycleTime" SG_ 2566579552 VehRearAxle1CalibratedLoad_ISig_ 100;
BA_ "GenSigCycleTimeActive" SG_ 2566579552 VehRearAxle1CalibratedLoad_ISig_ 100;
BA_ "GenSigStartValue" SG_ 2566579552 VehRearAxle1CalibratedLoad_ISig_ 65535;
BA_ "GenSigMaxLatency" SG_ 2566579552 VehRearAxle1CalibratedLoad_ISig_ 1024;
BA_ "Platform_VMCU1_Sig" SG_ 2566579552 VehRearAxle1CalibratedLoad_ISig_ 1;
BA_ "SystemSignalLongSymbol" SG_ 2566579552 VehRearAxle1CalibratedLoad_ISig_ "VehRearAxle1CalibratedLoad_ISig_4";
BA_ "GenSigCycleTime" SG_ 2566579552 VehRearAxle2CalibratedLoad_ISig_ 100;
BA_ "GenSigCycleTimeActive" SG_ 2566579552 VehRearAxle2CalibratedLoad_ISig_ 100;
BA_ "GenSigStartValue" SG_ 2566579552 VehRearAxle2CalibratedLoad_ISig_ 65535;
BA_ "GenSigMaxLatency" SG_ 2566579552 VehRearAxle2CalibratedLoad_ISig_ 1024;
BA_ "Platform_VMCU1_Sig" SG_ 2566579552 VehRearAxle2CalibratedLoad_ISig_ 1;
BA_ "SystemSignalLongSymbol" SG_ 2566579552 VehRearAxle2CalibratedLoad_ISig_ "VehRearAxle2CalibratedLoad_ISig_4";
BA_ "GenSigCycleTime" SG_ 2566579552 VehRearAxle3CalibratedLoad_ISig_ 100;
BA_ "GenSigCycleTimeActive" SG_ 2566579552 VehRearAxle3CalibratedLoad_ISig_ 100;
BA_ "GenSigStartValue" SG_ 2566579552 VehRearAxle3CalibratedLoad_ISig_ 65535;
BA_ "GenSigMaxLatency" SG_ 2566579552 VehRearAxle3CalibratedLoad_ISig_ 1024;
BA_ "Platform_VMCU1_Sig" SG_ 2566579552 VehRearAxle3CalibratedLoad_ISig_ 1;
BA_ "SystemSignalLongSymbol" SG_ 2566579552 VehRearAxle3CalibratedLoad_ISig_ "VehRearAxle3CalibratedLoad_ISig_4";
BA_ "GenSigCycleTime" SG_ 2566535008 VehicleCalibratedCargoLoad_ISig_ 100;
BA_ "GenSigCycleTimeActive" SG_ 2566535008 VehicleCalibratedCargoLoad_ISig_ 100;
BA_ "GenSigStartValue" SG_ 2566535008 VehicleCalibratedCargoLoad_ISig_ 65535;
BA_ "GenSigMaxLatency" SG_ 2566535008 VehicleCalibratedCargoLoad_ISig_ 1023;
BA_ "Platform_VMCU1_Sig" SG_ 2566535008 VehicleCalibratedCargoLoad_ISig_ 1;
BA_ "SystemSignalLongSymbol" SG_ 2566535008 VehicleCalibratedCargoLoad_ISig_ "VehicleCalibratedCargoLoad_ISig_4";
BA_ "GenSigCycleTime" SG_ 2566535008 VehFrontAxle2CalibratedLoad_ISig 100;
BA_ "GenSigCycleTimeActive" SG_ 2566535008 VehFrontAxle2CalibratedLoad_ISig 100;
BA_ "GenSigStartValue" SG_ 2566535008 VehFrontAxle2CalibratedLoad_ISig 65535;
BA_ "GenSigMaxLatency" SG_ 2566535008 VehFrontAxle2CalibratedLoad_ISig 1023;
BA_ "Platform_VMCU1_Sig" SG_ 2566535008 VehFrontAxle2CalibratedLoad_ISig 1;
BA_ "SystemSignalLongSymbol" SG_ 2566535008 VehFrontAxle2CalibratedLoad_ISig "VehFrontAxle2CalibratedLoad_ISig_4";
BA_ "GenSigCycleTime" SG_ 2566535008 VehFrontAxle1CalibratedLoad_ISig 100;
BA_ "GenSigCycleTimeActive" SG_ 2566535008 VehFrontAxle1CalibratedLoad_ISig 100;
BA_ "GenSigStartValue" SG_ 2566535008 VehFrontAxle1CalibratedLoad_ISig 65535;
BA_ "GenSigMaxLatency" SG_ 2566535008 VehFrontAxle1CalibratedLoad_ISig 1023;
BA_ "Platform_VMCU1_Sig" SG_ 2566535008 VehFrontAxle1CalibratedLoad_ISig 1;
BA_ "SystemSignalLongSymbol" SG_ 2566535008 VehFrontAxle1CalibratedLoad_ISig "VehFrontAxle1CalibratedLoad_ISig_4";
BA_ "GenSigCycleTime" SG_ 2566535008 VehicleCalibratedLoad_ISig_4 100;
BA_ "GenSigCycleTimeActive" SG_ 2566535008 VehicleCalibratedLoad_ISig_4 100;
BA_ "GenSigStartValue" SG_ 2566535008 VehicleCalibratedLoad_ISig_4 65535;
BA_ "GenSigMaxLatency" SG_ 2566535008 VehicleCalibratedLoad_ISig_4 1023;
BA_ "Platform_VMCU1_Sig" SG_ 2566535008 VehicleCalibratedLoad_ISig_4 1;
BA_ "GenSigCycleTime" SG_ 2515802464 AlarmClockAlarms_stat_Mode_ISig_ 100;
BA_ "GenSigCycleTimeActive" SG_ 2515802464 AlarmClockAlarms_stat_Mode_ISig_ 100;
BA_ "GenSigMaxLatency" SG_ 2515802464 AlarmClockAlarms_stat_Mode_ISig_ 169;
BA_ "Platform_VMCU1_Sig" SG_ 2515802464 AlarmClockAlarms_stat_Mode_ISig_ 1;
BA_ "SystemSignalLongSymbol" SG_ 2515802464 AlarmClockAlarms_stat_Mode_ISig_ "AlarmClockAlarms_stat_Mode_ISig_4";
BA_ "GenSigCycleTime" SG_ 2515802464 AlarmClockAlarms_stat_Type_ISig_ 100;
BA_ "GenSigCycleTimeActive" SG_ 2515802464 AlarmClockAlarms_stat_Type_ISig_ 100;
BA_ "GenSigStartValue" SG_ 2515802464 AlarmClockAlarms_stat_Type_ISig_ 7;
BA_ "GenSigMaxLatency" SG_ 2515802464 AlarmClockAlarms_stat_Type_ISig_ 169;
BA_ "Platform_VMCU1_Sig" SG_ 2515802464 AlarmClockAlarms_stat_Type_ISig_ 1;
BA_ "SystemSignalLongSymbol" SG_ 2515802464 AlarmClockAlarms_stat_Type_ISig_ "AlarmClockAlarms_stat_Type_ISig_4";
BA_ "GenSigCycleTime" SG_ 2515802464 AlarmClockAlarms_stat_DaySet_ISi 100;
BA_ "GenSigCycleTimeActive" SG_ 2515802464 AlarmClockAlarms_stat_DaySet_ISi 100;
BA_ "GenSigMaxLatency" SG_ 2515802464 AlarmClockAlarms_stat_DaySet_ISi 169;
BA_ "Platform_VMCU1_Sig" SG_ 2515802464 AlarmClockAlarms_stat_DaySet_ISi 1;
BA_ "SystemSignalLongSymbol" SG_ 2515802464 AlarmClockAlarms_stat_DaySet_ISi "AlarmClockAlarms_stat_DaySet_ISig_4";
BA_ "GenSigCycleTime" SG_ 2515802464 AlarmClockAlarms_stat_ID_ISig_4 100;
BA_ "GenSigCycleTimeActive" SG_ 2515802464 AlarmClockAlarms_stat_ID_ISig_4 100;
BA_ "GenSigStartValue" SG_ 2515802464 AlarmClockAlarms_stat_ID_ISig_4 127;
BA_ "GenSigMaxLatency" SG_ 2515802464 AlarmClockAlarms_stat_ID_ISig_4 169;
BA_ "Platform_VMCU1_Sig" SG_ 2515802464 AlarmClockAlarms_stat_ID_ISig_4 1;
BA_ "GenSigCycleTime" SG_ 2515802464 AlmClkCurAlarm_stat_SetMin 100;
BA_ "GenSigCycleTimeActive" SG_ 2515802464 AlmClkCurAlarm_stat_SetMin 100;
BA_ "GenSigStartValue" SG_ 2515802464 AlmClkCurAlarm_stat_SetMin 63;
BA_ "GenSigMaxLatency" SG_ 2515802464 AlmClkCurAlarm_stat_SetMin 169;
BA_ "Platform_VMCU1_Sig" SG_ 2515802464 AlmClkCurAlarm_stat_SetMin 1;
BA_ "GenSigCycleTime" SG_ 2515802464 AlarmClockAlarms_stat_Stat_ISig_ 100;
BA_ "GenSigCycleTimeActive" SG_ 2515802464 AlarmClockAlarms_stat_Stat_ISig_ 100;
BA_ "GenSigMaxLatency" SG_ 2515802464 AlarmClockAlarms_stat_Stat_ISig_ 169;
BA_ "Platform_VMCU1_Sig" SG_ 2515802464 AlarmClockAlarms_stat_Stat_ISig_ 1;
BA_ "SystemSignalLongSymbol" SG_ 2515802464 AlarmClockAlarms_stat_Stat_ISig_ "AlarmClockAlarms_stat_Stat_ISig_4";
BA_ "GenSigCycleTime" SG_ 2515802464 AlmClkCurAlarm_stat_Stat 100;
BA_ "GenSigCycleTimeActive" SG_ 2515802464 AlmClkCurAlarm_stat_Stat 100;
BA_ "GenSigMaxLatency" SG_ 2515802464 AlmClkCurAlarm_stat_Stat 169;
BA_ "Platform_VMCU1_Sig" SG_ 2515802464 AlmClkCurAlarm_stat_Stat 1;
BA_ "GenSigCycleTime" SG_ 2515802464 AlmClkCurAlarm_stat_ID 100;
BA_ "GenSigCycleTimeActive" SG_ 2515802464 AlmClkCurAlarm_stat_ID 100;
BA_ "GenSigStartValue" SG_ 2515802464 AlmClkCurAlarm_stat_ID 127;
BA_ "GenSigMaxLatency" SG_ 2515802464 AlmClkCurAlarm_stat_ID 169;
BA_ "Platform_VMCU1_Sig" SG_ 2515802464 AlmClkCurAlarm_stat_ID 1;
BA_ "GenSigCycleTime" SG_ 2515802464 AlarmClockAlarms_stat_SetMin_ISi 100;
BA_ "GenSigCycleTimeActive" SG_ 2515802464 AlarmClockAlarms_stat_SetMin_ISi 100;
BA_ "GenSigStartValue" SG_ 2515802464 AlarmClockAlarms_stat_SetMin_ISi 63;
BA_ "GenSigMaxLatency" SG_ 2515802464 AlarmClockAlarms_stat_SetMin_ISi 169;
BA_ "Platform_VMCU1_Sig" SG_ 2515802464 AlarmClockAlarms_stat_SetMin_ISi 1;
BA_ "SystemSignalLongSymbol" SG_ 2515802464 AlarmClockAlarms_stat_SetMin_ISi "AlarmClockAlarms_stat_SetMin_ISig_4";
BA_ "GenSigCycleTime" SG_ 2515802464 AlmClkCurAlarm_stat_Type 100;
BA_ "GenSigCycleTimeActive" SG_ 2515802464 AlmClkCurAlarm_stat_Type 100;
BA_ "GenSigStartValue" SG_ 2515802464 AlmClkCurAlarm_stat_Type 7;
BA_ "GenSigMaxLatency" SG_ 2515802464 AlmClkCurAlarm_stat_Type 169;
BA_ "Platform_VMCU1_Sig" SG_ 2515802464 AlmClkCurAlarm_stat_Type 1;
BA_ "GenSigCycleTime" SG_ 2515802464 AlarmClockAlarms_stat_SetHr_ISig 100;
BA_ "GenSigCycleTimeActive" SG_ 2515802464 AlarmClockAlarms_stat_SetHr_ISig 100;
BA_ "GenSigStartValue" SG_ 2515802464 AlarmClockAlarms_stat_SetHr_ISig 31;
BA_ "GenSigMaxLatency" SG_ 2515802464 AlarmClockAlarms_stat_SetHr_ISig 169;
BA_ "Platform_VMCU1_Sig" SG_ 2515802464 AlarmClockAlarms_stat_SetHr_ISig 1;
BA_ "SystemSignalLongSymbol" SG_ 2515802464 AlarmClockAlarms_stat_SetHr_ISig "AlarmClockAlarms_stat_SetHr_ISig_4";
BA_ "GenSigCycleTime" SG_ 2515802464 AlmClkCurAlarm_stat_SetHr 100;
BA_ "GenSigCycleTimeActive" SG_ 2515802464 AlmClkCurAlarm_stat_SetHr 100;
BA_ "GenSigStartValue" SG_ 2515802464 AlmClkCurAlarm_stat_SetHr 31;
BA_ "GenSigMaxLatency" SG_ 2515802464 AlmClkCurAlarm_stat_SetHr 169;
BA_ "Platform_VMCU1_Sig" SG_ 2515802464 AlmClkCurAlarm_stat_SetHr 1;
BA_ "GenSigCycleTime" SG_ 2499801297 PinCodeEntered_value 100;
BA_ "GenSigCycleTimeActive" SG_ 2499801297 PinCodeEntered_value 100;
BA_ "GenSigMaxLatency" SG_ 2499801297 PinCodeEntered_value 89;
BA_ "Platform_VMCU1_Sig" SG_ 2499801297 PinCodeEntered_value 1;
BA_ "GenSigCycleTime" SG_ 2499801297 DriverNewOilQuality 100;
BA_ "GenSigCycleTimeActive" SG_ 2499801297 DriverNewOilQuality 100;
BA_ "GenSigStartValue" SG_ 2499801297 DriverNewOilQuality 7;
BA_ "Platform_VMCU1_Sig" SG_ 2499801297 DriverNewOilQuality 1;
BA_ "GenSigCycleTime" SG_ 2499801297 DynamicCode_rqst 100;
BA_ "GenSigCycleTimeActive" SG_ 2499801297 DynamicCode_rqst 100;
BA_ "GenSigStartValue" SG_ 2499801297 DynamicCode_rqst 7;
BA_ "GenSigMaxLatency" SG_ 2499801297 DynamicCode_rqst 26;
BA_ "Platform_VMCU1_Sig" SG_ 2499801297 DynamicCode_rqst 1;
BA_ "GenSigCycleTime" SG_ 2499801297 FrontWheelDriveMenuRequest 100;
BA_ "GenSigCycleTimeActive" SG_ 2499801297 FrontWheelDriveMenuRequest 100;
BA_ "GenSigStartValue" SG_ 2499801297 FrontWheelDriveMenuRequest 3;
BA_ "Platform_VMCU1_Sig" SG_ 2499801297 FrontWheelDriveMenuRequest 1;
BA_ "GenSigCycleTime" SG_ 2499801297 DriverNewBatteryCapacity 100;
BA_ "GenSigCycleTimeActive" SG_ 2499801297 DriverNewBatteryCapacity 100;
BA_ "GenSigStartValue" SG_ 2499801297 DriverNewBatteryCapacity 15;
BA_ "Platform_VMCU1_Sig" SG_ 2499801297 DriverNewBatteryCapacity 1;
BA_ "GenSigCycleTime" SG_ 2499801297 LogDisplayedMessage_req 100;
BA_ "GenSigCycleTimeActive" SG_ 2499801297 LogDisplayedMessage_req 100;
BA_ "GenSigMaxLatency" SG_ 2499801297 LogDisplayedMessage_req 89;
BA_ "NeedsUpdateBit" SG_ 2499801297 LogDisplayedMessage_req 1;
BA_ "Platform_VMCU1_Sig" SG_ 2499801297 LogDisplayedMessage_req 1;
BA_ "GenSigSendType" SG_ 2499801297 LogDisplayedMessage_req_UB 7;
BA_ "Platform_VMCU1_Sig" SG_ 2499801297 LogDisplayedMessage_req_UB 1;
BA_ "GenSigCycleTime" SG_ 2499794044 FirstAxleLowerPrioRequested_ISig 100;
BA_ "GenSigCycleTimeActive" SG_ 2499794044 FirstAxleLowerPrioRequested_ISig 100;
BA_ "GenSigStartValue" SG_ 2499794044 FirstAxleLowerPrioRequested_ISig 7;
BA_ "GenSigMaxLatency" SG_ 2499794044 FirstAxleLowerPrioRequested_ISig 89;
BA_ "NeedsUpdateBit" SG_ 2499794044 FirstAxleLowerPrioRequested_ISig 1;
BA_ "Platform_VMCU1_Sig" SG_ 2499794044 FirstAxleLowerPrioRequested_ISig 1;
BA_ "SystemSignalLongSymbol" SG_ 2499794044 FirstAxleLowerPrioRequested_ISig "FirstAxleLowerPrioRequested_ISig_4";
BA_ "GenSigCycleTime" SG_ 2499794044 MaintInfo_rqst_ISig_4 100;
BA_ "GenSigCycleTimeActive" SG_ 2499794044 MaintInfo_rqst_ISig_4 100;
BA_ "GenSigStartValue" SG_ 2499794044 MaintInfo_rqst_ISig_4 3;
BA_ "Platform_VMCU1_Sig" SG_ 2499794044 MaintInfo_rqst_ISig_4 1;
BA_ "GenSigCycleTime" SG_ 2499794044 Synch_Unsynch_Mode_stat 100;
BA_ "GenSigCycleTimeActive" SG_ 2499794044 Synch_Unsynch_Mode_stat 100;
BA_ "GenSigStartValue" SG_ 2499794044 Synch_Unsynch_Mode_stat 7;
BA_ "GenSigMaxLatency" SG_ 2499794044 Synch_Unsynch_Mode_stat 89;
BA_ "Platform_VMCU1_Sig" SG_ 2499794044 Synch_Unsynch_Mode_stat 1;
BA_ "GenSigSendType" SG_ 2499794044 FirstAxleLowerPrioRequested_UB_I 7;
BA_ "Platform_VMCU1_Sig" SG_ 2499794044 FirstAxleLowerPrioRequested_UB_I 1;
BA_ "SystemSignalLongSymbol" SG_ 2499794044 FirstAxleLowerPrioRequested_UB_I "FirstAxleLowerPrioRequested_UB_ISig_4";
BA_ "GenSigCycleTime" SG_ 2499794044 MaintResetRqst_ID 100;
BA_ "GenSigCycleTimeActive" SG_ 2499794044 MaintResetRqst_ID 100;
BA_ "GenSigStartValue" SG_ 2499794044 MaintResetRqst_ID 63;
BA_ "GenSigMaxLatency" SG_ 2499794044 MaintResetRqst_ID 89;
BA_ "Platform_VMCU1_Sig" SG_ 2499794044 MaintResetRqst_ID 1;
BA_ "GenSigSendType" SG_ 2499794044 TrailerBrakeInputStatus_UB 7;
BA_ "Platform_VMCU1_Sig" SG_ 2499794044 TrailerBrakeInputStatus_UB 1;
BA_ "GenSigCycleTime" SG_ 2499794044 TrailerBrakeInputStatus 100;
BA_ "GenSigCycleTimeActive" SG_ 2499794044 TrailerBrakeInputStatus 100;
BA_ "GenSigStartValue" SG_ 2499794044 TrailerBrakeInputStatus 7;
BA_ "GenSigMaxLatency" SG_ 2499794044 TrailerBrakeInputStatus 89;
BA_ "NeedsUpdateBit" SG_ 2499794044 TrailerBrakeInputStatus 1;
BA_ "Platform_VMCU1_Sig" SG_ 2499794044 TrailerBrakeInputStatus 1;
BA_ "GenSigCycleTime" SG_ 2499794044 MaintResetRqst_StatusRqst 100;
BA_ "GenSigCycleTimeActive" SG_ 2499794044 MaintResetRqst_StatusRqst 100;
BA_ "GenSigStartValue" SG_ 2499794044 MaintResetRqst_StatusRqst 3;
BA_ "GenSigMaxLatency" SG_ 2499794044 MaintResetRqst_StatusRqst 89;
BA_ "Platform_VMCU1_Sig" SG_ 2499794044 MaintResetRqst_StatusRqst 1;
BA_ "GenSigCycleTime" SG_ 2499794044 SelectedSpeedUnit_stat_ISig_4 100;
BA_ "GenSigCycleTimeActive" SG_ 2499794044 SelectedSpeedUnit_stat_ISig_4 100;
BA_ "GenSigStartValue" SG_ 2499794044 SelectedSpeedUnit_stat_ISig_4 3;
BA_ "GenSigMaxLatency" SG_ 2499794044 SelectedSpeedUnit_stat_ISig_4 89;
BA_ "Platform_VMCU1_Sig" SG_ 2499794044 SelectedSpeedUnit_stat_ISig_4 1;
BA_ "GenSigCycleTime" SG_ 2499794044 SelectedLanguage_stat_ISig_4 100;
BA_ "GenSigCycleTimeActive" SG_ 2499794044 SelectedLanguage_stat_ISig_4 100;
BA_ "GenSigStartValue" SG_ 2499794044 SelectedLanguage_stat_ISig_4 63;
BA_ "GenSigMaxLatency" SG_ 2499794044 SelectedLanguage_stat_ISig_4 89;
BA_ "Platform_VMCU1_Sig" SG_ 2499794044 SelectedLanguage_stat_ISig_4 1;
BA_ "GenSigCycleTime" SG_ 2499794044 LampCheck_rqst_ISig_4 100;
BA_ "GenSigCycleTimeActive" SG_ 2499794044 LampCheck_rqst_ISig_4 100;
BA_ "GenSigStartValue" SG_ 2499794044 LampCheck_rqst_ISig_4 3;
BA_ "Platform_VMCU1_Sig" SG_ 2499794044 LampCheck_rqst_ISig_4 1;
BA_ "GenSigCycleTime" SG_ 2499794044 ParkingHeaterCleaning_cmd_ISig_4 100;
BA_ "GenSigCycleTimeActive" SG_ 2499794044 ParkingHeaterCleaning_cmd_ISig_4 100;
BA_ "GenSigStartValue" SG_ 2499794044 ParkingHeaterCleaning_cmd_ISig_4 3;
BA_ "GenSigMaxLatency" SG_ 2499794044 ParkingHeaterCleaning_cmd_ISig_4 89;
BA_ "Platform_VMCU1_Sig" SG_ 2499794044 ParkingHeaterCleaning_cmd_ISig_4 1;
BA_ "GenSigCycleTime" SG_ 2499794044 SelectedWeightUnit_stat_ISig_4 100;
BA_ "GenSigCycleTimeActive" SG_ 2499794044 SelectedWeightUnit_stat_ISig_4 100;
BA_ "GenSigStartValue" SG_ 2499794044 SelectedWeightUnit_stat_ISig_4 3;
BA_ "Platform_VMCU1_Sig" SG_ 2499794044 SelectedWeightUnit_stat_ISig_4 1;
BA_ "GenSigCycleTime" SG_ 2499794044 SpeedLockingInhibition_stat 100;
BA_ "GenSigCycleTimeActive" SG_ 2499794044 SpeedLockingInhibition_stat 100;
BA_ "GenSigStartValue" SG_ 2499794044 SpeedLockingInhibition_stat 7;
BA_ "GenSigMaxLatency" SG_ 2499794044 SpeedLockingInhibition_stat 89;
BA_ "Platform_VMCU1_Sig" SG_ 2499794044 SpeedLockingInhibition_stat 1;
BA_ "GenSigCycleTime" SG_ 2499794044 MaintInfoRqst 100;
BA_ "GenSigCycleTimeActive" SG_ 2499794044 MaintInfoRqst 100;
BA_ "GenSigStartValue" SG_ 2499794044 MaintInfoRqst 3;
BA_ "Platform_VMCU1_Sig" SG_ 2499794044 MaintInfoRqst 1;
BA_ "GenSigCycleTime" SG_ 2499794044 ParkHeaterTimerReleased_stat_ISi 100;
BA_ "GenSigCycleTimeActive" SG_ 2499794044 ParkHeaterTimerReleased_stat_ISi 100;
BA_ "GenSigStartValue" SG_ 2499794044 ParkHeaterTimerReleased_stat_ISi 3;
BA_ "GenSigMaxLatency" SG_ 2499794044 ParkHeaterTimerReleased_stat_ISi 89;
BA_ "Platform_VMCU1_Sig" SG_ 2499794044 ParkHeaterTimerReleased_stat_ISi 1;
BA_ "SystemSignalLongSymbol" SG_ 2499794044 ParkHeaterTimerReleased_stat_ISi "ParkHeaterTimerReleased_stat_ISig_4";
BA_ "GenSigCycleTime" SG_ 2499794044 DriverMemory_rqst_ISig_4 100;
BA_ "GenSigCycleTimeActive" SG_ 2499794044 DriverMemory_rqst_ISig_4 100;
BA_ "GenSigStartValue" SG_ 2499794044 DriverMemory_rqst_ISig_4 31;
BA_ "Platform_VMCU1_Sig" SG_ 2499794044 DriverMemory_rqst_ISig_4 1;
BA_ "GenSigCycleTime" SG_ 2499794044 SelectedTimeFormat_stat_ISig_4 100;
BA_ "GenSigCycleTimeActive" SG_ 2499794044 SelectedTimeFormat_stat_ISig_4 100;
BA_ "GenSigStartValue" SG_ 2499794044 SelectedTimeFormat_stat_ISig_4 3;
BA_ "Platform_VMCU1_Sig" SG_ 2499794044 SelectedTimeFormat_stat_ISig_4 1;
BA_ "GenSigCycleTime" SG_ 2499794044 RefrigTimerReleased_stat 100;
BA_ "GenSigCycleTimeActive" SG_ 2499794044 RefrigTimerReleased_stat 100;
BA_ "GenSigStartValue" SG_ 2499794044 RefrigTimerReleased_stat 3;
BA_ "Platform_VMCU1_Sig" SG_ 2499794044 RefrigTimerReleased_stat 1;
BA_ "GenSigCycleTime" SG_ 2499794044 LCSSoundSettingRequest 100;
BA_ "GenSigCycleTimeActive" SG_ 2499794044 LCSSoundSettingRequest 100;
BA_ "GenSigStartValue" SG_ 2499794044 LCSSoundSettingRequest 3;
BA_ "Platform_VMCU1_Sig" SG_ 2499794044 LCSSoundSettingRequest 1;
BA_REL_ "GenSigFirstTimeoutTime" BU_SG_REL_ VMCU SG_ 2565494112 TPMSetAxleTireConfig_Axle4_ISig_ 12000;
BA_REL_ "GenSigTimeoutTime" BU_SG_REL_ VMCU SG_ 2565494112 TPMSetAxleTireConfig_Axle4_ISig_ 3000;
BA_REL_ "GenSigFirstTimeoutTime" BU_SG_REL_ VMCU SG_ 2565494112 TPMSetAxleTireConfig_Axle5_ISig_ 12000;
BA_REL_ "GenSigTimeoutTime" BU_SG_REL_ VMCU SG_ 2565494112 TPMSetAxleTireConfig_Axle5_ISig_ 3000;
BA_REL_ "GenSigFirstTimeoutTime" BU_SG_REL_ VMCU SG_ 2565494112 TPMSetPresThresCfg_VehiclePos_IS 12000;
BA_REL_ "GenSigTimeoutTime" BU_SG_REL_ VMCU SG_ 2565494112 TPMSetPresThresCfg_VehiclePos_IS 3000;
BA_REL_ "GenSigFirstTimeoutTime" BU_SG_REL_ VMCU SG_ 2565494112 TPMSetPresThresCfg_ExtOverPres_I 12000;
BA_REL_ "GenSigTimeoutTime" BU_SG_REL_ VMCU SG_ 2565494112 TPMSetPresThresCfg_ExtOverPres_I 3000;
BA_REL_ "GenSigFirstTimeoutTime" BU_SG_REL_ VMCU SG_ 2565494112 TPMSetAxleTireConfig_Axle2_ISig_ 12000;
BA_REL_ "GenSigTimeoutTime" BU_SG_REL_ VMCU SG_ 2565494112 TPMSetAxleTireConfig_Axle2_ISig_ 3000;
BA_REL_ "GenSigFirstTimeoutTime" BU_SG_REL_ VMCU SG_ 2565494112 TPMSetAxleTireConfig_VehiclePos_ 12000;
BA_REL_ "GenSigTimeoutTime" BU_SG_REL_ VMCU SG_ 2565494112 TPMSetAxleTireConfig_VehiclePos_ 3000;
BA_REL_ "GenSigFirstTimeoutTime" BU_SG_REL_ VMCU SG_ 2565494112 TPMSetAxleTireConfig_Axle3_ISig_ 12000;
BA_REL_ "GenSigTimeoutTime" BU_SG_REL_ VMCU SG_ 2565494112 TPMSetAxleTireConfig_Axle3_ISig_ 3000;
BA_REL_ "GenSigFirstTimeoutTime" BU_SG_REL_ VMCU SG_ 2565494112 TPMSetAxleTireConfig_Axle1_ISig_ 12000;
BA_REL_ "GenSigTimeoutTime" BU_SG_REL_ VMCU SG_ 2565494112 TPMSetAxleTireConfig_Axle1_ISig_ 3000;
BA_REL_ "GenSigFirstTimeoutTime" BU_SG_REL_ VMCU SG_ 2565494112 TPMSetPresThresCfg_AxleNr_ISig_4 12000;
BA_REL_ "GenSigTimeoutTime" BU_SG_REL_ VMCU SG_ 2565494112 TPMSetPresThresCfg_AxleNr_ISig_4 3000;
BA_REL_ "GenSigFirstTimeoutTime" BU_SG_REL_ VMCU SG_ 2565494112 TPMSetPresThresCfg_OverPres_ISig 12000;
BA_REL_ "GenSigTimeoutTime" BU_SG_REL_ VMCU SG_ 2565494112 TPMSetPresThresCfg_OverPres_ISig 3000;
BA_REL_ "GenSigFirstTimeoutTime" BU_SG_REL_ VMCU SG_ 2565494112 TPMSetPresThresCfg_ExtUnderPres_ 12000;
BA_REL_ "GenSigTimeoutTime" BU_SG_REL_ VMCU SG_ 2565494112 TPMSetPresThresCfg_ExtUnderPres_ 3000;
BA_REL_ "GenSigFirstTimeoutTime" BU_SG_REL_ VMCU SG_ 2565494112 TPMSetPresThresCfg_UnderPres_ISi 12000;
BA_REL_ "GenSigTimeoutTime" BU_SG_REL_ VMCU SG_ 2565494112 TPMSetPresThresCfg_UnderPres_ISi 3000;
BA_REL_ "GenSigFirstTimeoutTime" BU_SG_REL_ CIOM SG_ 2515671136 Trailer3LiftAxles_LiftAxle1Id_IS 2400;
BA_REL_ "GenSigTimeoutTime" BU_SG_REL_ CIOM SG_ 2515671136 Trailer3LiftAxles_LiftAxle1Id_IS 600;
BA_REL_ "GenSigFirstTimeoutTime" BU_SG_REL_ CIOM SG_ 2515671136 Trailer2LiftAxles_LiftAxle1Pos_I 2400;
BA_REL_ "GenSigTimeoutTime" BU_SG_REL_ CIOM SG_ 2515671136 Trailer2LiftAxles_LiftAxle1Pos_I 600;
BA_REL_ "GenSigFirstTimeoutTime" BU_SG_REL_ CIOM SG_ 2515671136 Trailer1LiftAxles_LiftAxle2Pos_I 2400;
BA_REL_ "GenSigTimeoutTime" BU_SG_REL_ CIOM SG_ 2515671136 Trailer1LiftAxles_LiftAxle2Pos_I 600;
BA_REL_ "GenSigFirstTimeoutTime" BU_SG_REL_ CIOM SG_ 2515671136 Trailer3LiftAxles_LiftAxle2Pos_I 2400;
BA_REL_ "GenSigTimeoutTime" BU_SG_REL_ CIOM SG_ 2515671136 Trailer3LiftAxles_LiftAxle2Pos_I 600;
BA_REL_ "GenSigFirstTimeoutTime" BU_SG_REL_ CIOM SG_ 2515671136 Trailer1LiftAxles_LiftAxle2Id_IS 2400;
BA_REL_ "GenSigTimeoutTime" BU_SG_REL_ CIOM SG_ 2515671136 Trailer1LiftAxles_LiftAxle2Id_IS 600;
BA_REL_ "GenSigFirstTimeoutTime" BU_SG_REL_ CIOM SG_ 2515671136 Trailer5LiftAxles_LiftAxle1Id_IS 2400;
BA_REL_ "GenSigTimeoutTime" BU_SG_REL_ CIOM SG_ 2515671136 Trailer5LiftAxles_LiftAxle1Id_IS 600;
BA_REL_ "GenSigFirstTimeoutTime" BU_SG_REL_ CIOM SG_ 2515671136 Trailer1LiftAxles_LiftAxle1Pos_I 2400;
BA_REL_ "GenSigTimeoutTime" BU_SG_REL_ CIOM SG_ 2515671136 Trailer1LiftAxles_LiftAxle1Pos_I 600;
BA_REL_ "GenSigFirstTimeoutTime" BU_SG_REL_ CIOM SG_ 2515671136 Trailer1LiftAxles_LiftAxle1Id_IS 2400;
BA_REL_ "GenSigTimeoutTime" BU_SG_REL_ CIOM SG_ 2515671136 Trailer1LiftAxles_LiftAxle1Id_IS 600;
BA_REL_ "GenSigFirstTimeoutTime" BU_SG_REL_ CIOM SG_ 2515671136 Trailer4LiftAxles_LiftAxle2Pos_I 2400;
BA_REL_ "GenSigTimeoutTime" BU_SG_REL_ CIOM SG_ 2515671136 Trailer4LiftAxles_LiftAxle2Pos_I 600;
BA_REL_ "GenSigFirstTimeoutTime" BU_SG_REL_ CIOM SG_ 2515671136 Trailer5LiftAxles_LiftAxle2Pos_I 2400;
BA_REL_ "GenSigTimeoutTime" BU_SG_REL_ CIOM SG_ 2515671136 Trailer5LiftAxles_LiftAxle2Pos_I 600;
BA_REL_ "GenSigFirstTimeoutTime" BU_SG_REL_ CIOM SG_ 2515671136 Trailer4LiftAxles_LiftAxle1Pos_I 2400;
BA_REL_ "GenSigTimeoutTime" BU_SG_REL_ CIOM SG_ 2515671136 Trailer4LiftAxles_LiftAxle1Pos_I 600;
BA_REL_ "GenSigFirstTimeoutTime" BU_SG_REL_ CIOM SG_ 2515671136 Trailer2LiftAxles_LiftAxle1Id_IS 2400;
BA_REL_ "GenSigTimeoutTime" BU_SG_REL_ CIOM SG_ 2515671136 Trailer2LiftAxles_LiftAxle1Id_IS 600;
BA_REL_ "GenSigFirstTimeoutTime" BU_SG_REL_ CIOM SG_ 2515671136 Trailer5LiftAxles_LiftAxle1Pos_I 2400;
BA_REL_ "GenSigTimeoutTime" BU_SG_REL_ CIOM SG_ 2515671136 Trailer5LiftAxles_LiftAxle1Pos_I 600;
BA_REL_ "GenSigFirstTimeoutTime" BU_SG_REL_ CIOM SG_ 2515671136 Trailer2LiftAxles_LiftAxle2Pos_I 2400;
BA_REL_ "GenSigTimeoutTime" BU_SG_REL_ CIOM SG_ 2515671136 Trailer2LiftAxles_LiftAxle2Pos_I 600;
BA_REL_ "GenSigFirstTimeoutTime" BU_SG_REL_ CIOM SG_ 2515671136 Trailer2LiftAxles_LiftAxle2Id_IS 2400;
BA_REL_ "GenSigTimeoutTime" BU_SG_REL_ CIOM SG_ 2515671136 Trailer2LiftAxles_LiftAxle2Id_IS 600;
BA_REL_ "GenSigFirstTimeoutTime" BU_SG_REL_ CIOM SG_ 2515671136 Trailer3LiftAxles_LiftAxle1Pos_I 2400;
BA_REL_ "GenSigTimeoutTime" BU_SG_REL_ CIOM SG_ 2515671136 Trailer3LiftAxles_LiftAxle1Pos_I 600;
BA_REL_ "GenSigFirstTimeoutTime" BU_SG_REL_ CIOM SG_ 2515671136 Trailer5LiftAxles_LiftAxle2Id_IS 2400;
BA_REL_ "GenSigTimeoutTime" BU_SG_REL_ CIOM SG_ 2515671136 Trailer5LiftAxles_LiftAxle2Id_IS 600;
BA_REL_ "GenSigFirstTimeoutTime" BU_SG_REL_ CIOM SG_ 2515671136 InhibRegeneration_DeviceInd 3000;
BA_REL_ "GenSigTimeoutTime" BU_SG_REL_ CIOM SG_ 2515671136 InhibRegeneration_DeviceInd 600;
BA_REL_ "GenSigFirstTimeoutTime" BU_SG_REL_ CIOM SG_ 2515671136 Trailer4LiftAxles_LiftAxle1Id_IS 2400;
BA_REL_ "GenSigTimeoutTime" BU_SG_REL_ CIOM SG_ 2515671136 Trailer4LiftAxles_LiftAxle1Id_IS 600;
BA_REL_ "GenSigFirstTimeoutTime" BU_SG_REL_ CIOM SG_ 2515671136 Trailer3LiftAxles_LiftAxle2Id_IS 2400;
BA_REL_ "GenSigTimeoutTime" BU_SG_REL_ CIOM SG_ 2515671136 Trailer3LiftAxles_LiftAxle2Id_IS 600;
BA_REL_ "GenSigFirstTimeoutTime" BU_SG_REL_ CIOM SG_ 2515671136 Trailer4LiftAxles_LiftAxle2Id_IS 2400;
BA_REL_ "GenSigTimeoutTime" BU_SG_REL_ CIOM SG_ 2515671136 Trailer4LiftAxles_LiftAxle2Id_IS 600;
BA_REL_ "GenSigFirstTimeoutTime" BU_SG_REL_ VMCU SG_ 2482917472 RefrigTimerRqstAck_CurrentOp 3000;
BA_REL_ "GenSigTimeoutTime" BU_SG_REL_ VMCU SG_ 2482917472 RefrigTimerRqstAck_CurrentOp 300;
BA_REL_ "GenSigFirstTimeoutTime" BU_SG_REL_ VMCU SG_ 2482917472 RefrigTimerRqstAck_DayOfWeekRq 3000;
BA_REL_ "GenSigTimeoutTime" BU_SG_REL_ VMCU SG_ 2482917472 RefrigTimerRqstAck_DayOfWeekRq 300;
BA_REL_ "GenSigFirstTimeoutTime" BU_SG_REL_ CIOM SG_ 2482917472 PHTimerRqstAck_Minutes_ISig_4 3000;
BA_REL_ "GenSigTimeoutTime" BU_SG_REL_ CIOM SG_ 2482917472 PHTimerRqstAck_Minutes_ISig_4 300;
BA_REL_ "GenSigFirstTimeoutTime" BU_SG_REL_ CIOM SG_ 2482917472 RemoteParkingClimateRqst_ISig_4 3000;
BA_REL_ "GenSigTimeoutTime" BU_SG_REL_ CIOM SG_ 2482917472 RemoteParkingClimateRqst_ISig_4 600;
BA_REL_ "GenSigFirstTimeoutTime" BU_SG_REL_ CIOM SG_ 2482917472 PHTimerRqstAck_Hours_ISig_4 3000;
BA_REL_ "GenSigTimeoutTime" BU_SG_REL_ CIOM SG_ 2482917472 PHTimerRqstAck_Hours_ISig_4 300;
BA_REL_ "GenSigFirstTimeoutTime" BU_SG_REL_ CIOM SG_ 2482917472 RegenerationIndication 3000;
BA_REL_ "GenSigTimeoutTime" BU_SG_REL_ CIOM SG_ 2482917472 RegenerationIndication 300;
BA_REL_ "GenSigFirstTimeoutTime" BU_SG_REL_ VMCU SG_ 2482917472 RefrigTimerRqstAck_Hours 3000;
BA_REL_ "GenSigTimeoutTime" BU_SG_REL_ VMCU SG_ 2482917472 RefrigTimerRqstAck_Hours 300;
BA_REL_ "GenSigFirstTimeoutTime" BU_SG_REL_ VMCU SG_ 2482917472 RefrigTimerRqstAck_Minutes 3000;
BA_REL_ "GenSigTimeoutTime" BU_SG_REL_ VMCU SG_ 2482917472 RefrigTimerRqstAck_Minutes 300;
BA_REL_ "GenSigFirstTimeoutTime" BU_SG_REL_ VMCU SG_ 2482917472 TPMIndicationLightReq 3000;
BA_REL_ "GenSigTimeoutTime" BU_SG_REL_ VMCU SG_ 2482917472 TPMIndicationLightReq 500;
BA_REL_ "GenSigFirstTimeoutTime" BU_SG_REL_ CIOM SG_ 2482917472 PHTimerRqstAck_DayOfWeekRq_ISig_ 3000;
BA_REL_ "GenSigTimeoutTime" BU_SG_REL_ CIOM SG_ 2482917472 PHTimerRqstAck_DayOfWeekRq_ISig_ 300;
BA_REL_ "GenSigFirstTimeoutTime" BU_SG_REL_ CIOM SG_ 2482917472 PHTimerRqstAck_CurrentOp_ISig_4 3000;
BA_REL_ "GenSigTimeoutTime" BU_SG_REL_ CIOM SG_ 2482917472 PHTimerRqstAck_CurrentOp_ISig_4 300;
BA_REL_ "GenSigFirstTimeoutTime" BU_SG_REL_ CIOM SG_ 2482917472 Regeneration_DeviceInd 3000;
BA_REL_ "GenSigTimeoutTime" BU_SG_REL_ CIOM SG_ 2482917472 Regeneration_DeviceInd 600;
BA_REL_ "GenSigFirstTimeoutTime" BU_SG_REL_ CIOM SG_ 2515822432 AlarmClockNotification_ID_ISig_4 3600;
BA_REL_ "GenSigTimeoutTime" BU_SG_REL_ CIOM SG_ 2515822432 AlarmClockNotification_ID_ISig_4 900;
BA_REL_ "GenSigFirstTimeoutTime" BU_SG_REL_ CIOM SG_ 2515822432 AlarmClockNotification_Type_ISig 3600;
BA_REL_ "GenSigTimeoutTime" BU_SG_REL_ CIOM SG_ 2515822432 AlarmClockNotification_Type_ISig 900;
BA_REL_ "GenSigFirstTimeoutTime" BU_SG_REL_ CIOM SG_ 2515822432 ExtraHeating_rqst_ISig_4 3000;
BA_REL_ "GenSigTimeoutTime" BU_SG_REL_ CIOM SG_ 2515822432 ExtraHeating_rqst_ISig_4 900;
BA_REL_ "GenSigFirstTimeoutTime" BU_SG_REL_ CIOM SG_ 2515822432 AlarmClockNotification_Stat_ISig 3600;
BA_REL_ "GenSigTimeoutTime" BU_SG_REL_ CIOM SG_ 2515822432 AlarmClockNotification_Stat_ISig 900;
BA_REL_ "GenSigFirstTimeoutTime" BU_SG_REL_ TECU SG_ 2515822432 HillDataCtrlTGW_State_ISig_4 12000;
BA_REL_ "GenSigTimeoutTime" BU_SG_REL_ TECU SG_ 2515822432 HillDataCtrlTGW_State_ISig_4 900;
BA_REL_ "GenSigFirstTimeoutTime" BU_SG_REL_ TECU SG_ 2515822432 HillDataCtrlTGW_AckCnt_ISig_4 12000;
BA_REL_ "GenSigTimeoutTime" BU_SG_REL_ TECU SG_ 2515822432 HillDataCtrlTGW_AckCnt_ISig_4 900;
BA_REL_ "GenSigFirstTimeoutTime" BU_SG_REL_ CIOM SG_ 2565490016 BacklightLevelHighRes2_ISig_4 12000;
BA_REL_ "GenSigTimeoutTime" BU_SG_REL_ CIOM SG_ 2565490016 BacklightLevelHighRes2_ISig_4 3000;
BA_REL_ "GenSigFirstTimeoutTime" BU_SG_REL_ BBM SG_ 2565490016 BacklightLevelHighRes2_ISig_4 12000;
BA_REL_ "GenSigTimeoutTime" BU_SG_REL_ BBM SG_ 2565490016 BacklightLevelHighRes2_ISig_4 3000;
BA_REL_ "GenSigFirstTimeoutTime" BU_SG_REL_ VMCU SG_ 2565490016 BacklightLevelHighRes2_ISig_4 12000;
BA_REL_ "GenSigTimeoutTime" BU_SG_REL_ VMCU SG_ 2565490016 BacklightLevelHighRes2_ISig_4 3000;
BA_REL_ "GenSigFirstTimeoutTime" BU_SG_REL_ EMS SG_ 2565490016 DPF_AshLevelRequest 12000;
BA_REL_ "GenSigTimeoutTime" BU_SG_REL_ EMS SG_ 2565490016 DPF_AshLevelRequest 3000;
BA_REL_ "GenSigFirstTimeoutTime" BU_SG_REL_ EMS SG_ 2565490016 DPF_RegenerationConditionsReq 12000;
BA_REL_ "GenSigTimeoutTime" BU_SG_REL_ EMS SG_ 2565490016 DPF_RegenerationConditionsReq 3000;
BA_REL_ "GenSigFirstTimeoutTime" BU_SG_REL_ EMS SG_ 2565490016 SCR_SulphurRegenRqst 12000;
BA_REL_ "GenSigTimeoutTime" BU_SG_REL_ EMS SG_ 2565490016 SCR_SulphurRegenRqst 3000;
BA_REL_ "GenSigFirstTimeoutTime" BU_SG_REL_ EMS SG_ 2565490016 DPF_ManualRegenerateInhibit 12000;
BA_REL_ "GenSigTimeoutTime" BU_SG_REL_ EMS SG_ 2565490016 DPF_ManualRegenerateInhibit 3000;
BA_REL_ "GenSigFirstTimeoutTime" BU_SG_REL_ EMS SG_ 2565490016 DPF_SootLevelRequest 12000;
BA_REL_ "GenSigTimeoutTime" BU_SG_REL_ EMS SG_ 2565490016 DPF_SootLevelRequest 3000;
BA_REL_ "GenSigFirstTimeoutTime" BU_SG_REL_ EMS SG_ 2565490016 DPF_ManualRegenerateRequest_ISig 12000;
BA_REL_ "GenSigTimeoutTime" BU_SG_REL_ EMS SG_ 2565490016 DPF_ManualRegenerateRequest_ISig 3000;
BA_REL_ "GenSigFirstTimeoutTime" BU_SG_REL_ VMCU SG_ 2566268256 GPSData_Longitude_ISig_4_18f6256 12000;
BA_REL_ "GenSigTimeoutTime" BU_SG_REL_ VMCU SG_ 2566268256 GPSData_Longitude_ISig_4_18f6256 3000;
BA_REL_ "GenSigFirstTimeoutTime" BU_SG_REL_ VMCU SG_ 2566268256 GPSData_Direction_ISig_4_18f6256 12000;
BA_REL_ "GenSigTimeoutTime" BU_SG_REL_ VMCU SG_ 2566268256 GPSData_Direction_ISig_4_18f6256 3000;
BA_REL_ "GenSigFirstTimeoutTime" BU_SG_REL_ VMCU SG_ 2566268256 GPSData_Latitude_ISig_4_18f62560 12000;
BA_REL_ "GenSigTimeoutTime" BU_SG_REL_ VMCU SG_ 2566268256 GPSData_Latitude_ISig_4_18f62560 3000;
BA_REL_ "GenSigFirstTimeoutTime" BU_SG_REL_ VMCU SG_ 2566268256 GPSData_Altitude_ISig_4_18f62560 12000;
BA_REL_ "GenSigTimeoutTime" BU_SG_REL_ VMCU SG_ 2566268256 GPSData_Altitude_ISig_4_18f62560 3000;
BA_REL_ "GenSigFirstTimeoutTime" BU_SG_REL_ VMCU SG_ 2566268256 GPSData_HDOP_ISig_4_18f62560 12000;
BA_REL_ "GenSigTimeoutTime" BU_SG_REL_ VMCU SG_ 2566268256 GPSData_HDOP_ISig_4_18f62560 3000;
BA_REL_ "GenSigFirstTimeoutTime" BU_SG_REL_ VMCU SG_ 2566268256 GPSData_Time_ISig_4_18f62560 12000;
BA_REL_ "GenSigTimeoutTime" BU_SG_REL_ VMCU SG_ 2566268256 GPSData_Time_ISig_4_18f62560 3000;
BA_REL_ "GenSigFirstTimeoutTime" BU_SG_REL_ VMCU SG_ 2566268256 GPSData_VehSpeed_ISig_4_18f62560 12000;
BA_REL_ "GenSigTimeoutTime" BU_SG_REL_ VMCU SG_ 2566268256 GPSData_VehSpeed_ISig_4_18f62560 3000;
BA_REL_ "GenSigFirstTimeoutTime" BU_SG_REL_ VMCU SG_ 2566268256 GPSData_AntennaStat_ISig_4_18f62 12000;
BA_REL_ "GenSigTimeoutTime" BU_SG_REL_ VMCU SG_ 2566268256 GPSData_AntennaStat_ISig_4_18f62 3000;
BA_REL_ "GenSigFirstTimeoutTime" BU_SG_REL_ TECU SG_ 2566268000 GPSData_HDOP_ISig_4_18f62460 12000;
BA_REL_ "GenSigTimeoutTime" BU_SG_REL_ TECU SG_ 2566268000 GPSData_HDOP_ISig_4_18f62460 3000;
BA_REL_ "GenSigFirstTimeoutTime" BU_SG_REL_ TECU SG_ 2566268000 GPSData_VehSpeed_ISig_4_18f62460 12000;
BA_REL_ "GenSigTimeoutTime" BU_SG_REL_ TECU SG_ 2566268000 GPSData_VehSpeed_ISig_4_18f62460 3000;
BA_REL_ "GenSigFirstTimeoutTime" BU_SG_REL_ TECU SG_ 2566268000 GPSData_Direction_ISig_4_18f6246 12000;
BA_REL_ "GenSigTimeoutTime" BU_SG_REL_ TECU SG_ 2566268000 GPSData_Direction_ISig_4_18f6246 3000;
BA_REL_ "GenSigFirstTimeoutTime" BU_SG_REL_ TECU SG_ 2566268000 GPSData_Longitude_ISig_4_18f6246 12000;
BA_REL_ "GenSigTimeoutTime" BU_SG_REL_ TECU SG_ 2566268000 GPSData_Longitude_ISig_4_18f6246 3000;
BA_REL_ "GenSigFirstTimeoutTime" BU_SG_REL_ TECU SG_ 2566268000 GPSData_Time_ISig_4_18f62460 12000;
BA_REL_ "GenSigTimeoutTime" BU_SG_REL_ TECU SG_ 2566268000 GPSData_Time_ISig_4_18f62460 3000;
BA_REL_ "GenSigFirstTimeoutTime" BU_SG_REL_ TECU SG_ 2566268000 GPSData_Latitude_ISig_4_18f62460 12000;
BA_REL_ "GenSigTimeoutTime" BU_SG_REL_ TECU SG_ 2566268000 GPSData_Latitude_ISig_4_18f62460 3000;
BA_REL_ "GenSigFirstTimeoutTime" BU_SG_REL_ TECU SG_ 2566268000 GPSData_AntennaStat_ISig_4__0000 12000;
BA_REL_ "GenSigTimeoutTime" BU_SG_REL_ TECU SG_ 2566268000 GPSData_AntennaStat_ISig_4__0000 3000;
BA_REL_ "GenSigFirstTimeoutTime" BU_SG_REL_ TECU SG_ 2566268000 GPSData_Altitude_ISig_4_18f62460 12000;
BA_REL_ "GenSigTimeoutTime" BU_SG_REL_ TECU SG_ 2566268000 GPSData_Altitude_ISig_4_18f62460 3000;
BA_REL_ "GenSigFirstTimeoutTime" BU_SG_REL_ DACU SG_ 2566268512 GPSData_HDOP_ISig_4_18f62660 12000;
BA_REL_ "GenSigTimeoutTime" BU_SG_REL_ DACU SG_ 2566268512 GPSData_HDOP_ISig_4_18f62660 3000;
BA_REL_ "GenSigFirstTimeoutTime" BU_SG_REL_ DACU SG_ 2566268512 GPSData_VehSpeed_ISig_4_18f62660 12000;
BA_REL_ "GenSigTimeoutTime" BU_SG_REL_ DACU SG_ 2566268512 GPSData_VehSpeed_ISig_4_18f62660 3000;
BA_REL_ "GenSigFirstTimeoutTime" BU_SG_REL_ DACU SG_ 2566268512 GPSData_AntennaStat_ISig_4__0001 12000;
BA_REL_ "GenSigTimeoutTime" BU_SG_REL_ DACU SG_ 2566268512 GPSData_AntennaStat_ISig_4__0001 3000;
BA_REL_ "GenSigFirstTimeoutTime" BU_SG_REL_ DACU SG_ 2566268512 GPSData_Latitude_ISig_4_18f62660 12000;
BA_REL_ "GenSigTimeoutTime" BU_SG_REL_ DACU SG_ 2566268512 GPSData_Latitude_ISig_4_18f62660 3000;
BA_REL_ "GenSigFirstTimeoutTime" BU_SG_REL_ DACU SG_ 2566268512 GPSData_Time_ISig_4_18f62660 12000;
BA_REL_ "GenSigTimeoutTime" BU_SG_REL_ DACU SG_ 2566268512 GPSData_Time_ISig_4_18f62660 3000;
BA_REL_ "GenSigFirstTimeoutTime" BU_SG_REL_ DACU SG_ 2566268512 GPSData_Direction_ISig_4_18f6266 12000;
BA_REL_ "GenSigTimeoutTime" BU_SG_REL_ DACU SG_ 2566268512 GPSData_Direction_ISig_4_18f6266 3000;
BA_REL_ "GenSigFirstTimeoutTime" BU_SG_REL_ DACU SG_ 2566268512 GPSData_Longitude_ISig_4_18f6266 12000;
BA_REL_ "GenSigTimeoutTime" BU_SG_REL_ DACU SG_ 2566268512 GPSData_Longitude_ISig_4_18f6266 3000;
BA_REL_ "GenSigFirstTimeoutTime" BU_SG_REL_ DACU SG_ 2566268512 GPSData_Altitude_ISig_4_18f62660 12000;
BA_REL_ "GenSigTimeoutTime" BU_SG_REL_ DACU SG_ 2566268512 GPSData_Altitude_ISig_4_18f62660 3000;
BA_REL_ "GenSigFirstTimeoutTime" BU_SG_REL_ CIOM SG_ 2566269024 GPSData_HDOP_ISig_4_18f62860 12000;
BA_REL_ "GenSigTimeoutTime" BU_SG_REL_ CIOM SG_ 2566269024 GPSData_HDOP_ISig_4_18f62860 3000;
BA_REL_ "GenSigFirstTimeoutTime" BU_SG_REL_ CIOM SG_ 2566269024 GPSData_Latitude_ISig_4_18f62860 12000;
BA_REL_ "GenSigTimeoutTime" BU_SG_REL_ CIOM SG_ 2566269024 GPSData_Latitude_ISig_4_18f62860 3000;
BA_REL_ "GenSigFirstTimeoutTime" BU_SG_REL_ CIOM SG_ 2566269024 GPSData_Time_ISig_4_18f62860 12000;
BA_REL_ "GenSigTimeoutTime" BU_SG_REL_ CIOM SG_ 2566269024 GPSData_Time_ISig_4_18f62860 3000;
BA_REL_ "GenSigFirstTimeoutTime" BU_SG_REL_ CIOM SG_ 2566269024 GPSData_Direction_ISig_4_18f6286 12000;
BA_REL_ "GenSigTimeoutTime" BU_SG_REL_ CIOM SG_ 2566269024 GPSData_Direction_ISig_4_18f6286 3000;
BA_REL_ "GenSigFirstTimeoutTime" BU_SG_REL_ CIOM SG_ 2566269024 GPSData_AntennaStat_ISig_4__0002 12000;
BA_REL_ "GenSigTimeoutTime" BU_SG_REL_ CIOM SG_ 2566269024 GPSData_AntennaStat_ISig_4__0002 3000;
BA_REL_ "GenSigFirstTimeoutTime" BU_SG_REL_ CIOM SG_ 2566269024 GPSData_Longitude_ISig_4_18f6286 12000;
BA_REL_ "GenSigTimeoutTime" BU_SG_REL_ CIOM SG_ 2566269024 GPSData_Longitude_ISig_4_18f6286 3000;
BA_REL_ "GenSigFirstTimeoutTime" BU_SG_REL_ CIOM SG_ 2566269024 GPSData_VehSpeed_ISig_4_18f62860 12000;
BA_REL_ "GenSigTimeoutTime" BU_SG_REL_ CIOM SG_ 2566269024 GPSData_VehSpeed_ISig_4_18f62860 3000;
BA_REL_ "GenSigFirstTimeoutTime" BU_SG_REL_ CIOM SG_ 2566269024 GPSData_Altitude_ISig_4_18f62860 12000;
BA_REL_ "GenSigTimeoutTime" BU_SG_REL_ CIOM SG_ 2566269024 GPSData_Altitude_ISig_4_18f62860 3000;
BA_REL_ "GenSigFirstTimeoutTime" BU_SG_REL_ BBM SG_ 2566268768 GPSData_Time_ISig_4_18f62760 12000;
BA_REL_ "GenSigTimeoutTime" BU_SG_REL_ BBM SG_ 2566268768 GPSData_Time_ISig_4_18f62760 3000;
BA_REL_ "GenSigFirstTimeoutTime" BU_SG_REL_ BBM SG_ 2566268768 GPSData_HDOP_ISig_4_18f62760 12000;
BA_REL_ "GenSigTimeoutTime" BU_SG_REL_ BBM SG_ 2566268768 GPSData_HDOP_ISig_4_18f62760 3000;
BA_REL_ "GenSigFirstTimeoutTime" BU_SG_REL_ BBM SG_ 2566268768 GPSData_Direction_ISig_4_18f6276 12000;
BA_REL_ "GenSigTimeoutTime" BU_SG_REL_ BBM SG_ 2566268768 GPSData_Direction_ISig_4_18f6276 3000;
BA_REL_ "GenSigFirstTimeoutTime" BU_SG_REL_ BBM SG_ 2566268768 GPSData_Longitude_ISig_4_18f6276 12000;
BA_REL_ "GenSigTimeoutTime" BU_SG_REL_ BBM SG_ 2566268768 GPSData_Longitude_ISig_4_18f6276 3000;
BA_REL_ "GenSigFirstTimeoutTime" BU_SG_REL_ BBM SG_ 2566268768 GPSData_VehSpeed_ISig_4_18f62760 12000;
BA_REL_ "GenSigTimeoutTime" BU_SG_REL_ BBM SG_ 2566268768 GPSData_VehSpeed_ISig_4_18f62760 3000;
BA_REL_ "GenSigFirstTimeoutTime" BU_SG_REL_ BBM SG_ 2566268768 GPSData_Altitude_ISig_4_18f62760 12000;
BA_REL_ "GenSigTimeoutTime" BU_SG_REL_ BBM SG_ 2566268768 GPSData_Altitude_ISig_4_18f62760 3000;
BA_REL_ "GenSigFirstTimeoutTime" BU_SG_REL_ BBM SG_ 2566268768 GPSData_Latitude_ISig_4_18f62760 12000;
BA_REL_ "GenSigTimeoutTime" BU_SG_REL_ BBM SG_ 2566268768 GPSData_Latitude_ISig_4_18f62760 3000;
BA_REL_ "GenSigFirstTimeoutTime" BU_SG_REL_ BBM SG_ 2566268768 GPSData_AntennaStat_ISig_4__0003 12000;
BA_REL_ "GenSigTimeoutTime" BU_SG_REL_ BBM SG_ 2566268768 GPSData_AntennaStat_ISig_4__0003 3000;
BA_REL_ "GenSigFirstTimeoutTime" BU_SG_REL_ CIOM SG_ 2566846816 Trailer5Type_ISig_4 24000;
BA_REL_ "GenSigTimeoutTime" BU_SG_REL_ CIOM SG_ 2566846816 Trailer5Type_ISig_4 6000;
BA_REL_ "GenSigFirstTimeoutTime" BU_SG_REL_ CIOM SG_ 2566846816 Trailer4NumberOfAxles_ISig_4 24000;
BA_REL_ "GenSigTimeoutTime" BU_SG_REL_ CIOM SG_ 2566846816 Trailer4NumberOfAxles_ISig_4 6000;
BA_REL_ "GenSigFirstTimeoutTime" BU_SG_REL_ CIOM SG_ 2566846816 Trailer2NumberOfAxles_ISig_4 24000;
BA_REL_ "GenSigTimeoutTime" BU_SG_REL_ CIOM SG_ 2566846816 Trailer2NumberOfAxles_ISig_4 6000;
BA_REL_ "GenSigFirstTimeoutTime" BU_SG_REL_ CIOM SG_ 2566846816 Trailer3Type_ISig_4 24000;
BA_REL_ "GenSigTimeoutTime" BU_SG_REL_ CIOM SG_ 2566846816 Trailer3Type_ISig_4 6000;
BA_REL_ "GenSigFirstTimeoutTime" BU_SG_REL_ CIOM SG_ 2566846816 Trailer3NumberOfAxles_ISig_4 24000;
BA_REL_ "GenSigTimeoutTime" BU_SG_REL_ CIOM SG_ 2566846816 Trailer3NumberOfAxles_ISig_4 6000;
BA_REL_ "GenSigFirstTimeoutTime" BU_SG_REL_ CIOM SG_ 2566846816 Trailer1NumberOfAxles_ISig_4 24000;
BA_REL_ "GenSigTimeoutTime" BU_SG_REL_ CIOM SG_ 2566846816 Trailer1NumberOfAxles_ISig_4 6000;
BA_REL_ "GenSigFirstTimeoutTime" BU_SG_REL_ CIOM SG_ 2566846816 Trailer5NumberOfAxles_ISig_4 24000;
BA_REL_ "GenSigTimeoutTime" BU_SG_REL_ CIOM SG_ 2566846816 Trailer5NumberOfAxles_ISig_4 6000;
BA_REL_ "GenSigFirstTimeoutTime" BU_SG_REL_ CIOM SG_ 2566846816 Trailer1Type_ISig_4 24000;
BA_REL_ "GenSigTimeoutTime" BU_SG_REL_ CIOM SG_ 2566846816 Trailer1Type_ISig_4 6000;
BA_REL_ "GenSigFirstTimeoutTime" BU_SG_REL_ CIOM SG_ 2566846816 Trailer4Type_ISig_4 24000;
BA_REL_ "GenSigTimeoutTime" BU_SG_REL_ CIOM SG_ 2566846816 Trailer4Type_ISig_4 6000;
BA_REL_ "GenSigFirstTimeoutTime" BU_SG_REL_ CIOM SG_ 2566846816 Trailer2Type_ISig_4 24000;
BA_REL_ "GenSigTimeoutTime" BU_SG_REL_ CIOM SG_ 2566846816 Trailer2Type_ISig_4 6000;
BA_REL_ "GenSigFirstTimeoutTime" BU_SG_REL_ VMCU SG_ 2566802272 Trailer5CalAxleLoad_AxleId_ISig_ 24000;
BA_REL_ "GenSigTimeoutTime" BU_SG_REL_ VMCU SG_ 2566802272 Trailer5CalAxleLoad_AxleId_ISig_ 6000;
BA_REL_ "GenSigFirstTimeoutTime" BU_SG_REL_ CIOM SG_ 2566802272 Trailer5CalAxleLoad_AxleId_ISig_ 24000;
BA_REL_ "GenSigTimeoutTime" BU_SG_REL_ CIOM SG_ 2566802272 Trailer5CalAxleLoad_AxleId_ISig_ 6000;
BA_REL_ "GenSigFirstTimeoutTime" BU_SG_REL_ CIOM SG_ 2566802272 Trailer5NumberOfFrontAxles_ISig_ 24000;
BA_REL_ "GenSigTimeoutTime" BU_SG_REL_ CIOM SG_ 2566802272 Trailer5NumberOfFrontAxles_ISig_ 6000;
BA_REL_ "GenSigFirstTimeoutTime" BU_SG_REL_ CIOM SG_ 2566802272 Trailer5CalibratedCargoLoad_ISig 24000;
BA_REL_ "GenSigTimeoutTime" BU_SG_REL_ CIOM SG_ 2566802272 Trailer5CalibratedCargoLoad_ISig 6000;
BA_REL_ "GenSigFirstTimeoutTime" BU_SG_REL_ BBM SG_ 2566802272 Trailer5CalibratedCargoLoad_ISig 24000;
BA_REL_ "GenSigTimeoutTime" BU_SG_REL_ BBM SG_ 2566802272 Trailer5CalibratedCargoLoad_ISig 6000;
BA_REL_ "GenSigFirstTimeoutTime" BU_SG_REL_ VMCU SG_ 2566802272 Trailer5CalibratedCargoLoad_ISig 24000;
BA_REL_ "GenSigTimeoutTime" BU_SG_REL_ VMCU SG_ 2566802272 Trailer5CalibratedCargoLoad_ISig 6000;
BA_REL_ "GenSigFirstTimeoutTime" BU_SG_REL_ VMCU SG_ 2566802272 Trailer5CalAxleLoad_AxleLoad_ISi 24000;
BA_REL_ "GenSigTimeoutTime" BU_SG_REL_ VMCU SG_ 2566802272 Trailer5CalAxleLoad_AxleLoad_ISi 6000;
BA_REL_ "GenSigFirstTimeoutTime" BU_SG_REL_ CIOM SG_ 2566802272 Trailer5CalAxleLoad_AxleLoad_ISi 24000;
BA_REL_ "GenSigTimeoutTime" BU_SG_REL_ CIOM SG_ 2566802272 Trailer5CalAxleLoad_AxleLoad_ISi 6000;
BA_REL_ "GenSigFirstTimeoutTime" BU_SG_REL_ VMCU SG_ 2566802272 Trailer5CalibratedTotalLoad_ISig 24000;
BA_REL_ "GenSigTimeoutTime" BU_SG_REL_ VMCU SG_ 2566802272 Trailer5CalibratedTotalLoad_ISig 6000;
BA_REL_ "GenSigFirstTimeoutTime" BU_SG_REL_ CIOM SG_ 2566802272 Trailer5CalibratedTotalLoad_ISig 24000;
BA_REL_ "GenSigTimeoutTime" BU_SG_REL_ CIOM SG_ 2566802272 Trailer5CalibratedTotalLoad_ISig 6000;
BA_REL_ "GenSigFirstTimeoutTime" BU_SG_REL_ BBM SG_ 2566802272 Trailer5CalibratedTotalLoad_ISig 24000;
BA_REL_ "GenSigTimeoutTime" BU_SG_REL_ BBM SG_ 2566802272 Trailer5CalibratedTotalLoad_ISig 6000;
BA_REL_ "GenSigFirstTimeoutTime" BU_SG_REL_ VMCU SG_ 2566757728 Trailer4CalAxleLoad_AxleId_ISig_ 24000;
BA_REL_ "GenSigTimeoutTime" BU_SG_REL_ VMCU SG_ 2566757728 Trailer4CalAxleLoad_AxleId_ISig_ 6000;
BA_REL_ "GenSigFirstTimeoutTime" BU_SG_REL_ CIOM SG_ 2566757728 Trailer4CalAxleLoad_AxleId_ISig_ 24000;
BA_REL_ "GenSigTimeoutTime" BU_SG_REL_ CIOM SG_ 2566757728 Trailer4CalAxleLoad_AxleId_ISig_ 6000;
BA_REL_ "GenSigFirstTimeoutTime" BU_SG_REL_ CIOM SG_ 2566757728 Trailer4NumberOfFrontAxles_ISig_ 24000;
BA_REL_ "GenSigTimeoutTime" BU_SG_REL_ CIOM SG_ 2566757728 Trailer4NumberOfFrontAxles_ISig_ 6000;
BA_REL_ "GenSigFirstTimeoutTime" BU_SG_REL_ CIOM SG_ 2566757728 Trailer4CalibratedTotalLoad_ISig 24000;
BA_REL_ "GenSigTimeoutTime" BU_SG_REL_ CIOM SG_ 2566757728 Trailer4CalibratedTotalLoad_ISig 6000;
BA_REL_ "GenSigFirstTimeoutTime" BU_SG_REL_ BBM SG_ 2566757728 Trailer4CalibratedTotalLoad_ISig 24000;
BA_REL_ "GenSigTimeoutTime" BU_SG_REL_ BBM SG_ 2566757728 Trailer4CalibratedTotalLoad_ISig 6000;
BA_REL_ "GenSigFirstTimeoutTime" BU_SG_REL_ VMCU SG_ 2566757728 Trailer4CalibratedTotalLoad_ISig 24000;
BA_REL_ "GenSigTimeoutTime" BU_SG_REL_ VMCU SG_ 2566757728 Trailer4CalibratedTotalLoad_ISig 6000;
BA_REL_ "GenSigFirstTimeoutTime" BU_SG_REL_ VMCU SG_ 2566757728 Trailer4CalAxleLoad_AxleLoad_ISi 24000;
BA_REL_ "GenSigTimeoutTime" BU_SG_REL_ VMCU SG_ 2566757728 Trailer4CalAxleLoad_AxleLoad_ISi 6000;
BA_REL_ "GenSigFirstTimeoutTime" BU_SG_REL_ CIOM SG_ 2566757728 Trailer4CalAxleLoad_AxleLoad_ISi 24000;
BA_REL_ "GenSigTimeoutTime" BU_SG_REL_ CIOM SG_ 2566757728 Trailer4CalAxleLoad_AxleLoad_ISi 6000;
BA_REL_ "GenSigFirstTimeoutTime" BU_SG_REL_ CIOM SG_ 2566757728 Trailer4CalibratedCargoLoad_ISig 24000;
BA_REL_ "GenSigTimeoutTime" BU_SG_REL_ CIOM SG_ 2566757728 Trailer4CalibratedCargoLoad_ISig 6000;
BA_REL_ "GenSigFirstTimeoutTime" BU_SG_REL_ VMCU SG_ 2566757728 Trailer4CalibratedCargoLoad_ISig 24000;
BA_REL_ "GenSigTimeoutTime" BU_SG_REL_ VMCU SG_ 2566757728 Trailer4CalibratedCargoLoad_ISig 6000;
BA_REL_ "GenSigFirstTimeoutTime" BU_SG_REL_ BBM SG_ 2566757728 Trailer4CalibratedCargoLoad_ISig 24000;
BA_REL_ "GenSigTimeoutTime" BU_SG_REL_ BBM SG_ 2566757728 Trailer4CalibratedCargoLoad_ISig 6000;
BA_REL_ "GenSigFirstTimeoutTime" BU_SG_REL_ VMCU SG_ 2566713184 Trailer3CalAxleLoad_AxleLoad_ISi 24000;
BA_REL_ "GenSigTimeoutTime" BU_SG_REL_ VMCU SG_ 2566713184 Trailer3CalAxleLoad_AxleLoad_ISi 6000;
BA_REL_ "GenSigFirstTimeoutTime" BU_SG_REL_ CIOM SG_ 2566713184 Trailer3CalAxleLoad_AxleLoad_ISi 24000;
BA_REL_ "GenSigTimeoutTime" BU_SG_REL_ CIOM SG_ 2566713184 Trailer3CalAxleLoad_AxleLoad_ISi 6000;
BA_REL_ "GenSigFirstTimeoutTime" BU_SG_REL_ CIOM SG_ 2566713184 Trailer3NumberOfFrontAxles_ISig_ 24000;
BA_REL_ "GenSigTimeoutTime" BU_SG_REL_ CIOM SG_ 2566713184 Trailer3NumberOfFrontAxles_ISig_ 6000;
BA_REL_ "GenSigFirstTimeoutTime" BU_SG_REL_ VMCU SG_ 2566713184 Trailer3CalibratedTotalLoad_ISig 24000;
BA_REL_ "GenSigTimeoutTime" BU_SG_REL_ VMCU SG_ 2566713184 Trailer3CalibratedTotalLoad_ISig 6000;
BA_REL_ "GenSigFirstTimeoutTime" BU_SG_REL_ CIOM SG_ 2566713184 Trailer3CalibratedTotalLoad_ISig 24000;
BA_REL_ "GenSigTimeoutTime" BU_SG_REL_ CIOM SG_ 2566713184 Trailer3CalibratedTotalLoad_ISig 6000;
BA_REL_ "GenSigFirstTimeoutTime" BU_SG_REL_ BBM SG_ 2566713184 Trailer3CalibratedTotalLoad_ISig 24000;
BA_REL_ "GenSigTimeoutTime" BU_SG_REL_ BBM SG_ 2566713184 Trailer3CalibratedTotalLoad_ISig 6000;
BA_REL_ "GenSigFirstTimeoutTime" BU_SG_REL_ VMCU SG_ 2566713184 Trailer3CalAxleLoad_AxleId_ISig_ 24000;
BA_REL_ "GenSigTimeoutTime" BU_SG_REL_ VMCU SG_ 2566713184 Trailer3CalAxleLoad_AxleId_ISig_ 6000;
BA_REL_ "GenSigFirstTimeoutTime" BU_SG_REL_ CIOM SG_ 2566713184 Trailer3CalAxleLoad_AxleId_ISig_ 24000;
BA_REL_ "GenSigTimeoutTime" BU_SG_REL_ CIOM SG_ 2566713184 Trailer3CalAxleLoad_AxleId_ISig_ 6000;
BA_REL_ "GenSigFirstTimeoutTime" BU_SG_REL_ VMCU SG_ 2566713184 Trailer3CalibratedCargoLoad_ISig 24000;
BA_REL_ "GenSigTimeoutTime" BU_SG_REL_ VMCU SG_ 2566713184 Trailer3CalibratedCargoLoad_ISig 6000;
BA_REL_ "GenSigFirstTimeoutTime" BU_SG_REL_ BBM SG_ 2566713184 Trailer3CalibratedCargoLoad_ISig 24000;
BA_REL_ "GenSigTimeoutTime" BU_SG_REL_ BBM SG_ 2566713184 Trailer3CalibratedCargoLoad_ISig 6000;
BA_REL_ "GenSigFirstTimeoutTime" BU_SG_REL_ CIOM SG_ 2566713184 Trailer3CalibratedCargoLoad_ISig 24000;
BA_REL_ "GenSigTimeoutTime" BU_SG_REL_ CIOM SG_ 2566713184 Trailer3CalibratedCargoLoad_ISig 6000;
BA_REL_ "GenSigFirstTimeoutTime" BU_SG_REL_ CIOM SG_ 2566668640 Trailer2NumberOfFrontAxles_ISig_ 24000;
BA_REL_ "GenSigTimeoutTime" BU_SG_REL_ CIOM SG_ 2566668640 Trailer2NumberOfFrontAxles_ISig_ 6000;
BA_REL_ "GenSigFirstTimeoutTime" BU_SG_REL_ CIOM SG_ 2566668640 Trailer2CalAxleLoad_AxleId_ISig_ 24000;
BA_REL_ "GenSigTimeoutTime" BU_SG_REL_ CIOM SG_ 2566668640 Trailer2CalAxleLoad_AxleId_ISig_ 6000;
BA_REL_ "GenSigFirstTimeoutTime" BU_SG_REL_ VMCU SG_ 2566668640 Trailer2CalAxleLoad_AxleId_ISig_ 24000;
BA_REL_ "GenSigTimeoutTime" BU_SG_REL_ VMCU SG_ 2566668640 Trailer2CalAxleLoad_AxleId_ISig_ 6000;
BA_REL_ "GenSigFirstTimeoutTime" BU_SG_REL_ VMCU SG_ 2566668640 Trailer2CalAxleLoad_AxleLoad_ISi 24000;
BA_REL_ "GenSigTimeoutTime" BU_SG_REL_ VMCU SG_ 2566668640 Trailer2CalAxleLoad_AxleLoad_ISi 6000;
BA_REL_ "GenSigFirstTimeoutTime" BU_SG_REL_ CIOM SG_ 2566668640 Trailer2CalAxleLoad_AxleLoad_ISi 24000;
BA_REL_ "GenSigTimeoutTime" BU_SG_REL_ CIOM SG_ 2566668640 Trailer2CalAxleLoad_AxleLoad_ISi 6000;
BA_REL_ "GenSigFirstTimeoutTime" BU_SG_REL_ CIOM SG_ 2566668640 Trailer2CalibratedTotalLoad_ISig 24000;
BA_REL_ "GenSigTimeoutTime" BU_SG_REL_ CIOM SG_ 2566668640 Trailer2CalibratedTotalLoad_ISig 6000;
BA_REL_ "GenSigFirstTimeoutTime" BU_SG_REL_ BBM SG_ 2566668640 Trailer2CalibratedTotalLoad_ISig 24000;
BA_REL_ "GenSigTimeoutTime" BU_SG_REL_ BBM SG_ 2566668640 Trailer2CalibratedTotalLoad_ISig 6000;
BA_REL_ "GenSigFirstTimeoutTime" BU_SG_REL_ VMCU SG_ 2566668640 Trailer2CalibratedTotalLoad_ISig 24000;
BA_REL_ "GenSigTimeoutTime" BU_SG_REL_ VMCU SG_ 2566668640 Trailer2CalibratedTotalLoad_ISig 6000;
BA_REL_ "GenSigFirstTimeoutTime" BU_SG_REL_ CIOM SG_ 2566668640 Trailer2CalibratedCargoLoad_ISig 24000;
BA_REL_ "GenSigTimeoutTime" BU_SG_REL_ CIOM SG_ 2566668640 Trailer2CalibratedCargoLoad_ISig 6000;
BA_REL_ "GenSigFirstTimeoutTime" BU_SG_REL_ VMCU SG_ 2566668640 Trailer2CalibratedCargoLoad_ISig 24000;
BA_REL_ "GenSigTimeoutTime" BU_SG_REL_ VMCU SG_ 2566668640 Trailer2CalibratedCargoLoad_ISig 6000;
BA_REL_ "GenSigFirstTimeoutTime" BU_SG_REL_ BBM SG_ 2566668640 Trailer2CalibratedCargoLoad_ISig 24000;
BA_REL_ "GenSigTimeoutTime" BU_SG_REL_ BBM SG_ 2566668640 Trailer2CalibratedCargoLoad_ISig 6000;
BA_REL_ "GenSigFirstTimeoutTime" BU_SG_REL_ CIOM SG_ 2566624096 Trailer1CalAxleLoad_AxleLoad_ISi 24000;
BA_REL_ "GenSigTimeoutTime" BU_SG_REL_ CIOM SG_ 2566624096 Trailer1CalAxleLoad_AxleLoad_ISi 6000;
BA_REL_ "GenSigFirstTimeoutTime" BU_SG_REL_ VMCU SG_ 2566624096 Trailer1CalAxleLoad_AxleLoad_ISi 24000;
BA_REL_ "GenSigTimeoutTime" BU_SG_REL_ VMCU SG_ 2566624096 Trailer1CalAxleLoad_AxleLoad_ISi 6000;
BA_REL_ "GenSigFirstTimeoutTime" BU_SG_REL_ VMCU SG_ 2566624096 Trailer1CalibratedTotalLoad_ISig 24000;
BA_REL_ "GenSigTimeoutTime" BU_SG_REL_ VMCU SG_ 2566624096 Trailer1CalibratedTotalLoad_ISig 6000;
BA_REL_ "GenSigFirstTimeoutTime" BU_SG_REL_ CIOM SG_ 2566624096 Trailer1CalibratedTotalLoad_ISig 24000;
BA_REL_ "GenSigTimeoutTime" BU_SG_REL_ CIOM SG_ 2566624096 Trailer1CalibratedTotalLoad_ISig 6000;
BA_REL_ "GenSigFirstTimeoutTime" BU_SG_REL_ BBM SG_ 2566624096 Trailer1CalibratedTotalLoad_ISig 24000;
BA_REL_ "GenSigTimeoutTime" BU_SG_REL_ BBM SG_ 2566624096 Trailer1CalibratedTotalLoad_ISig 6000;
BA_REL_ "GenSigFirstTimeoutTime" BU_SG_REL_ CIOM SG_ 2566624096 Trailer1CalAxleLoad_AxleId_ISig_ 24000;
BA_REL_ "GenSigTimeoutTime" BU_SG_REL_ CIOM SG_ 2566624096 Trailer1CalAxleLoad_AxleId_ISig_ 6000;
BA_REL_ "GenSigFirstTimeoutTime" BU_SG_REL_ VMCU SG_ 2566624096 Trailer1CalAxleLoad_AxleId_ISig_ 24000;
BA_REL_ "GenSigTimeoutTime" BU_SG_REL_ VMCU SG_ 2566624096 Trailer1CalAxleLoad_AxleId_ISig_ 6000;
BA_REL_ "GenSigFirstTimeoutTime" BU_SG_REL_ CIOM SG_ 2566624096 Trailer1NumberOfFrontAxles_ISig_ 24000;
BA_REL_ "GenSigTimeoutTime" BU_SG_REL_ CIOM SG_ 2566624096 Trailer1NumberOfFrontAxles_ISig_ 6000;
BA_REL_ "GenSigFirstTimeoutTime" BU_SG_REL_ VMCU SG_ 2566624096 Trailer1CalibratedCargoLoad_ISig 24000;
BA_REL_ "GenSigTimeoutTime" BU_SG_REL_ VMCU SG_ 2566624096 Trailer1CalibratedCargoLoad_ISig 6000;
BA_REL_ "GenSigFirstTimeoutTime" BU_SG_REL_ CIOM SG_ 2566624096 Trailer1CalibratedCargoLoad_ISig 24000;
BA_REL_ "GenSigTimeoutTime" BU_SG_REL_ CIOM SG_ 2566624096 Trailer1CalibratedCargoLoad_ISig 6000;
BA_REL_ "GenSigFirstTimeoutTime" BU_SG_REL_ BBM SG_ 2566624096 Trailer1CalibratedCargoLoad_ISig 24000;
BA_REL_ "GenSigTimeoutTime" BU_SG_REL_ BBM SG_ 2566624096 Trailer1CalibratedCargoLoad_ISig 6000;
BA_REL_ "GenSigFirstTimeoutTime" BU_SG_REL_ CIOM SG_ 2566579552 VehRearAxle1CalibratedLoad_ISig_ 24000;
BA_REL_ "GenSigTimeoutTime" BU_SG_REL_ CIOM SG_ 2566579552 VehRearAxle1CalibratedLoad_ISig_ 6000;
BA_REL_ "GenSigFirstTimeoutTime" BU_SG_REL_ BBM SG_ 2566579552 VehRearAxle1CalibratedLoad_ISig_ 24000;
BA_REL_ "GenSigTimeoutTime" BU_SG_REL_ BBM SG_ 2566579552 VehRearAxle1CalibratedLoad_ISig_ 6000;
BA_REL_ "GenSigFirstTimeoutTime" BU_SG_REL_ VMCU SG_ 2566579552 VehRearAxle1CalibratedLoad_ISig_ 24000;
BA_REL_ "GenSigTimeoutTime" BU_SG_REL_ VMCU SG_ 2566579552 VehRearAxle1CalibratedLoad_ISig_ 6000;
BA_REL_ "GenSigFirstTimeoutTime" BU_SG_REL_ VMCU SG_ 2566579552 VehRearAxle2CalibratedLoad_ISig_ 24000;
BA_REL_ "GenSigTimeoutTime" BU_SG_REL_ VMCU SG_ 2566579552 VehRearAxle2CalibratedLoad_ISig_ 6000;
BA_REL_ "GenSigFirstTimeoutTime" BU_SG_REL_ BBM SG_ 2566579552 VehRearAxle2CalibratedLoad_ISig_ 24000;
BA_REL_ "GenSigTimeoutTime" BU_SG_REL_ BBM SG_ 2566579552 VehRearAxle2CalibratedLoad_ISig_ 6000;
BA_REL_ "GenSigFirstTimeoutTime" BU_SG_REL_ CIOM SG_ 2566579552 VehRearAxle2CalibratedLoad_ISig_ 24000;
BA_REL_ "GenSigTimeoutTime" BU_SG_REL_ CIOM SG_ 2566579552 VehRearAxle2CalibratedLoad_ISig_ 6000;
BA_REL_ "GenSigFirstTimeoutTime" BU_SG_REL_ VMCU SG_ 2566579552 VehRearAxle3CalibratedLoad_ISig_ 24000;
BA_REL_ "GenSigTimeoutTime" BU_SG_REL_ VMCU SG_ 2566579552 VehRearAxle3CalibratedLoad_ISig_ 6000;
BA_REL_ "GenSigFirstTimeoutTime" BU_SG_REL_ CIOM SG_ 2566579552 VehRearAxle3CalibratedLoad_ISig_ 24000;
BA_REL_ "GenSigTimeoutTime" BU_SG_REL_ CIOM SG_ 2566579552 VehRearAxle3CalibratedLoad_ISig_ 6000;
BA_REL_ "GenSigFirstTimeoutTime" BU_SG_REL_ BBM SG_ 2566579552 VehRearAxle3CalibratedLoad_ISig_ 24000;
BA_REL_ "GenSigTimeoutTime" BU_SG_REL_ BBM SG_ 2566579552 VehRearAxle3CalibratedLoad_ISig_ 6000;
BA_REL_ "GenSigFirstTimeoutTime" BU_SG_REL_ CIOM SG_ 2566535008 VehicleCalibratedCargoLoad_ISig_ 24000;
BA_REL_ "GenSigTimeoutTime" BU_SG_REL_ CIOM SG_ 2566535008 VehicleCalibratedCargoLoad_ISig_ 6000;
BA_REL_ "GenSigFirstTimeoutTime" BU_SG_REL_ VMCU SG_ 2566535008 VehicleCalibratedCargoLoad_ISig_ 24000;
BA_REL_ "GenSigTimeoutTime" BU_SG_REL_ VMCU SG_ 2566535008 VehicleCalibratedCargoLoad_ISig_ 6000;
BA_REL_ "GenSigFirstTimeoutTime" BU_SG_REL_ VMCU SG_ 2566535008 VehFrontAxle2CalibratedLoad_ISig 24000;
BA_REL_ "GenSigTimeoutTime" BU_SG_REL_ VMCU SG_ 2566535008 VehFrontAxle2CalibratedLoad_ISig 6000;
BA_REL_ "GenSigFirstTimeoutTime" BU_SG_REL_ CIOM SG_ 2566535008 VehFrontAxle2CalibratedLoad_ISig 24000;
BA_REL_ "GenSigTimeoutTime" BU_SG_REL_ CIOM SG_ 2566535008 VehFrontAxle2CalibratedLoad_ISig 6000;
BA_REL_ "GenSigFirstTimeoutTime" BU_SG_REL_ BBM SG_ 2566535008 VehFrontAxle2CalibratedLoad_ISig 24000;
BA_REL_ "GenSigTimeoutTime" BU_SG_REL_ BBM SG_ 2566535008 VehFrontAxle2CalibratedLoad_ISig 6000;
BA_REL_ "GenSigFirstTimeoutTime" BU_SG_REL_ BBM SG_ 2566535008 VehFrontAxle1CalibratedLoad_ISig 24000;
BA_REL_ "GenSigTimeoutTime" BU_SG_REL_ BBM SG_ 2566535008 VehFrontAxle1CalibratedLoad_ISig 6000;
BA_REL_ "GenSigFirstTimeoutTime" BU_SG_REL_ VMCU SG_ 2566535008 VehFrontAxle1CalibratedLoad_ISig 24000;
BA_REL_ "GenSigTimeoutTime" BU_SG_REL_ VMCU SG_ 2566535008 VehFrontAxle1CalibratedLoad_ISig 6000;
BA_REL_ "GenSigFirstTimeoutTime" BU_SG_REL_ CIOM SG_ 2566535008 VehFrontAxle1CalibratedLoad_ISig 24000;
BA_REL_ "GenSigTimeoutTime" BU_SG_REL_ CIOM SG_ 2566535008 VehFrontAxle1CalibratedLoad_ISig 6000;
BA_REL_ "GenSigFirstTimeoutTime" BU_SG_REL_ VMCU SG_ 2566535008 VehicleCalibratedLoad_ISig_4 24000;
BA_REL_ "GenSigTimeoutTime" BU_SG_REL_ VMCU SG_ 2566535008 VehicleCalibratedLoad_ISig_4 6000;
BA_REL_ "GenSigFirstTimeoutTime" BU_SG_REL_ BBM SG_ 2566535008 VehicleCalibratedLoad_ISig_4 24000;
BA_REL_ "GenSigTimeoutTime" BU_SG_REL_ BBM SG_ 2566535008 VehicleCalibratedLoad_ISig_4 6000;
BA_REL_ "GenSigFirstTimeoutTime" BU_SG_REL_ CIOM SG_ 2566535008 VehicleCalibratedLoad_ISig_4 24000;
BA_REL_ "GenSigTimeoutTime" BU_SG_REL_ CIOM SG_ 2566535008 VehicleCalibratedLoad_ISig_4 6000;
BA_REL_ "GenSigFirstTimeoutTime" BU_SG_REL_ DACU SG_ 2566535008 VehicleCalibratedLoad_ISig_4 24000;
BA_REL_ "GenSigTimeoutTime" BU_SG_REL_ DACU SG_ 2566535008 VehicleCalibratedLoad_ISig_4 6000;
BA_REL_ "GenSigFirstTimeoutTime" BU_SG_REL_ CIOM SG_ 2515802464 AlarmClockAlarms_stat_Mode_ISig_ 3600;
BA_REL_ "GenSigTimeoutTime" BU_SG_REL_ CIOM SG_ 2515802464 AlarmClockAlarms_stat_Mode_ISig_ 900;
BA_REL_ "GenSigFirstTimeoutTime" BU_SG_REL_ CIOM SG_ 2515802464 AlarmClockAlarms_stat_Type_ISig_ 3600;
BA_REL_ "GenSigTimeoutTime" BU_SG_REL_ CIOM SG_ 2515802464 AlarmClockAlarms_stat_Type_ISig_ 900;
BA_REL_ "GenSigFirstTimeoutTime" BU_SG_REL_ CIOM SG_ 2515802464 AlarmClockAlarms_stat_DaySet_ISi 3600;
BA_REL_ "GenSigTimeoutTime" BU_SG_REL_ CIOM SG_ 2515802464 AlarmClockAlarms_stat_DaySet_ISi 900;
BA_REL_ "GenSigFirstTimeoutTime" BU_SG_REL_ CIOM SG_ 2515802464 AlarmClockAlarms_stat_ID_ISig_4 3600;
BA_REL_ "GenSigTimeoutTime" BU_SG_REL_ CIOM SG_ 2515802464 AlarmClockAlarms_stat_ID_ISig_4 900;
BA_REL_ "GenSigFirstTimeoutTime" BU_SG_REL_ CIOM SG_ 2515802464 AlmClkCurAlarm_stat_SetMin 3600;
BA_REL_ "GenSigTimeoutTime" BU_SG_REL_ CIOM SG_ 2515802464 AlmClkCurAlarm_stat_SetMin 900;
BA_REL_ "GenSigFirstTimeoutTime" BU_SG_REL_ CIOM SG_ 2515802464 AlarmClockAlarms_stat_Stat_ISig_ 3600;
BA_REL_ "GenSigTimeoutTime" BU_SG_REL_ CIOM SG_ 2515802464 AlarmClockAlarms_stat_Stat_ISig_ 900;
BA_REL_ "GenSigFirstTimeoutTime" BU_SG_REL_ CIOM SG_ 2515802464 AlmClkCurAlarm_stat_Stat 3600;
BA_REL_ "GenSigTimeoutTime" BU_SG_REL_ CIOM SG_ 2515802464 AlmClkCurAlarm_stat_Stat 900;
BA_REL_ "GenSigFirstTimeoutTime" BU_SG_REL_ CIOM SG_ 2515802464 AlmClkCurAlarm_stat_ID 3600;
BA_REL_ "GenSigTimeoutTime" BU_SG_REL_ CIOM SG_ 2515802464 AlmClkCurAlarm_stat_ID 900;
BA_REL_ "GenSigFirstTimeoutTime" BU_SG_REL_ CIOM SG_ 2515802464 AlarmClockAlarms_stat_SetMin_ISi 3600;
BA_REL_ "GenSigTimeoutTime" BU_SG_REL_ CIOM SG_ 2515802464 AlarmClockAlarms_stat_SetMin_ISi 900;
BA_REL_ "GenSigFirstTimeoutTime" BU_SG_REL_ CIOM SG_ 2515802464 AlmClkCurAlarm_stat_Type 3600;
BA_REL_ "GenSigTimeoutTime" BU_SG_REL_ CIOM SG_ 2515802464 AlmClkCurAlarm_stat_Type 900;
BA_REL_ "GenSigFirstTimeoutTime" BU_SG_REL_ CIOM SG_ 2515802464 AlarmClockAlarms_stat_SetHr_ISig 3600;
BA_REL_ "GenSigTimeoutTime" BU_SG_REL_ CIOM SG_ 2515802464 AlarmClockAlarms_stat_SetHr_ISig 900;
BA_REL_ "GenSigFirstTimeoutTime" BU_SG_REL_ CIOM SG_ 2515802464 AlmClkCurAlarm_stat_SetHr 3600;
BA_REL_ "GenSigTimeoutTime" BU_SG_REL_ CIOM SG_ 2515802464 AlmClkCurAlarm_stat_SetHr 900;
BA_REL_ "GenSigFirstTimeoutTime" BU_SG_REL_ CIOM SG_ 2499801297 PinCodeEntered_value 3000;
BA_REL_ "GenSigTimeoutTime" BU_SG_REL_ CIOM SG_ 2499801297 PinCodeEntered_value 450;
BA_REL_ "GenSigFirstTimeoutTime" BU_SG_REL_ VMCU SG_ 2499801297 DriverNewOilQuality 3000;
BA_REL_ "GenSigTimeoutTime" BU_SG_REL_ VMCU SG_ 2499801297 DriverNewOilQuality 450;
BA_REL_ "GenSigFirstTimeoutTime" BU_SG_REL_ CIOM SG_ 2499801297 DynamicCode_rqst 3000;
BA_REL_ "GenSigTimeoutTime" BU_SG_REL_ CIOM SG_ 2499801297 DynamicCode_rqst 450;
BA_REL_ "GenSigFirstTimeoutTime" BU_SG_REL_ VMCU SG_ 2499801297 FrontWheelDriveMenuRequest 3000;
BA_REL_ "GenSigTimeoutTime" BU_SG_REL_ VMCU SG_ 2499801297 FrontWheelDriveMenuRequest 450;
BA_REL_ "GenSigFirstTimeoutTime" BU_SG_REL_ VMCU SG_ 2499801297 DriverNewBatteryCapacity 3000;
BA_REL_ "GenSigTimeoutTime" BU_SG_REL_ VMCU SG_ 2499801297 DriverNewBatteryCapacity 450;
BA_REL_ "GenSigFirstTimeoutTime" BU_SG_REL_ VMCU SG_ 2499801297 LogDisplayedMessage_req 3000;
BA_REL_ "GenSigTimeoutTime" BU_SG_REL_ VMCU SG_ 2499801297 LogDisplayedMessage_req 500;
BA_REL_ "GenSigFirstTimeoutTime" BU_SG_REL_ VMCU SG_ 2499794044 FirstAxleLowerPrioRequested_ISig 3000;
BA_REL_ "GenSigTimeoutTime" BU_SG_REL_ VMCU SG_ 2499794044 FirstAxleLowerPrioRequested_ISig 500;
BA_REL_ "GenSigFirstTimeoutTime" BU_SG_REL_ VMCU SG_ 2499794044 MaintInfo_rqst_ISig_4 3000;
BA_REL_ "GenSigTimeoutTime" BU_SG_REL_ VMCU SG_ 2499794044 MaintInfo_rqst_ISig_4 450;
BA_REL_ "GenSigFirstTimeoutTime" BU_SG_REL_ CIOM SG_ 2499794044 Synch_Unsynch_Mode_stat 3000;
BA_REL_ "GenSigTimeoutTime" BU_SG_REL_ CIOM SG_ 2499794044 Synch_Unsynch_Mode_stat 450;
BA_REL_ "GenSigFirstTimeoutTime" BU_SG_REL_ VMCU SG_ 2499794044 MaintResetRqst_ID 3000;
BA_REL_ "GenSigTimeoutTime" BU_SG_REL_ VMCU SG_ 2499794044 MaintResetRqst_ID 450;
BA_REL_ "GenSigFirstTimeoutTime" BU_SG_REL_ VMCU SG_ 2499794044 TrailerBrakeInputStatus 3000;
BA_REL_ "GenSigTimeoutTime" BU_SG_REL_ VMCU SG_ 2499794044 TrailerBrakeInputStatus 500;
BA_REL_ "GenSigFirstTimeoutTime" BU_SG_REL_ VMCU SG_ 2499794044 MaintResetRqst_StatusRqst 3000;
BA_REL_ "GenSigTimeoutTime" BU_SG_REL_ VMCU SG_ 2499794044 MaintResetRqst_StatusRqst 450;
BA_REL_ "GenSigFirstTimeoutTime" BU_SG_REL_ VMCU SG_ 2499794044 SelectedSpeedUnit_stat_ISig_4 3000;
BA_REL_ "GenSigTimeoutTime" BU_SG_REL_ VMCU SG_ 2499794044 SelectedSpeedUnit_stat_ISig_4 450;
BA_REL_ "GenSigFirstTimeoutTime" BU_SG_REL_ BBM SG_ 2499794044 SelectedLanguage_stat_ISig_4 3000;
BA_REL_ "GenSigTimeoutTime" BU_SG_REL_ BBM SG_ 2499794044 SelectedLanguage_stat_ISig_4 450;
BA_REL_ "GenSigFirstTimeoutTime" BU_SG_REL_ CIOM SG_ 2499794044 SelectedLanguage_stat_ISig_4 3000;
BA_REL_ "GenSigTimeoutTime" BU_SG_REL_ CIOM SG_ 2499794044 SelectedLanguage_stat_ISig_4 450;
BA_REL_ "GenSigFirstTimeoutTime" BU_SG_REL_ VMCU SG_ 2499794044 LampCheck_rqst_ISig_4 3000;
BA_REL_ "GenSigTimeoutTime" BU_SG_REL_ VMCU SG_ 2499794044 LampCheck_rqst_ISig_4 450;
BA_REL_ "GenSigFirstTimeoutTime" BU_SG_REL_ CIOM SG_ 2499794044 ParkingHeaterCleaning_cmd_ISig_4 3000;
BA_REL_ "GenSigTimeoutTime" BU_SG_REL_ CIOM SG_ 2499794044 ParkingHeaterCleaning_cmd_ISig_4 450;
BA_REL_ "GenSigFirstTimeoutTime" BU_SG_REL_ CIOM SG_ 2499794044 SelectedWeightUnit_stat_ISig_4 3000;
BA_REL_ "GenSigTimeoutTime" BU_SG_REL_ CIOM SG_ 2499794044 SelectedWeightUnit_stat_ISig_4 450;
BA_REL_ "GenSigFirstTimeoutTime" BU_SG_REL_ CIOM SG_ 2499794044 SpeedLockingInhibition_stat 3000;
BA_REL_ "GenSigTimeoutTime" BU_SG_REL_ CIOM SG_ 2499794044 SpeedLockingInhibition_stat 450;
BA_REL_ "GenSigFirstTimeoutTime" BU_SG_REL_ VMCU SG_ 2499794044 MaintInfoRqst 3000;
BA_REL_ "GenSigTimeoutTime" BU_SG_REL_ VMCU SG_ 2499794044 MaintInfoRqst 450;
BA_REL_ "GenSigFirstTimeoutTime" BU_SG_REL_ CIOM SG_ 2499794044 ParkHeaterTimerReleased_stat_ISi 3000;
BA_REL_ "GenSigTimeoutTime" BU_SG_REL_ CIOM SG_ 2499794044 ParkHeaterTimerReleased_stat_ISi 450;
BA_REL_ "GenSigFirstTimeoutTime" BU_SG_REL_ CIOM SG_ 2499794044 DriverMemory_rqst_ISig_4 3000;
BA_REL_ "GenSigTimeoutTime" BU_SG_REL_ CIOM SG_ 2499794044 DriverMemory_rqst_ISig_4 450;
BA_REL_ "GenSigFirstTimeoutTime" BU_SG_REL_ VMCU SG_ 2499794044 DriverMemory_rqst_ISig_4 3000;
BA_REL_ "GenSigTimeoutTime" BU_SG_REL_ VMCU SG_ 2499794044 DriverMemory_rqst_ISig_4 450;
BA_REL_ "GenSigFirstTimeoutTime" BU_SG_REL_ CIOM SG_ 2499794044 SelectedTimeFormat_stat_ISig_4 3000;
BA_REL_ "GenSigTimeoutTime" BU_SG_REL_ CIOM SG_ 2499794044 SelectedTimeFormat_stat_ISig_4 450;
BA_REL_ "GenSigFirstTimeoutTime" BU_SG_REL_ VMCU SG_ 2499794044 RefrigTimerReleased_stat 3000;
BA_REL_ "GenSigTimeoutTime" BU_SG_REL_ VMCU SG_ 2499794044 RefrigTimerReleased_stat 450;
BA_REL_ "GenSigFirstTimeoutTime" BU_SG_REL_ DACU SG_ 2499794044 LCSSoundSettingRequest 3000;
BA_REL_ "GenSigTimeoutTime" BU_SG_REL_ DACU SG_ 2499794044 LCSSoundSettingRequest 450;
VAL_ 2565494112 TPMSetAxleTireConfig_Axle4_ISig_ 7 "TPMAxleConfig_NotAvailable" 6 "TPMAxleConfig_Error" 5 "TPMAxleConfig_Spare" 4 "TPMAxleConfig_RearAxleWith4Tires" 3 "TPMAxleConfig_RearAxleWith2Tires" 2 "TPMAxleConfig_FrontAxleWith4Tires" 1 "TPMAxleConfig_FrontAxleWith2Tires" 0 "TPMAxleConfig_NotPresent" ;
VAL_ 2565494112 TPMSetAxleTireConfig_Axle5_ISig_ 7 "TPMAxleConfig_NotAvailable" 6 "TPMAxleConfig_Error" 5 "TPMAxleConfig_Spare" 4 "TPMAxleConfig_RearAxleWith4Tires" 3 "TPMAxleConfig_RearAxleWith2Tires" 2 "TPMAxleConfig_FrontAxleWith4Tires" 1 "TPMAxleConfig_FrontAxleWith2Tires" 0 "TPMAxleConfig_NotPresent" ;
VAL_ 2565494112 TPMSetPresThresCfg_VehiclePos_IS 7 "TPMVehiclePos_NotAvailable" 6 "TPMVehiclePos_Error" 5 "TPMVehiclePos_Trailer5Vehicle" 4 "TPMVehiclePos_Trailer4Vehicle" 3 "TPMVehiclePos_Trailer3Vehicle" 2 "TPMVehiclePos_Trailer2Vehicle" 1 "TPMVehiclePos_Trailer1Vehicle" 0 "TPMVehiclePos_TruckVehicle" ;
VAL_ 2565494112 TPMSetAxleTireConfig_Axle2_ISig_ 7 "TPMAxleConfig_NotAvailable" 6 "TPMAxleConfig_Error" 5 "TPMAxleConfig_Spare" 4 "TPMAxleConfig_RearAxleWith4Tires" 3 "TPMAxleConfig_RearAxleWith2Tires" 2 "TPMAxleConfig_FrontAxleWith4Tires" 1 "TPMAxleConfig_FrontAxleWith2Tires" 0 "TPMAxleConfig_NotPresent" ;
VAL_ 2565494112 TPMSetAxleTireConfig_VehiclePos_ 7 "TPMVehiclePos_NotAvailable" 6 "TPMVehiclePos_Error" 5 "TPMVehiclePos_Trailer5Vehicle" 4 "TPMVehiclePos_Trailer4Vehicle" 3 "TPMVehiclePos_Trailer3Vehicle" 2 "TPMVehiclePos_Trailer2Vehicle" 1 "TPMVehiclePos_Trailer1Vehicle" 0 "TPMVehiclePos_TruckVehicle" ;
VAL_ 2565494112 TPMSetAxleTireConfig_Axle3_ISig_ 7 "TPMAxleConfig_NotAvailable" 6 "TPMAxleConfig_Error" 5 "TPMAxleConfig_Spare" 4 "TPMAxleConfig_RearAxleWith4Tires" 3 "TPMAxleConfig_RearAxleWith2Tires" 2 "TPMAxleConfig_FrontAxleWith4Tires" 1 "TPMAxleConfig_FrontAxleWith2Tires" 0 "TPMAxleConfig_NotPresent" ;
VAL_ 2565494112 TPMSetAxleTireConfig_Axle1_ISig_ 7 "TPMAxleConfig_NotAvailable" 6 "TPMAxleConfig_Error" 5 "TPMAxleConfig_Spare" 4 "TPMAxleConfig_RearAxleWith4Tires" 3 "TPMAxleConfig_RearAxleWith2Tires" 2 "TPMAxleConfig_FrontAxleWith4Tires" 1 "TPMAxleConfig_FrontAxleWith2Tires" 0 "TPMAxleConfig_NotPresent" ;
VAL_ 2565494112 TPMSetPresThresCfg_AxleNr_ISig_4 7 "TPMAxleNr_NotAvailable" 6 "TPMAxleNr_Error" 5 "TPMAxleNr_Axle5" 4 "TPMAxleNr_Axle4" 3 "TPMAxleNr_Axle3" 2 "TPMAxleNr_Axle2" 1 "TPMAxleNr_Axle1" 0 "TPMAxleNr_NoRequest" ;
VAL_ 2566356832 PHTimerTGWEvCmd_Timer1Temp_ISig_ 31 "TemperatureRqstIndication_cmd_NotAvailable" 30 "TemperatureRqstIndication_cmd_Error" 29 "TemperatureRqstIndication_cmd_Spare_01" 28 "TemperatureRqstIndication_cmd_Spare" 27 "TemperatureRqstIndication_cmd_Max" 26 "TemperatureRqstIndication_cmd_29C" 25 "TemperatureRqstIndication_cmd_28C" 24 "TemperatureRqstIndication_cmd_27C" 23 "TemperatureRqstIndication_cmd_26C" 22 "TemperatureRqstIndication_cmd_25_5C" 21 "TemperatureRqstIndication_cmd_25C" 20 "TemperatureRqstIndication_cmd_24_5C" 19 "TemperatureRqstIndication_cmd_24C" 18 "TemperatureRqstIndication_cmd_23_5C" 17 "TemperatureRqstIndication_cmd_23C" 16 "TemperatureRqstIndication_cmd_22_5C" 15 "TemperatureRqstIndication_cmd_22C" 14 "TemperatureRqstIndication_cmd_21_5C" 13 "TemperatureRqstIndication_cmd_21C" 12 "TemperatureRqstIndication_cmd_20_5C" 11 "TemperatureRqstIndication_cmd_20C" 10 "TemperatureRqstIndication_cmd_19_5C" 9 "TemperatureRqstIndication_cmd_19C" 8 "TemperatureRqstIndication_cmd_18_5C" 7 "TemperatureRqstIndication_cmd_18C" 6 "TemperatureRqstIndication_cmd_17_5C" 5 "TemperatureRqstIndication_cmd_17C" 4 "TemperatureRqstIndication_cmd_16_5C" 3 "TemperatureRqstIndication_cmd_16C" 2 "TemperatureRqstIndication_cmd_15C" 1 "TemperatureRqstIndication_cmd_Min" 0 "TemperatureRqstIndication_cmd_NoTempDisplayed" ;
VAL_ 2566356832 PHTimerTGWEvCmd_Timer3StartDay_I 15 "HeaterTimerStartDay_NotAvailable" 14 "HeaterTimerStartDay_Error" 13 "HeaterTimerStartDay_Spare_05" 12 "HeaterTimerStartDay_Spare_04" 11 "HeaterTimerStartDay_Spare_03" 10 "HeaterTimerStartDay_Spare_02" 9 "HeaterTimerStartDay_Spare_01" 8 "HeaterTimerStartDay_Spare" 7 "HeaterTimerStartDay_Sunday" 6 "HeaterTimerStartDay_Saturday" 5 "HeaterTimerStartDay_Friday" 4 "HeaterTimerStartDay_Thursday" 3 "HeaterTimerStartDay_Wednesday" 2 "HeaterTimerStartDay_Tuesday" 1 "HeaterTimerStartDay_Monday" 0 "HeaterTimerStartDay_NotUsed" ;
VAL_ 2566356832 PHTimerTGWEvCmd_Timer1Recur_ISig 15 "HeaterTimerRecurrence_NotAvailable" 14 "HeaterTimerRecurrence_Error" 13 "HeaterTimerRecurrence_Spare_3" 12 "HeaterTimerRecurrence_Spare_2" 11 "HeaterTimerRecurrence_Spare_1" 10 "HeaterTimerRecurrence_Sundays" 9 "HeaterTimerRecurrence_Saturdays" 8 "HeaterTimerRecurrence_Fridays" 7 "HeaterTimerRecurrence_Thursdays" 6 "HeaterTimerRecurrence_Wednesdays" 5 "HeaterTimerRecurrence_Tuesdays" 4 "HeaterTimerRecurrence_Mondays" 3 "HeaterTimerRecurrence_Weekends" 2 "HeaterTimerRecurrence_AllWeekdays" 1 "HeaterTimerRecurrence_Daily" 0 "HeaterTimerRecurrence_None" ;
VAL_ 2566356832 PHTimerTGWEvCmd_Timer3Recur_ISig 15 "HeaterTimerRecurrence_NotAvailable" 14 "HeaterTimerRecurrence_Error" 13 "HeaterTimerRecurrence_Spare_3" 12 "HeaterTimerRecurrence_Spare_2" 11 "HeaterTimerRecurrence_Spare_1" 10 "HeaterTimerRecurrence_Sundays" 9 "HeaterTimerRecurrence_Saturdays" 8 "HeaterTimerRecurrence_Fridays" 7 "HeaterTimerRecurrence_Thursdays" 6 "HeaterTimerRecurrence_Wednesdays" 5 "HeaterTimerRecurrence_Tuesdays" 4 "HeaterTimerRecurrence_Mondays" 3 "HeaterTimerRecurrence_Weekends" 2 "HeaterTimerRecurrence_AllWeekdays" 1 "HeaterTimerRecurrence_Daily" 0 "HeaterTimerRecurrence_None" ;
VAL_ 2566356832 PHTimerTGWEvCmd_Timer3Temp_ISig_ 31 "TemperatureRqstIndication_cmd_NotAvailable" 30 "TemperatureRqstIndication_cmd_Error" 29 "TemperatureRqstIndication_cmd_Spare_01" 28 "TemperatureRqstIndication_cmd_Spare" 27 "TemperatureRqstIndication_cmd_Max" 26 "TemperatureRqstIndication_cmd_29C" 25 "TemperatureRqstIndication_cmd_28C" 24 "TemperatureRqstIndication_cmd_27C" 23 "TemperatureRqstIndication_cmd_26C" 22 "TemperatureRqstIndication_cmd_25_5C" 21 "TemperatureRqstIndication_cmd_25C" 20 "TemperatureRqstIndication_cmd_24_5C" 19 "TemperatureRqstIndication_cmd_24C" 18 "TemperatureRqstIndication_cmd_23_5C" 17 "TemperatureRqstIndication_cmd_23C" 16 "TemperatureRqstIndication_cmd_22_5C" 15 "TemperatureRqstIndication_cmd_22C" 14 "TemperatureRqstIndication_cmd_21_5C" 13 "TemperatureRqstIndication_cmd_21C" 12 "TemperatureRqstIndication_cmd_20_5C" 11 "TemperatureRqstIndication_cmd_20C" 10 "TemperatureRqstIndication_cmd_19_5C" 9 "TemperatureRqstIndication_cmd_19C" 8 "TemperatureRqstIndication_cmd_18_5C" 7 "TemperatureRqstIndication_cmd_18C" 6 "TemperatureRqstIndication_cmd_17_5C" 5 "TemperatureRqstIndication_cmd_17C" 4 "TemperatureRqstIndication_cmd_16_5C" 3 "TemperatureRqstIndication_cmd_16C" 2 "TemperatureRqstIndication_cmd_15C" 1 "TemperatureRqstIndication_cmd_Min" 0 "TemperatureRqstIndication_cmd_NoTempDisplayed" ;
VAL_ 2566356832 PHTimerTGWEvCmd_PhTimer3_cmd_ISi 7 "PhTimer_cmd_NotAvailable" 6 "PhTimer_cmd_Error" 5 "PhTimer_cmd_Spare_02" 4 "PhTimer_cmd_Spare_01" 3 "PhTimer_cmd_TimerDeleted" 2 "PhTimer_cmd_TimerDisable" 1 "PhTimer_cmd_TimerEnable" 0 "PhTimer_cmd_NoAction" ;
VAL_ 2566356832 PHTimerTGWEvCmd_Timer1StartDay_I 15 "HeaterTimerStartDay_NotAvailable" 14 "HeaterTimerStartDay_Error" 13 "HeaterTimerStartDay_Spare_05" 12 "HeaterTimerStartDay_Spare_04" 11 "HeaterTimerStartDay_Spare_03" 10 "HeaterTimerStartDay_Spare_02" 9 "HeaterTimerStartDay_Spare_01" 8 "HeaterTimerStartDay_Spare" 7 "HeaterTimerStartDay_Sunday" 6 "HeaterTimerStartDay_Saturday" 5 "HeaterTimerStartDay_Friday" 4 "HeaterTimerStartDay_Thursday" 3 "HeaterTimerStartDay_Wednesday" 2 "HeaterTimerStartDay_Tuesday" 1 "HeaterTimerStartDay_Monday" 0 "HeaterTimerStartDay_NotUsed" ;
VAL_ 2566356832 PHTimerTGWEvCmd_Timer2StartDay_I 15 "HeaterTimerStartDay_NotAvailable" 14 "HeaterTimerStartDay_Error" 13 "HeaterTimerStartDay_Spare_05" 12 "HeaterTimerStartDay_Spare_04" 11 "HeaterTimerStartDay_Spare_03" 10 "HeaterTimerStartDay_Spare_02" 9 "HeaterTimerStartDay_Spare_01" 8 "HeaterTimerStartDay_Spare" 7 "HeaterTimerStartDay_Sunday" 6 "HeaterTimerStartDay_Saturday" 5 "HeaterTimerStartDay_Friday" 4 "HeaterTimerStartDay_Thursday" 3 "HeaterTimerStartDay_Wednesday" 2 "HeaterTimerStartDay_Tuesday" 1 "HeaterTimerStartDay_Monday" 0 "HeaterTimerStartDay_NotUsed" ;
VAL_ 2566356832 PHTimerTGWEvCmd_Timer2Temp_ISig_ 31 "TemperatureRqstIndication_cmd_NotAvailable" 30 "TemperatureRqstIndication_cmd_Error" 29 "TemperatureRqstIndication_cmd_Spare_01" 28 "TemperatureRqstIndication_cmd_Spare" 27 "TemperatureRqstIndication_cmd_Max" 26 "TemperatureRqstIndication_cmd_29C" 25 "TemperatureRqstIndication_cmd_28C" 24 "TemperatureRqstIndication_cmd_27C" 23 "TemperatureRqstIndication_cmd_26C" 22 "TemperatureRqstIndication_cmd_25_5C" 21 "TemperatureRqstIndication_cmd_25C" 20 "TemperatureRqstIndication_cmd_24_5C" 19 "TemperatureRqstIndication_cmd_24C" 18 "TemperatureRqstIndication_cmd_23_5C" 17 "TemperatureRqstIndication_cmd_23C" 16 "TemperatureRqstIndication_cmd_22_5C" 15 "TemperatureRqstIndication_cmd_22C" 14 "TemperatureRqstIndication_cmd_21_5C" 13 "TemperatureRqstIndication_cmd_21C" 12 "TemperatureRqstIndication_cmd_20_5C" 11 "TemperatureRqstIndication_cmd_20C" 10 "TemperatureRqstIndication_cmd_19_5C" 9 "TemperatureRqstIndication_cmd_19C" 8 "TemperatureRqstIndication_cmd_18_5C" 7 "TemperatureRqstIndication_cmd_18C" 6 "TemperatureRqstIndication_cmd_17_5C" 5 "TemperatureRqstIndication_cmd_17C" 4 "TemperatureRqstIndication_cmd_16_5C" 3 "TemperatureRqstIndication_cmd_16C" 2 "TemperatureRqstIndication_cmd_15C" 1 "TemperatureRqstIndication_cmd_Min" 0 "TemperatureRqstIndication_cmd_NoTempDisplayed" ;
VAL_ 2566356832 PHTimerTGWEvCmd_PhTimer2_cmd_ISi 7 "PhTimer_cmd_NotAvailable" 6 "PhTimer_cmd_Error" 5 "PhTimer_cmd_Spare_02" 4 "PhTimer_cmd_Spare_01" 3 "PhTimer_cmd_TimerDeleted" 2 "PhTimer_cmd_TimerDisable" 1 "PhTimer_cmd_TimerEnable" 0 "PhTimer_cmd_NoAction" ;
VAL_ 2566356832 PHTimerTGWEvCmd_Timer2Recur_ISig 15 "HeaterTimerRecurrence_NotAvailable" 14 "HeaterTimerRecurrence_Error" 13 "HeaterTimerRecurrence_Spare_3" 12 "HeaterTimerRecurrence_Spare_2" 11 "HeaterTimerRecurrence_Spare_1" 10 "HeaterTimerRecurrence_Sundays" 9 "HeaterTimerRecurrence_Saturdays" 8 "HeaterTimerRecurrence_Fridays" 7 "HeaterTimerRecurrence_Thursdays" 6 "HeaterTimerRecurrence_Wednesdays" 5 "HeaterTimerRecurrence_Tuesdays" 4 "HeaterTimerRecurrence_Mondays" 3 "HeaterTimerRecurrence_Weekends" 2 "HeaterTimerRecurrence_AllWeekdays" 1 "HeaterTimerRecurrence_Daily" 0 "HeaterTimerRecurrence_None" ;
VAL_ 2566356832 PHTimerTGWEvCmd_PhTimer1_cmd_ISi 7 "PhTimer_cmd_NotAvailable" 6 "PhTimer_cmd_Error" 5 "PhTimer_cmd_Spare_02" 4 "PhTimer_cmd_Spare_01" 3 "PhTimer_cmd_TimerDeleted" 2 "PhTimer_cmd_TimerDisable" 1 "PhTimer_cmd_TimerEnable" 0 "PhTimer_cmd_NoAction" ;
VAL_ 2515671136 Trailer2LiftAxles_LiftAxle1Pos_I 3 "TrailerLiftAxlePos_NotAvailable" 2 "TrailerLiftAxlePos_Error" 1 "TrailerLiftAxlePos_AxleLifted" 0 "TrailerLiftAxlePos_AxleDown" ;
VAL_ 2515671136 Trailer1LiftAxles_LiftAxle2Pos_I 3 "TrailerLiftAxlePos_NotAvailable" 2 "TrailerLiftAxlePos_Error" 1 "TrailerLiftAxlePos_AxleLifted" 0 "TrailerLiftAxlePos_AxleDown" ;
VAL_ 2515671136 Trailer3LiftAxles_LiftAxle2Pos_I 3 "TrailerLiftAxlePos_NotAvailable" 2 "TrailerLiftAxlePos_Error" 1 "TrailerLiftAxlePos_AxleLifted" 0 "TrailerLiftAxlePos_AxleDown" ;
VAL_ 2515671136 Trailer1LiftAxles_LiftAxle1Pos_I 3 "TrailerLiftAxlePos_NotAvailable" 2 "TrailerLiftAxlePos_Error" 1 "TrailerLiftAxlePos_AxleLifted" 0 "TrailerLiftAxlePos_AxleDown" ;
VAL_ 2515671136 Trailer4LiftAxles_LiftAxle2Pos_I 3 "TrailerLiftAxlePos_NotAvailable" 2 "TrailerLiftAxlePos_Error" 1 "TrailerLiftAxlePos_AxleLifted" 0 "TrailerLiftAxlePos_AxleDown" ;
VAL_ 2515671136 Trailer5LiftAxles_LiftAxle2Pos_I 3 "TrailerLiftAxlePos_NotAvailable" 2 "TrailerLiftAxlePos_Error" 1 "TrailerLiftAxlePos_AxleLifted" 0 "TrailerLiftAxlePos_AxleDown" ;
VAL_ 2515671136 Trailer4LiftAxles_LiftAxle1Pos_I 3 "TrailerLiftAxlePos_NotAvailable" 2 "TrailerLiftAxlePos_Error" 1 "TrailerLiftAxlePos_AxleLifted" 0 "TrailerLiftAxlePos_AxleDown" ;
VAL_ 2515671136 Trailer5LiftAxles_LiftAxle1Pos_I 3 "TrailerLiftAxlePos_NotAvailable" 2 "TrailerLiftAxlePos_Error" 1 "TrailerLiftAxlePos_AxleLifted" 0 "TrailerLiftAxlePos_AxleDown" ;
VAL_ 2515671136 Trailer2LiftAxles_LiftAxle2Pos_I 3 "TrailerLiftAxlePos_NotAvailable" 2 "TrailerLiftAxlePos_Error" 1 "TrailerLiftAxlePos_AxleLifted" 0 "TrailerLiftAxlePos_AxleDown" ;
VAL_ 2515671136 Trailer3LiftAxles_LiftAxle1Pos_I 3 "TrailerLiftAxlePos_NotAvailable" 2 "TrailerLiftAxlePos_Error" 1 "TrailerLiftAxlePos_AxleLifted" 0 "TrailerLiftAxlePos_AxleDown" ;
VAL_ 2515671136 InhibRegeneration_DeviceInd 3 "DeviceIndication_SpareValue" 2 "DeviceIndication_Blink" 1 "DeviceIndication_On" 0 "DeviceIndication_Off" ;
VAL_ 2482917472 RefrigTimerRqstAck_CurrentOp 3 "CurrentOp_NotAvailable" 2 "CurrentOp_Disabled" 1 "CurrentOp_TemporaryStopped" 0 "CurrentOp_Running" ;
VAL_ 2482917472 RefrigTimerRqstAck_DayOfWeekRq 15 "DayOfWeekRq_NotAvailable" 14 "DayOfWeekRq_Error" 13 "DayOfWeekRq_Spare_7" 12 "DayOfWeekRq_Spare_6" 11 "DayOfWeekRq_Spare_5" 10 "DayOfWeekRq_Spare_4" 9 "DayOfWeekRq_Spare_3" 8 "DayOfWeekRq_Spare_2" 7 "DayOfWeekRq_NoDay" 6 "DayOfWeekRq_Sunday" 5 "DayOfWeekRq_Saturday" 4 "DayOfWeekRq_Friday" 3 "DayOfWeekRq_Thursday" 2 "DayOfWeekRq_Wednesday" 1 "DayOfWeekRq_Tuesday" 0 "DayOfWeekRq_Monday" ;
VAL_ 2482917472 RemoteParkingClimateRqst_ISig_4 7 "RemoteParkingClimateRqst_NotAvailable" 6 "RemoteParkingClimateRqst_Error" 5 "RemoteParkingClimateRqst_Spare_03" 4 "RemoteParkingClimateRqst_Spare_02" 3 "RemoteParkingClimateRqst_Spare_01" 2 "RemoteParkingClimateRqst_DisableRequest" 1 "RemoteParkingClimateRqst_EnableRequest" 0 "RemoteParkingClimateRqst_NoAction" ;
VAL_ 2482917472 RegenerationIndication 3 "DeviceIndication_SpareValue" 2 "DeviceIndication_Blink" 1 "DeviceIndication_On" 0 "DeviceIndication_Off" ;
VAL_ 2482917472 TPMIndicationLightReq 3 "Request_NotAvailable" 2 "Request_Error" 1 "Request_RequestActive" 0 "Request_NotRequested" ;
VAL_ 2482917472 PHTimerRqstAck_DayOfWeekRq_ISig_ 15 "DayOfWeekRq_NotAvailable" 14 "DayOfWeekRq_Error" 13 "DayOfWeekRq_Spare_7" 12 "DayOfWeekRq_Spare_6" 11 "DayOfWeekRq_Spare_5" 10 "DayOfWeekRq_Spare_4" 9 "DayOfWeekRq_Spare_3" 8 "DayOfWeekRq_Spare_2" 7 "DayOfWeekRq_NoDay" 6 "DayOfWeekRq_Sunday" 5 "DayOfWeekRq_Saturday" 4 "DayOfWeekRq_Friday" 3 "DayOfWeekRq_Thursday" 2 "DayOfWeekRq_Wednesday" 1 "DayOfWeekRq_Tuesday" 0 "DayOfWeekRq_Monday" ;
VAL_ 2482917472 PHTimerRqstAck_CurrentOp_ISig_4 3 "CurrentOp_NotAvailable" 2 "CurrentOp_Disabled" 1 "CurrentOp_TemporaryStopped" 0 "CurrentOp_Running" ;
VAL_ 2482917472 Regeneration_DeviceInd 15 "DualDeviceIndication_UpperDontCareLowerDontCare" 14 "DualDeviceIndication_UpperBlinkLowerDontCare" 13 "DualDeviceIndication_UpperOnLowerDontCare" 12 "DualDeviceIndication_UpperOffLowerDontCare" 11 "DualDeviceIndication_UpperDontCareLowerBlink" 10 "DualDeviceIndication_UpperBlinkLowerBlink" 9 "DualDeviceIndication_UpperOnLowerBlink" 8 "DualDeviceIndication_UpperOffLowerBlink" 7 "DualDeviceIndication_UpperDontCareLowerOn" 6 "DualDeviceIndication_UpperBlinkLowerOn" 5 "DualDeviceIndication_UpperOnLowerOn" 4 "DualDeviceIndication_UpperOffLowerOn" 3 "DualDeviceIndication_UpperDontCareLowerOff" 2 "DualDeviceIndication_UpperBlinkLowerOff" 1 "DualDeviceIndication_UpperOnLowerOff" 0 "DualDeviceIndication_UpperOffLowerOff" ;
VAL_ 2515822432 AlarmClockNotification_ID_ISig_4 127 "AlarmClkID_NotAvailable" 126 "AlarmClkID_Error" 10 "AlarmClkID_Alarm10" 9 "AlarmClkID_Alarm9" 8 "AlarmClkID_Alarm8" 7 "AlarmClkID_Alarm7" 6 "AlarmClkID_Alarm6" 5 "AlarmClkID_Alarm5" 4 "AlarmClkID_Alarm4" 3 "AlarmClkID_Alarm3" 2 "AlarmClkID_Alarm2" 1 "AlarmClkID_Alarm1" 0 "AlarmClkID_NotUsed" ;
VAL_ 2515822432 AlarmClockNotification_Type_ISig 7 "AlarmClkType_NotAvailable" 6 "AlarmClkType_Error" 5 "AlarmClkType_Reserved_02" 4 "AlarmClkType_Reserved_01" 3 "AlarmClkType_Reserved" 2 "AlarmClkType_Radio" 1 "AlarmClkType_Buzzer" 0 "AlarmClkType_NoAudibleNotification" ;
VAL_ 2515822432 ExtraHeating_rqst_ISig_4 7 "ActivationRequest_NotAvailable" 6 "ActivationRequest_Error" 5 "ActivationRequest_Spare3" 4 "ActivationRequest_Spare2" 3 "ActivationRequest_Spare1" 2 "ActivationRequest_AutoStart" 1 "ActivationRequest_Off" 0 "ActivationRequest_NoAction" ;
VAL_ 2515822432 AlarmClockNotification_Stat_ISig 3 "AlarmClkStat_Spare" 2 "AlarmClkStat_NoUsed" 1 "AlarmClkStat_Active" 0 "AlarmClkStat_Inactive" ;
VAL_ 2515822432 HillDataCtrlTGW_State_ISig_4 7 "HillDataState_NotAvailable" 6 "HillDataState_Error" 5 "HillDataState_Spare_03" 4 "HillDataState_Spare_02" 3 "HillDataState_Spare_01" 2 "HillDataState_Receive" 1 "HillDataState_Request" 0 "HillDataState_Idle" ;
VAL_ 2565490016 DPF_AshLevelRequest 3 "InactiveActive_NotAvailable" 2 "InactiveActive_Error" 1 "InactiveActive_Active" 0 "InactiveActive_Inactive" ;
VAL_ 2565490016 DPF_RegenerationConditionsReq 3 "InactiveActive_NotAvailable" 2 "InactiveActive_Error" 1 "InactiveActive_Active" 0 "InactiveActive_Inactive" ;
VAL_ 2565490016 SCR_SulphurRegenRqst 3 "RegenRqst_NotAvailable" 2 "RegenRqst_Error" 1 "RegenRqst_RegenerationRequested" 0 "RegenRqst_RegenerationNotRequested" ;
VAL_ 2565490016 DPF_ManualRegenerateInhibit 3 "InactiveActive_NotAvailable" 2 "InactiveActive_Error" 1 "InactiveActive_Active" 0 "InactiveActive_Inactive" ;
VAL_ 2565490016 DPF_SootLevelRequest 3 "InactiveActive_NotAvailable" 2 "InactiveActive_Error" 1 "InactiveActive_Active" 0 "InactiveActive_Inactive" ;
VAL_ 2565490016 DPF_ManualRegenerateRequest_ISig 3 "Request_NotAvailable" 2 "Request_Error" 1 "Request_RequestActive" 0 "Request_NotRequested" ;
VAL_ 2566268256 GPSData_AntennaStat_ISig_4_18f62 7 "GPS_Antenna_status_NA" 6 "GPS_Antenna_status_ErrorIndicator" 5 "GPS_Antenna_status_SpareValue_01" 4 "GPS_Antenna_status_SpareValue" 3 "GPS_Antenna_status_AntennaStatusUnknown" 2 "GPS_Antenna_status_AntennaInit" 1 "GPS_Antenna_status_AntennaDisconnected" 0 "GPS_Antenna_status_AntennaStatusOK" ;
VAL_ 2566268000 GPSData_AntennaStat_ISig_4__0000 7 "GPS_Antenna_status_NA" 6 "GPS_Antenna_status_ErrorIndicator" 5 "GPS_Antenna_status_SpareValue_01" 4 "GPS_Antenna_status_SpareValue" 3 "GPS_Antenna_status_AntennaStatusUnknown" 2 "GPS_Antenna_status_AntennaInit" 1 "GPS_Antenna_status_AntennaDisconnected" 0 "GPS_Antenna_status_AntennaStatusOK" ;
VAL_ 2566268512 GPSData_AntennaStat_ISig_4__0001 7 "GPS_Antenna_status_NA" 6 "GPS_Antenna_status_ErrorIndicator" 5 "GPS_Antenna_status_SpareValue_01" 4 "GPS_Antenna_status_SpareValue" 3 "GPS_Antenna_status_AntennaStatusUnknown" 2 "GPS_Antenna_status_AntennaInit" 1 "GPS_Antenna_status_AntennaDisconnected" 0 "GPS_Antenna_status_AntennaStatusOK" ;
VAL_ 2566269024 GPSData_AntennaStat_ISig_4__0002 7 "GPS_Antenna_status_NA" 6 "GPS_Antenna_status_ErrorIndicator" 5 "GPS_Antenna_status_SpareValue_01" 4 "GPS_Antenna_status_SpareValue" 3 "GPS_Antenna_status_AntennaStatusUnknown" 2 "GPS_Antenna_status_AntennaInit" 1 "GPS_Antenna_status_AntennaDisconnected" 0 "GPS_Antenna_status_AntennaStatusOK" ;
VAL_ 2566268768 GPSData_AntennaStat_ISig_4__0003 7 "GPS_Antenna_status_NA" 6 "GPS_Antenna_status_ErrorIndicator" 5 "GPS_Antenna_status_SpareValue_01" 4 "GPS_Antenna_status_SpareValue" 3 "GPS_Antenna_status_AntennaStatusUnknown" 2 "GPS_Antenna_status_AntennaInit" 1 "GPS_Antenna_status_AntennaDisconnected" 0 "GPS_Antenna_status_AntennaStatusOK" ;
VAL_ 2566846816 Trailer5Type_ISig_4 7 "TrailerType_NotAvailable" 6 "TrailerType_Error" 5 "TrailerType_NotConnected" 4 "TrailerType_Unknown" 3 "TrailerType_Dolly" 2 "TrailerType_DrawbarTrailer" 1 "TrailerType_CentreAxleTrailer" 0 "TrailerType_SemiTrailer" ;
VAL_ 2566846816 Trailer3Type_ISig_4 7 "TrailerType_NotAvailable" 6 "TrailerType_Error" 5 "TrailerType_NotConnected" 4 "TrailerType_Unknown" 3 "TrailerType_Dolly" 2 "TrailerType_DrawbarTrailer" 1 "TrailerType_CentreAxleTrailer" 0 "TrailerType_SemiTrailer" ;
VAL_ 2566846816 Trailer1Type_ISig_4 7 "TrailerType_NotAvailable" 6 "TrailerType_Error" 5 "TrailerType_NotConnected" 4 "TrailerType_Unknown" 3 "TrailerType_Dolly" 2 "TrailerType_DrawbarTrailer" 1 "TrailerType_CentreAxleTrailer" 0 "TrailerType_SemiTrailer" ;
VAL_ 2566846816 Trailer4Type_ISig_4 7 "TrailerType_NotAvailable" 6 "TrailerType_Error" 5 "TrailerType_NotConnected" 4 "TrailerType_Unknown" 3 "TrailerType_Dolly" 2 "TrailerType_DrawbarTrailer" 1 "TrailerType_CentreAxleTrailer" 0 "TrailerType_SemiTrailer" ;
VAL_ 2566846816 Trailer2Type_ISig_4 7 "TrailerType_NotAvailable" 6 "TrailerType_Error" 5 "TrailerType_NotConnected" 4 "TrailerType_Unknown" 3 "TrailerType_Dolly" 2 "TrailerType_DrawbarTrailer" 1 "TrailerType_CentreAxleTrailer" 0 "TrailerType_SemiTrailer" ;
VAL_ 2515802464 AlarmClockAlarms_stat_Mode_ISig_ 3 "AlarmClkMode_Spare" 2 "AlarmClkMode_Timer" 1 "AlarmClkMode_Recurrent" 0 "AlarmClkMode_OneTime" ;
VAL_ 2515802464 AlarmClockAlarms_stat_Type_ISig_ 7 "AlarmClkType_NotAvailable" 6 "AlarmClkType_Error" 5 "AlarmClkType_Reserved_02" 4 "AlarmClkType_Reserved_01" 3 "AlarmClkType_Reserved" 2 "AlarmClkType_Radio" 1 "AlarmClkType_Buzzer" 0 "AlarmClkType_NoAudibleNotification" ;
VAL_ 2515802464 AlarmClockAlarms_stat_ID_ISig_4 127 "AlarmClkID_NotAvailable" 126 "AlarmClkID_Error" 10 "AlarmClkID_Alarm10" 9 "AlarmClkID_Alarm9" 8 "AlarmClkID_Alarm8" 7 "AlarmClkID_Alarm7" 6 "AlarmClkID_Alarm6" 5 "AlarmClkID_Alarm5" 4 "AlarmClkID_Alarm4" 3 "AlarmClkID_Alarm3" 2 "AlarmClkID_Alarm2" 1 "AlarmClkID_Alarm1" 0 "AlarmClkID_NotUsed" ;
VAL_ 2515802464 AlarmClockAlarms_stat_Stat_ISig_ 3 "AlarmClkStat2_Snoozed" 2 "AlarmClkStat2_Ringing" 1 "AlarmClkStat2_Active" 0 "AlarmClkStat2_Inactive" ;
VAL_ 2515802464 AlmClkCurAlarm_stat_Stat 3 "AlarmClkStat_Spare" 2 "AlarmClkStat_NoUsed" 1 "AlarmClkStat_Active" 0 "AlarmClkStat_Inactive" ;
VAL_ 2515802464 AlmClkCurAlarm_stat_ID 127 "AlarmClkID_NotAvailable" 126 "AlarmClkID_Error" 10 "AlarmClkID_Alarm10" 9 "AlarmClkID_Alarm9" 8 "AlarmClkID_Alarm8" 7 "AlarmClkID_Alarm7" 6 "AlarmClkID_Alarm6" 5 "AlarmClkID_Alarm5" 4 "AlarmClkID_Alarm4" 3 "AlarmClkID_Alarm3" 2 "AlarmClkID_Alarm2" 1 "AlarmClkID_Alarm1" 0 "AlarmClkID_NotUsed" ;
VAL_ 2515802464 AlmClkCurAlarm_stat_Type 7 "AlarmClkType_NotAvailable" 6 "AlarmClkType_Error" 5 "AlarmClkType_Reserved_02" 4 "AlarmClkType_Reserved_01" 3 "AlarmClkType_Reserved" 2 "AlarmClkType_Radio" 1 "AlarmClkType_Buzzer" 0 "AlarmClkType_NoAudibleNotification" ;
VAL_ 2499801297 DriverNewOilQuality 7 "OilQuality_NotAvailable" 6 "OilQuality_Error" 5 "OilQuality_NoSelectionMade" 4 "OilQuality_VDS4" 3 "OilQuality_VDS3" 2 "OilQuality_VDS2" 1 "OilQuality_VDSVDS3WithFixedInterval" 0 "OilQuality_NonVDS_VDS4WithFixedInterval" ;
VAL_ 2499801297 DynamicCode_rqst 7 "DynamicCode_rqst_NotAvailable" 6 "DynamicCode_rqst_Error" 1 "DynamicCode_rqst_DynamicCodeRequest" 0 "DynamicCode_rqst_Idle" ;
VAL_ 2499801297 FrontWheelDriveMenuRequest 3 "AutomaticOffOn_NotAvailable" 2 "AutomaticOffOn_Error" 1 "AutomaticOffOn_AutomaticOn" 0 "AutomaticOffOn_AutomaticOff" ;
VAL_ 2499801297 DriverNewBatteryCapacity 15 "BatteryType_NotAvailable" 14 "BatteryType_Error" 13 "BatteryType_NoSelectionMade" 12 "BatteryType_OtherBatteryType" 11 "BatteryType_BatteryType11" 10 "BatteryType_BatteryType10" 9 "BatteryType_BatteryType9" 8 "BatteryType_BatteryType8" 7 "BatteryType_BatteryType7" 6 "BatteryType_BatteryType6" 5 "BatteryType_BatteryType5" 4 "BatteryType_BatteryType4" 3 "BatteryType_BatteryType3" 2 "BatteryType_BatteryType2" 1 "BatteryType_BatteryType1" 0 "BatteryType_BatteryType0" ;
VAL_ 2499794044 FirstAxleLowerPrioRequested_ISig 7 "FirstAxleLowerPrio_NotAvailable" 6 "FirstAxleLowerPrio_Error" 5 "FirstAxleLowerPrio_Reserved_03" 4 "FirstAxleLowerPrio_Reserved_02" 3 "FirstAxleLowerPrio_Reserved_01" 2 "FirstAxleLowerPrio_Reserved" 1 "FirstAxleLowerPrio_LowerPusher" 0 "FirstAxleLowerPrio_LowerTag" ;
VAL_ 2499794044 MaintInfo_rqst_ISig_4 3 "Request_NotAvailable" 2 "Request_Error" 1 "Request_RequestActive" 0 "Request_NotRequested" ;
VAL_ 2499794044 Synch_Unsynch_Mode_stat 7 "Synch_Unsynch_Mode_stat_NotAvailable" 6 "Synch_Unsynch_Mode_stat_Error" 5 "Synch_Unsynch_Mode_stat_Spare_02" 4 "Synch_Unsynch_Mode_stat_Spare_01" 3 "Synch_Unsynch_Mode_stat_Spare" 2 "Synch_Unsynch_Mode_stat_UnsynchronizedMode" 1 "Synch_Unsynch_Mode_stat_SynchronizedMode" 0 "Synch_Unsynch_Mode_stat_Idle" ;
VAL_ 2499794044 MaintResetRqst_ID 63 "MaintID_NotAvailable" 62 "MaintID_Error" 39 "MaintID_Monitor39" 38 "MaintID_Monitor38" 37 "MaintID_Monitor37" 36 "MaintID_Monitor36" 35 "MaintID_Monitor35" 34 "MaintID_Monitor34" 33 "MaintID_Monitor33" 32 "MaintID_Monitor32" 31 "MaintID_Monitor31" 30 "MaintID_Monitor30" 29 "MaintID_Monitor29" 28 "MaintID_Monitor28" 27 "MaintID_Monitor27" 26 "MaintID_Monitor26" 25 "MaintID_Monitor25" 24 "MaintID_Monitor24" 23 "MaintID_Monitor23" 22 "MaintID_Monitor22" 21 "MaintID_Monitor21" 20 "MaintID_Monitor20" 19 "MaintID_Monitor19" 18 "MaintID_Monitor18" 17 "MaintID_Monitor17" 16 "MaintID_Monitor16" 15 "MaintID_Monitor15" 14 "MaintID_Monitor14" 13 "MaintID_Monitor13" 12 "MaintID_Monitor12" 11 "MaintID_Monitor11" 10 "MaintID_Monitor10" 9 "MaintID_Monitor9" 8 "MaintID_Monitor8" 7 "MaintID_Monitor7" 6 "MaintID_Monitor6" 5 "MaintID_Monitor5" 4 "MaintID_Monitor4" 3 "MaintID_Monitor3" 2 "MaintID_Monitor2" 1 "MaintID_Monitor1" 0 "MaintID_Monitor0" ;
VAL_ 2499794044 TrailerBrakeInputStatus 7 "TrailerBrakeInputStatus_NotAvailable" 6 "TrailerBrakeInputStatus_Error" 5 "TrailerBrakeInputStatus_Spare_02" 4 "TrailerBrakeInputStatus_Spare_01" 3 "TrailerBrakeInputStatus_Spare" 2 "TrailerBrakeInputStatus_Step2" 1 "TrailerBrakeInputStatus_Step1" 0 "TrailerBrakeInputStatus_NoRequest_Step0" ;
VAL_ 2499794044 MaintResetRqst_StatusRqst 3 "Request_NotAvailable" 2 "Request_Error" 1 "Request_RequestActive" 0 "Request_NotRequested" ;
VAL_ 2499794044 SelectedSpeedUnit_stat_ISig_4 3 "SpeedUnit_NotAvailable" 2 "SpeedUnit_Error" 1 "SpeedUnit_MilesPerHour" 0 "SpeedUnit_KilometersPerHour" ;
VAL_ 2499794044 SelectedLanguage_stat_ISig_4 63 "Language_NotAvailable" 62 "Language_Error" 61 "Language_Spare_26" 60 "Language_Spare_25" 59 "Language_Spare_24" 58 "Language_Spare_23" 57 "Language_Spare_22" 56 "Language_Spare_21" 55 "Language_Spare_20" 54 "Language_Spare_19" 53 "Language_Spare_18" 52 "Language_Spare_17" 51 "Language_Spare_16" 50 "Language_Spare_15" 49 "Language_Spare_14" 48 "Language_Spare_13" 47 "Language_Spare_12" 46 "Language_Spare_11" 45 "Language_Spare_10" 44 "Language_Spare_09" 43 "Language_Spare_08" 42 "Language_Spare_07" 41 "Language_Spare_06" 40 "Language_Spare_05" 39 "Language_Spare_04" 38 "Language_Malay_Indonesian" 37 "Language_Ukrainian" 36 "Language_Bosnian" 35 "Language_Croatian" 34 "Language_Numeric" 33 "Language_Japanese" 32 "Language_Korean" 31 "Language_Chinese" 30 "Language_Thai" 29 "Language_Arabic" 28 "Language_Farsi" 27 "Language_Hebrew" 26 "Language_Turkish" 25 "Language_Hungarian" 24 "Language_Slovak" 23 "Language_Czech" 22 "Language_Slovenian" 21 "Language_Serbian" 20 "Language_Greek" 19 "Language_Bulgarian" 18 "Language_Italian" 17 "Language_Dutch" 16 "Language_Rumanian" 15 "Language_BrazilianPortugese" 14 "Language_Portugese" 13 "Language_Spanish" 12 "Language_French" 11 "Language_German" 10 "Language_Polish" 9 "Language_Lituanian" 8 "Language_Latvian" 7 "Language_Estonian" 6 "Language_Russian" 5 "Language_Finish" 4 "Language_Icelandic" 3 "Language_Norwegian" 2 "Language_Danish" 1 "Language_Swedish" 0 "Language_English" ;
VAL_ 2499794044 LampCheck_rqst_ISig_4 3 "LampCheck_NotAvailable" 2 "LampCheck_Error" 1 "LampCheck_PerformLampCheck" 0 "LampCheck_NoAction" ;
VAL_ 2499794044 ParkingHeaterCleaning_cmd_ISig_4 3 "ParkingHeaterCleaning_cmd_NotAvailable" 2 "ParkingHeaterCleaning_cmd_Escaped" 1 "ParkingHeaterCleaning_cmd_Activated" 0 "ParkingHeaterCleaning_cmd_NoAction" ;
VAL_ 2499794044 SelectedWeightUnit_stat_ISig_4 3 "WeightUnit_NotAvailable" 2 "WeightUnit_Error" 1 "WeightUnit_Pound" 0 "WeightUnit_Kg" ;
VAL_ 2499794044 SpeedLockingInhibition_stat 7 "SpeedLockingInhibition_stat_NotAvailable" 6 "SpeedLockingInhibition_stat_Error" 2 "SpeedLockingInhibition_stat_SpeedLockingDeactivate" 1 "SpeedLockingInhibition_stat_SpeedLockingActivate" 0 "SpeedLockingInhibition_stat_Idle" ;
VAL_ 2499794044 MaintInfoRqst 3 "Request_NotAvailable" 2 "Request_Error" 1 "Request_RequestActive" 0 "Request_NotRequested" ;
VAL_ 2499794044 ParkHeaterTimerReleased_stat_ISi 3 "DisableEnable_NotAvailable" 2 "DisableEnable_Error" 1 "DisableEnable_Enable" 0 "DisableEnable_Disable" ;
VAL_ 2499794044 DriverMemory_rqst_ISig_4 31 "DriverMemory_rqst_Error" 30 "DriverMemory_rqst_NotAvailable" 29 "DriverMemory_rqst_Spare_07" 28 "DriverMemory_rqst_Spare_06" 27 "DriverMemory_rqst_Spare_05" 26 "DriverMemory_rqst_Spare_04" 25 "DriverMemory_rqst_Spare_03" 24 "DriverMemory_rqst_Spare_02" 23 "DriverMemory_rqst_Spare_01" 22 "DriverMemory_rqst_Spare" 21 "DriverMemory_rqst_ResetAllMemThenUseDefDriverMem" 20 "DriverMemory_rqst_ResetAndThenUseDriverMemory10" 19 "DriverMemory_rqst_ResetAndThenUseDriverMemory9" 18 "DriverMemory_rqst_ResetAndThenUseDriverMemory8" 17 "DriverMemory_rqst_ResetAndThenUseDriverMemory7" 16 "DriverMemory_rqst_ResetAndThenUseDriverMemory6" 15 "DriverMemory_rqst_ResetAndThenUseDriverMemory5" 14 "DriverMemory_rqst_ResetAndThenUseDriverMemory4" 13 "DriverMemory_rqst_ResetAndThenUseDriverMemory3" 12 "DriverMemory_rqst_ResetAndThenUseDriverMemory2" 11 "DriverMemory_rqst_ResetAndThenUseDriverMemory1" 10 "DriverMemory_rqst_UseDriverMemory10" 9 "DriverMemory_rqst_UseDriverMemory9" 8 "DriverMemory_rqst_UseDriverMemory8" 7 "DriverMemory_rqst_UseDriverMemory7" 6 "DriverMemory_rqst_UseDriverMemory6" 5 "DriverMemory_rqst_UseDriverMemory5" 4 "DriverMemory_rqst_UseDriverMemory4" 3 "DriverMemory_rqst_UseDriverMemory3" 2 "DriverMemory_rqst_UseDriverMemory2" 1 "DriverMemory_rqst_UseDriverMemory1" 0 "DriverMemory_rqst_UseDefaultDriverMemory" ;
VAL_ 2499794044 SelectedTimeFormat_stat_ISig_4 3 "TimeFormatStat_NotAvailable" 2 "TimeFormatStat_Error" 1 "TimeFormatStat_24h" 0 "TimeFormatStat_AM_PM" ;
VAL_ 2499794044 RefrigTimerReleased_stat 3 "DisableEnable_NotAvailable" 2 "DisableEnable_Error" 1 "DisableEnable_Enable" 0 "DisableEnable_Disable" ;
VAL_ 2499794044 LCSSoundSettingRequest 3 "LCSSoundSettingRequest_NotAvailable" 2 "LCSSoundSettingRequest_Error" 1 "LCSSoundSettingRequest_EnableLCSSound" 0 "LCSSoundSettingRequest_DisableLCSSound" ;
SIG_GROUP_ 2565494112 TPMSetPresThresCfg_sg_ISig_4 1 : TPMSetPresThresCfg_VehiclePos_IS TPMSetPresThresCfg_ExtOverPres_I TPMSetPresThresCfg_AxleNr_ISig_4 TPMSetPresThresCfg_OverPres_ISig TPMSetPresThresCfg_ExtUnderPres_ TPMSetPresThresCfg_UnderPres_ISi;
SIG_GROUP_ 2565494112 TPMSetAxleTireConfig_sg_ISig_4 1 : TPMSetAxleTireConfig_Axle4_ISig_ TPMSetAxleTireConfig_Axle5_ISig_ TPMSetAxleTireConfig_Axle2_ISig_ TPMSetAxleTireConfig_VehiclePos_ TPMSetAxleTireConfig_Axle3_ISig_ TPMSetAxleTireConfig_Axle1_ISig_;
SIG_GROUP_ 2566356832 PHTimerTGWEvCmd_sg_ISig_4 1 : PHTimerTGWEvCmd_Timer3Minutes_IS PHTimerTGWEvCmd_Timer1Temp_ISig_ PHTimerTGWEvCmd_Timer3StartDay_I PHTimerTGWEvCmd_Timer1Recur_ISig PHTimerTGWEvCmd_Timer3Recur_ISig PHTimerTGWEvCmd_Timer3Temp_ISig_ PHTimerTGWEvCmd_PhTimer3_cmd_ISi PHTimerTGWEvCmd_Timer1Hours_ISig PHTimerTGWEvCmd_Timer1StartDay_I PHTimerTGWEvCmd_Timer2Minutes_IS PHTimerTGWEvCmd_Timer2StartDay_I PHTimerTGWEvCmd_Timer2Temp_ISig_ PHTimerTGWEvCmd_Timer1Duration_I PHTimerTGWEvCmd_Timer2Hours_ISig PHTimerTGWEvCmd_Timer3Hours_ISig PHTimerTGWEvCmd_PhTimer2_cmd_ISi PHTimerTGWEvCmd_Timer2Recur_ISig PHTimerTGWEvCmd_Timer1Minutes_IS PHTimerTGWEvCmd_PhTimer1_cmd_ISi;
SIG_GROUP_ 2515671136 Trailer5LiftAxles_sg_ISig_4 1 : Trailer5LiftAxles_LiftAxle1Id_IS Trailer5LiftAxles_LiftAxle2Pos_I Trailer5LiftAxles_LiftAxle1Pos_I Trailer5LiftAxles_LiftAxle2Id_IS;
SIG_GROUP_ 2515671136 Trailer1LiftAxles_sg_ISig_4 1 : Trailer1LiftAxles_LiftAxle2Pos_I Trailer1LiftAxles_LiftAxle2Id_IS Trailer1LiftAxles_LiftAxle1Pos_I Trailer1LiftAxles_LiftAxle1Id_IS;
SIG_GROUP_ 2515671136 Trailer4LiftAxles_sg_ISig_4 1 : Trailer4LiftAxles_LiftAxle2Pos_I Trailer4LiftAxles_LiftAxle1Pos_I Trailer4LiftAxles_LiftAxle1Id_IS Trailer4LiftAxles_LiftAxle2Id_IS;
SIG_GROUP_ 2515671136 Trailer3LiftAxles_sg_ISig_4 1 : Trailer3LiftAxles_LiftAxle1Id_IS Trailer3LiftAxles_LiftAxle2Pos_I Trailer3LiftAxles_LiftAxle1Pos_I Trailer3LiftAxles_LiftAxle2Id_IS;
SIG_GROUP_ 2515671136 Trailer2LiftAxles_sg_ISig_4 1 : Trailer2LiftAxles_LiftAxle1Pos_I Trailer2LiftAxles_LiftAxle1Id_IS Trailer2LiftAxles_LiftAxle2Pos_I Trailer2LiftAxles_LiftAxle2Id_IS;
SIG_GROUP_ 2482917472 RefrigTimerRqstAck_sg 1 : RefrigTimerRqstAck_CurrentOp RefrigTimerRqstAck_DayOfWeekRq RefrigTimerRqstAck_Hours RefrigTimerRqstAck_Minutes;
SIG_GROUP_ 2482917472 PHTimerRqstAck_sg_ISig_4 1 : PHTimerRqstAck_Minutes_ISig_4 PHTimerRqstAck_Hours_ISig_4 PHTimerRqstAck_DayOfWeekRq_ISig_ PHTimerRqstAck_CurrentOp_ISig_4;
SIG_GROUP_ 2515822432 AlarmClockNotification_sg_ISig_4 1 : AlarmClockNotification_ID_ISig_4 AlarmClockNotification_Type_ISig AlarmClockNotification_Stat_ISig;
SIG_GROUP_ 2515822432 HillDataCtrlTGW_sg_ISig_4 1 : HillDataCtrlTGW_State_ISig_4 HillDataCtrlTGW_AckCnt_ISig_4;
SIG_GROUP_ 2566268256 GPSData_sg_ISig_4_18f62560 1 : GPSData_Longitude_ISig_4_18f6256 GPSData_Direction_ISig_4_18f6256 GPSData_Latitude_ISig_4_18f62560 GPSData_Altitude_ISig_4_18f62560 GPSData_HDOP_ISig_4_18f62560 GPSData_Time_ISig_4_18f62560 GPSData_VehSpeed_ISig_4_18f62560 GPSData_AntennaStat_ISig_4_18f62;
SIG_GROUP_ 2566268000 GPSData_sg_ISig_4_18f62460 1 : GPSData_HDOP_ISig_4_18f62460 GPSData_VehSpeed_ISig_4_18f62460 GPSData_Direction_ISig_4_18f6246 GPSData_Longitude_ISig_4_18f6246 GPSData_Time_ISig_4_18f62460 GPSData_Latitude_ISig_4_18f62460 GPSData_AntennaStat_ISig_4__0000 GPSData_Altitude_ISig_4_18f62460;
SIG_GROUP_ 2566268512 GPSData_sg_ISig_4_18f62660 1 : GPSData_HDOP_ISig_4_18f62660 GPSData_VehSpeed_ISig_4_18f62660 GPSData_AntennaStat_ISig_4__0001 GPSData_Latitude_ISig_4_18f62660 GPSData_Time_ISig_4_18f62660 GPSData_Direction_ISig_4_18f6266 GPSData_Longitude_ISig_4_18f6266 GPSData_Altitude_ISig_4_18f62660;
SIG_GROUP_ 2566269024 GPSData_sg_ISig_4_18f62860 1 : GPSData_HDOP_ISig_4_18f62860 GPSData_Latitude_ISig_4_18f62860 GPSData_Time_ISig_4_18f62860 GPSData_Direction_ISig_4_18f6286 GPSData_AntennaStat_ISig_4__0002 GPSData_Longitude_ISig_4_18f6286 GPSData_VehSpeed_ISig_4_18f62860 GPSData_Altitude_ISig_4_18f62860;
SIG_GROUP_ 2566268768 GPSData_sg_ISig_4_18f62760 1 : GPSData_Time_ISig_4_18f62760 GPSData_HDOP_ISig_4_18f62760 GPSData_Direction_ISig_4_18f6276 GPSData_Longitude_ISig_4_18f6276 GPSData_VehSpeed_ISig_4_18f62760 GPSData_Altitude_ISig_4_18f62760 GPSData_Latitude_ISig_4_18f62760 GPSData_AntennaStat_ISig_4__0003;
SIG_GROUP_ 2566802272 Trailer5CalAxleLoad_sg_ISig_4 1 : Trailer5CalAxleLoad_AxleId_ISig_ Trailer5CalAxleLoad_AxleLoad_ISi;
SIG_GROUP_ 2566757728 Trailer4CalAxleLoad_sg_ISig_4 1 : Trailer4CalAxleLoad_AxleId_ISig_ Trailer4CalAxleLoad_AxleLoad_ISi;
SIG_GROUP_ 2566713184 Trailer3CalAxleLoad_sg_ISig_4 1 : Trailer3CalAxleLoad_AxleLoad_ISi Trailer3CalAxleLoad_AxleId_ISig_;
SIG_GROUP_ 2566668640 Trailer2CalAxleLoad_sg_ISig_4 1 : Trailer2CalAxleLoad_AxleId_ISig_ Trailer2CalAxleLoad_AxleLoad_ISi;
SIG_GROUP_ 2566624096 Trailer1CalAxleLoad_sg_ISig_4 1 : Trailer1CalAxleLoad_AxleLoad_ISi Trailer1CalAxleLoad_AxleId_ISig_;
SIG_GROUP_ 2515802464 AlmClkCurAlarm_stat_sg 1 : AlmClkCurAlarm_stat_SetMin AlmClkCurAlarm_stat_Stat AlmClkCurAlarm_stat_ID AlmClkCurAlarm_stat_Type AlmClkCurAlarm_stat_SetHr;
SIG_GROUP_ 2515802464 AlarmClockAlarms_stat_sg_ISig_4 1 : AlarmClockAlarms_stat_Mode_ISig_ AlarmClockAlarms_stat_Type_ISig_ AlarmClockAlarms_stat_DaySet_ISi AlarmClockAlarms_stat_ID_ISig_4 AlarmClockAlarms_stat_Stat_ISig_ AlarmClockAlarms_stat_SetMin_ISi AlarmClockAlarms_stat_SetHr_ISig;
SIG_GROUP_ 2499794044 MaintResetRqst_sg 1 : MaintResetRqst_ID MaintResetRqst_StatusRqst;
